VERSION ""

NS_ :

BS_:

BU_: CHUD_LS VKM_LS RCRM_LS MSM_RR_LS MSM_LR_LS CGM_LS BSM_LS VPM_LS ISRVM_LS DCAC_LS TouchPad_LS RSC_LS LVMPC_LS EOCM2B_K1_LS EOCM2A_K1_LS LCM_LS TIM_B_LS V2V_LS TCP_LS CSM_LS EOCM2B_K2_LS EOCM2A_K2_LS TIM_A_LS LVMNav_LS HFP_LS EDI_LS ARB_LS RSE_LS Dummy_LS VIS2_LS ICS_LS FCM_LS EOCM_F_LS VICM_LS AGC_LS MSM_P_LS OTIM_LS HVSM_R_LS HVSM_F_LS DVB_T_LS SBZA_R_LS PSD_R_LS PSD_L_LS UHP_Low UPA_LS STC_LS SBZA_L_LS PTM_LS ONSTAR_LS APA_LS TestTool_LS PHS_LS PDIM_LS CHM_LS RSA_LS AMP_LS HUD_LS MSM_LS HBSM_LS SCL_LS ECC_LS RadioHead_LS PEPS_LS IPC_LS AOS_LS SDM_LS TIM_LS BCM_LS

BO_ 2156298240 High_Volt_Batt_Time_Pwr_Chrg_LS: 8 VICM_LS
 SG_ HTRActvIndOn : 59|1@0+ (1,0) [0|1] ""  CGM_LS,IPC_LS
 SG_ HVBSTLPC_MntOfHr : 53|6@0+ (1,0) [0|63] "Minute"  BCM_LS,CGM_LS,CSM_LS,RadioHead_LS,IPC_LS
 SG_ HVBSTLPC_HrOfDy : 42|5@0+ (1,0) [0|31] "Hour"  BCM_LS,CGM_LS,CSM_LS,RadioHead_LS,IPC_LS
 SG_ HVBSTLPC_DyOfWk : 45|3@0+ (1,0) [0|7] ""  BCM_LS,CGM_LS,CSM_LS,RadioHead_LS,IPC_LS
 SG_ HVBSTHPC_MntOfHr : 35|6@0+ (1,0) [0|63] "Minute"  BCM_LS,CGM_LS,CSM_LS,RadioHead_LS,IPC_LS
 SG_ HVBSTHPC_HrOfDy : 24|5@0+ (1,0) [0|31] "Hour"  BCM_LS,CGM_LS,CSM_LS,RadioHead_LS,IPC_LS
 SG_ HVBSTHPC_DyOfWk : 27|3@0+ (1,0) [0|7] ""  BCM_LS,CGM_LS,CSM_LS,RadioHead_LS,IPC_LS
 SG_ HVBCTLPC_MntOfHr : 17|6@0+ (1,0) [0|63] "Minute"  BCM_LS,CGM_LS,CSM_LS,RadioHead_LS,IPC_LS
 SG_ HVBCTLPC_HrOfDy : 22|5@0+ (1,0) [0|31] "Hour"  BCM_LS,CGM_LS,CSM_LS,RadioHead_LS,IPC_LS
 SG_ HVBCTLPC_DyOfWk : 9|3@0+ (1,0) [0|7] ""  BCM_LS,CGM_LS,CSM_LS,RadioHead_LS,IPC_LS
 SG_ HVBCTHPC_MntOfHr : 15|6@0+ (1,0) [0|63] "Minute"  BCM_LS,CGM_LS,CSM_LS,RadioHead_LS,IPC_LS
 SG_ HVBCTHPC_HrOfDy : 4|5@0+ (1,0) [0|31] "Hour"  BCM_LS,CGM_LS,CSM_LS,RadioHead_LS,IPC_LS
 SG_ HVBCTHPC_DyOfWk : 7|3@0+ (1,0) [0|7] ""  BCM_LS,CGM_LS,CSM_LS,RadioHead_LS,IPC_LS
 SG_ InvldHMIEtrIO : 61|1@0+ (1,0) [0|1] ""  CGM_LS,CSM_LS,RadioHead_LS
 SG_ InsfcntTmTFlChrgIO : 60|1@0+ (1,0) [0|1] ""  CGM_LS,CSM_LS,RadioHead_LS
 SG_ HVBatChrgCrdAlrtReq : 63|2@0+ (1,0) [0|3] ""  CSM_LS,CGM_LS,RadioHead_LS,BCM_LS
 SG_ HVCSDTES_NPDTIO : 56|1@0+ (1,0) [0|1] ""  BCM_LS,CGM_LS,CSM_LS,RadioHead_LS
 SG_ HVCSDTES_LoPwrCIO : 58|1@0+ (1,0) [0|1] ""  BCM_LS,CGM_LS,CSM_LS,RadioHead_LS
 SG_ HVCSDTES_HiPwrCIO : 57|1@0+ (1,0) [0|1] ""  BCM_LS,CGM_LS,CSM_LS,RadioHead_LS

BO_ 2149924864 Drv_Pref_Mode_Switch_Status_LS: 8 BCM_LS
 SG_ PTOMobModTrnsInGrIO : 15|1@0+ (1,0) [0|1] ""  CGM_LS,IPC_LS
 SG_ a_12VBatSysUnstab : 55|1@0+ (1,0) [0|1] ""  IPC_LS,CGM_LS
 SG_ FwdClnMtgnBrkReqAct : 7|1@0+ (1,0) [0|1] ""  CGM_LS,FCM_LS
 SG_ TireRRLowTracIO : 54|1@0+ (1,0) [0|1] ""  CSM_LS,CGM_LS,IPC_LS
 SG_ TireRFLowTracIO : 53|1@0+ (1,0) [0|1] ""  CSM_LS,CGM_LS,IPC_LS
 SG_ TireLRLowTracIO : 52|1@0+ (1,0) [0|1] ""  CSM_LS,CGM_LS,IPC_LS
 SG_ TireLFLowTracIO : 51|1@0+ (1,0) [0|1] ""  CSM_LS,CGM_LS,IPC_LS
 SG_ HilRlbkCtrlActIO : 6|1@0+ (1,0) [0|1] ""  CGM_LS,IPC_LS
 SG_ FstIdlMdAct : 39|1@0+ (1,0) [0|1] ""  CGM_LS,IPC_LS
 SG_ DsplyPerfMdRq : 50|3@0+ (1,0) [0|7] ""  CGM_LS,IPC_LS
 SG_ DrvSelMd8Stat : 37|1@0+ (1,0) [0|1] ""  CSM_LS,RadioHead_LS,FCM_LS,CGM_LS,IPC_LS,ECC_LS
 SG_ DrvSelMd8ReqDnd : 38|1@0+ (1,0) [0|1] ""  CSM_LS,RadioHead_LS,CGM_LS,IPC_LS
 SG_ DrvSelMd7Stat : 35|1@0+ (1,0) [0|1] ""  CSM_LS,RadioHead_LS,FCM_LS,CGM_LS,IPC_LS,ECC_LS
 SG_ DrvSelMd7ReqDnd : 36|1@0+ (1,0) [0|1] ""  CSM_LS,RadioHead_LS,CGM_LS,IPC_LS
 SG_ DrvSelMd6Stat : 13|1@0+ (1,0) [0|1] ""  CSM_LS,RadioHead_LS,FCM_LS,CGM_LS,IPC_LS,ECC_LS
 SG_ DrvSelMd6ReqDnd : 14|1@0+ (1,0) [0|1] ""  CSM_LS,RadioHead_LS,CGM_LS,IPC_LS
 SG_ DrvSelMd5Stat : 11|1@0+ (1,0) [0|1] ""  CSM_LS,RadioHead_LS,FCM_LS,CGM_LS,IPC_LS,ECC_LS
 SG_ DrvSelMd5ReqDnd : 12|1@0+ (1,0) [0|1] ""  CGM_LS,IPC_LS,CSM_LS,RadioHead_LS
 SG_ DrvSelMd4Stat : 9|1@0+ (1,0) [0|1] ""  CSM_LS,RadioHead_LS,FCM_LS,CGM_LS,IPC_LS,ECC_LS
 SG_ DrvSelMd4ReqDnd : 10|1@0+ (1,0) [0|1] ""  CSM_LS,RadioHead_LS,CGM_LS,IPC_LS
 SG_ EDADS_RcmndtFwdGr : 43|4@0+ (1,0) [0|15] ""  CSM_LS,CGM_LS,IPC_LS
 SG_ EDADS_CrntFwdMsdG : 47|4@0+ (1,0) [0|15] ""  CSM_LS,CGM_LS,IPC_LS
 SG_ EDADS_ShftIndStat : 33|2@0+ (1,0) [0|3] ""  CSM_LS,CGM_LS,IPC_LS
 SG_ EDADS_EcoDrvShftIO : 34|1@0+ (1,0) [0|1] ""  CSM_LS,CGM_LS,IPC_LS
 SG_ DSMSS_DrvSelMd0Pn : 24|1@0+ (1,0) [0|1] ""  CGM_LS,CSM_LS,RadioHead_LS,IPC_LS
 SG_ DSMSS_DrvSelMd8Pn : 25|1@0+ (1,0) [0|1] ""  CGM_LS,CSM_LS,RadioHead_LS,IPC_LS
 SG_ DSMSS_DrvSelMd7Pn : 26|1@0+ (1,0) [0|1] ""  CGM_LS,CSM_LS,RadioHead_LS,IPC_LS
 SG_ DSMSS_DrvSelMd6Pn : 27|1@0+ (1,0) [0|1] ""  CGM_LS,CSM_LS,RadioHead_LS,IPC_LS
 SG_ DSMSS_DrvSelMd5Pn : 28|1@0+ (1,0) [0|1] ""  CGM_LS,CSM_LS,RadioHead_LS,IPC_LS
 SG_ DSMSS_DrvSelMd4Pn : 29|1@0+ (1,0) [0|1] ""  CGM_LS,CSM_LS,RadioHead_LS,IPC_LS
 SG_ DSMSS_DrvSelMd3Pn : 30|1@0+ (1,0) [0|1] ""  CGM_LS,CSM_LS,RadioHead_LS,IPC_LS
 SG_ DSMSS_DrvSelMd2Pn : 31|1@0+ (1,0) [0|1] ""  CGM_LS,CSM_LS,RadioHead_LS,IPC_LS
 SG_ DSMSS_DrvSelMd1Pn : 16|1@0+ (1,0) [0|1] ""  CGM_LS,CSM_LS,RadioHead_LS,IPC_LS
 SG_ DSMSS_DrvSelMd8Un : 17|1@0+ (1,0) [0|1] ""  CGM_LS,CSM_LS,RadioHead_LS,IPC_LS
 SG_ DSMSS_DrvSelMd7Un : 18|1@0+ (1,0) [0|1] ""  CGM_LS,CSM_LS,RadioHead_LS,IPC_LS
 SG_ DSMSS_DrvSelMd6Un : 19|1@0+ (1,0) [0|1] ""  CGM_LS,CSM_LS,RadioHead_LS,IPC_LS
 SG_ DSMSS_DrvSelMd5Un : 20|1@0+ (1,0) [0|1] ""  CGM_LS,CSM_LS,RadioHead_LS,IPC_LS
 SG_ DSMSS_DrvSelMd4Un : 21|1@0+ (1,0) [0|1] ""  CGM_LS,CSM_LS,RadioHead_LS,IPC_LS
 SG_ DSMSS_DrvSelMd3Un : 22|1@0+ (1,0) [0|1] ""  CGM_LS,CSM_LS,RadioHead_LS,IPC_LS
 SG_ DSMSS_DrvSelMd2Un : 23|1@0+ (1,0) [0|1] ""  CGM_LS,CSM_LS,RadioHead_LS,IPC_LS
 SG_ DSMSS_DrvSelMd1Un : 8|1@0+ (1,0) [0|1] ""  CGM_LS,CSM_LS,RadioHead_LS,IPC_LS
 SG_ DrvSelMd3Stat : 4|1@0+ (1,0) [0|1] ""  FCM_LS,CGM_LS,CSM_LS,RadioHead_LS,BSM_LS,VICM_LS,IPC_LS,ECC_LS
 SG_ DrvSelMd3ReqDnd : 5|1@0+ (1,0) [0|1] ""  CSM_LS,RadioHead_LS,CGM_LS,IPC_LS
 SG_ DrvSelMd2Stat : 2|1@0+ (1,0) [0|1] ""  FCM_LS,CGM_LS,CSM_LS,RadioHead_LS,BSM_LS,VICM_LS,IPC_LS,ECC_LS
 SG_ DrvSelMd2ReqDnd : 3|1@0+ (1,0) [0|1] ""  CGM_LS,IPC_LS,CSM_LS,RadioHead_LS
 SG_ DrvSelMd1Stat : 0|1@0+ (1,0) [0|1] ""  FCM_LS,CGM_LS,CSM_LS,RadioHead_LS,BSM_LS,VICM_LS,IPC_LS,ECC_LS
 SG_ DrvSelMd1ReqDnd : 1|1@0+ (1,0) [0|1] ""  CGM_LS,CSM_LS,RadioHead_LS,IPC_LS
 SG_ CPSCA_Resrv3Avail : 56|1@0+ (1,0) [0|1] ""  CGM_LS,CSM_LS,RadioHead_LS
 SG_ CPSCA_Resrv2Avail : 57|1@0+ (1,0) [0|1] ""  CGM_LS,CSM_LS,RadioHead_LS
 SG_ CPSCA_Resrv1Avail : 58|1@0+ (1,0) [0|1] ""  CGM_LS,CSM_LS,RadioHead_LS
 SG_ CPSCA_AlrtBrkStrAvail : 59|1@0+ (1,0) [0|1] ""  CGM_LS,CSM_LS,RadioHead_LS
 SG_ CPSCA_AlrtBrkAvail : 60|1@0+ (1,0) [0|1] ""  CGM_LS,CSM_LS,RadioHead_LS
 SG_ CPSCA_AlrtAvail : 61|1@0+ (1,0) [0|1] ""  CGM_LS,CSM_LS,RadioHead_LS
 SG_ CPSCA_OffAvail : 62|1@0+ (1,0) [0|1] ""  CGM_LS,CSM_LS,RadioHead_LS

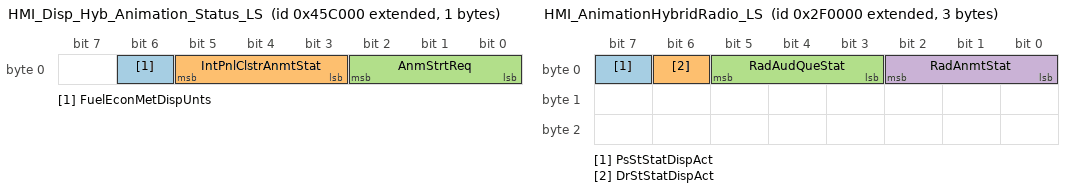
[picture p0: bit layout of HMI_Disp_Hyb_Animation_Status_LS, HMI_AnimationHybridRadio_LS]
BO_ 2152054784 HMI_Disp_Hyb_Animation_Status_LS: 1 IPC_LS
 SG_ FuelEconMetDispUnts : 6|1@0+ (1,0) [0|1] ""  RadioHead_LS,BSM_LS,VICM_LS
 SG_ IntPnlClstrAnmtStat : 5|3@0+ (1,0) [0|7] ""  RadioHead_LS,CHUD_LS,HUD_LS
 SG_ AnmStrtReq : 2|3@0+ (1,0) [0|7] ""  RadioHead_LS,CHUD_LS,HUD_LS

BO_ 2150301696 HMI_Animation_Initiator_LS: 1 BCM_LS
 SG_ WlcAnmReq : 0|1@0+ (1,0) [0|1] ""  CGM_LS,RadioHead_LS,IPC_LS

BO_ 2150563840 HMI_AnimationHybridRadio_LS: 3 RadioHead_LS
 SG_ PsStStatDispAct : 7|1@0+ (1,0) [0|1] ""  MSM_P_LS
 SG_ DrStStatDispAct : 6|1@0+ (1,0) [0|1] ""  MSM_LS
 SG_ RadAudQueStat : 5|3@0+ (1,0) [0|7] "" Vector__XXX
 SG_ RadAnmtStat : 2|3@0+ (1,0) [0|7] "" Vector__XXX

BO_ 2154758144 Auxiliary_Heater_Active_LS: 1 BCM_LS
 SG_ ChldLckOtSwAct : 1|1@0+ (1,0) [0|1] ""  CGM_LS,MSM_LR_LS,MSM_RR_LS

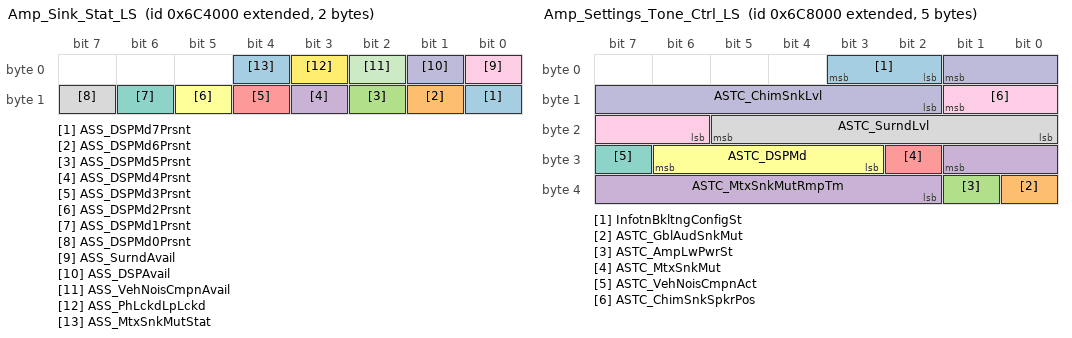
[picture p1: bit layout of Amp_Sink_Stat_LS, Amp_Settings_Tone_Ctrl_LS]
BO_ 2154577920 Amp_Sink_Stat_LS: 2 AMP_LS
 SG_ ASS_DSPMd7Prsnt : 8|1@0+ (1,0) [0|1] ""  CGM_LS,CSM_LS
 SG_ ASS_DSPMd6Prsnt : 9|1@0+ (1,0) [0|1] ""  CGM_LS,CSM_LS
 SG_ ASS_DSPMd5Prsnt : 10|1@0+ (1,0) [0|1] ""  CGM_LS,CSM_LS
 SG_ ASS_DSPMd4Prsnt : 11|1@0+ (1,0) [0|1] ""  CGM_LS,CSM_LS
 SG_ ASS_DSPMd3Prsnt : 12|1@0+ (1,0) [0|1] ""  CGM_LS,CSM_LS
 SG_ ASS_DSPMd2Prsnt : 13|1@0+ (1,0) [0|1] ""  CGM_LS,CSM_LS
 SG_ ASS_DSPMd1Prsnt : 14|1@0+ (1,0) [0|1] ""  CGM_LS,CSM_LS
 SG_ ASS_DSPMd0Prsnt : 15|1@0+ (1,0) [0|1] ""  CGM_LS,CSM_LS
 SG_ ASS_SurndAvail : 0|1@0+ (1,0) [0|1] ""  CGM_LS,CSM_LS
 SG_ ASS_DSPAvail : 1|1@0+ (1,0) [0|1] ""  CGM_LS,CSM_LS
 SG_ ASS_VehNoisCmpnAvail : 2|1@0+ (1,0) [0|1] ""  CGM_LS,CSM_LS
 SG_ ASS_PhLckdLpLckd : 3|1@0+ (1,0) [0|1] ""  CGM_LS,CSM_LS
 SG_ ASS_MtxSnkMutStat : 4|1@0+ (1,0) [0|1] ""  CGM_LS,CSM_LS

BO_ 2154594304 Amp_Settings_Tone_Ctrl_LS: 5 CSM_LS
 SG_ InfotnBkltngConfigSt : 3|2@0+ (1,0) [0|3] ""  CGM_LS,RSE_LS,TouchPad_LS
 SG_ ASTC_GblAudSnkMut : 32|1@0+ (1,0) [0|1] ""  CGM_LS,AMP_LS
 SG_ ASTC_AmpLwPwrSt : 33|1@0+ (1,0) [0|1] ""  CGM_LS,AMP_LS
 SG_ ASTC_MtxSnkMutRmpTm : 25|8@0+ (5,0) [0|1275] "ms"  CGM_LS,AMP_LS
 SG_ ASTC_MtxSnkMut : 26|1@0+ (1,0) [0|1] ""  CGM_LS,AMP_LS
 SG_ ASTC_DSPMd : 30|4@0+ (1,0) [0|15] ""  CGM_LS,AMP_LS
 SG_ ASTC_VehNoisCmpnAct : 31|1@0+ (1,0) [0|1] ""  CGM_LS,AMP_LS
 SG_ ASTC_SurndLvl : 21|6@0- (1,0) [-32|31] ""  CGM_LS,AMP_LS
 SG_ ASTC_ChimSnkSpkrPos : 9|4@0+ (1,0) [0|15] ""  CGM_LS,AMP_LS
 SG_ ASTC_ChimSnkLvl : 1|8@0+ (0.5,-127.5) [-127.5|0] "dB"  CGM_LS,AMP_LS

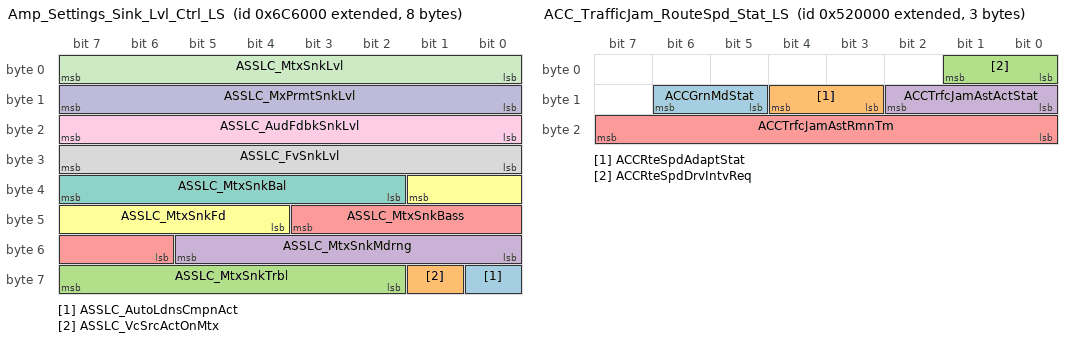
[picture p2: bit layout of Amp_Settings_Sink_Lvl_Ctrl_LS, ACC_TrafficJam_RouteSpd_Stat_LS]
BO_ 2154586112 Amp_Settings_Sink_Lvl_Ctrl_LS: 8 CSM_LS
 SG_ ASSLC_AutoLdnsCmpnAct : 56|1@0+ (1,0) [0|1] ""  CGM_LS,AMP_LS
 SG_ ASSLC_VcSrcActOnMtx : 57|1@0+ (1,0) [0|1] ""  CGM_LS,AMP_LS
 SG_ ASSLC_MtxSnkTrbl : 63|6@0- (1,0) [-32|31] ""  CGM_LS,AMP_LS
 SG_ ASSLC_MtxSnkMdrng : 53|6@0- (1,0) [-32|31] ""  CGM_LS,AMP_LS
 SG_ ASSLC_MtxSnkBass : 43|6@0- (1,0) [-32|31] ""  CGM_LS,AMP_LS
 SG_ ASSLC_MtxSnkFd : 33|6@0- (1,0) [-32|31] ""  CGM_LS,AMP_LS
 SG_ ASSLC_MtxSnkBal : 39|6@0- (1,0) [-32|31] ""  CGM_LS,AMP_LS
 SG_ ASSLC_FvSnkLvl : 31|8@0+ (0.5,-127.5) [-127.5|0] "dB"  CGM_LS,AMP_LS
 SG_ ASSLC_AudFdbkSnkLvl : 23|8@0+ (0.5,-127.5) [-127.5|0] "dB"  CGM_LS,AMP_LS
 SG_ ASSLC_MxPrmtSnkLvl : 15|8@0+ (0.5,-127.5) [-127.5|0] "dB"  CGM_LS,AMP_LS
 SG_ ASSLC_MtxSnkLvl : 7|8@0+ (0.5,-127.5) [-127.5|0] "dB"  CGM_LS,AMP_LS

BO_ 2152857600 ACC_TrafficJam_RouteSpd_Stat_LS: 3 FCM_LS
 SG_ ACCGrnMdStat : 14|2@0+ (1,0) [0|3] ""  CSM_LS,ONSTAR_LS,CGM_LS,IPC_LS
 SG_ ACCRteSpdAdaptStat : 12|2@0+ (1,0) [0|3] ""  CSM_LS,CGM_LS,IPC_LS
 SG_ ACCRteSpdDrvIntvReq : 1|2@0+ (1,0) [0|3] ""  CGM_LS,IPC_LS
 SG_ ACCTrfcJamAstActStat : 10|3@0+ (1,0) [0|7] ""  CGM_LS,IPC_LS
 SG_ ACCTrfcJamAstRmnTm : 23|8@0+ (1,0) [0|255] "sec"  CGM_LS,IPC_LS

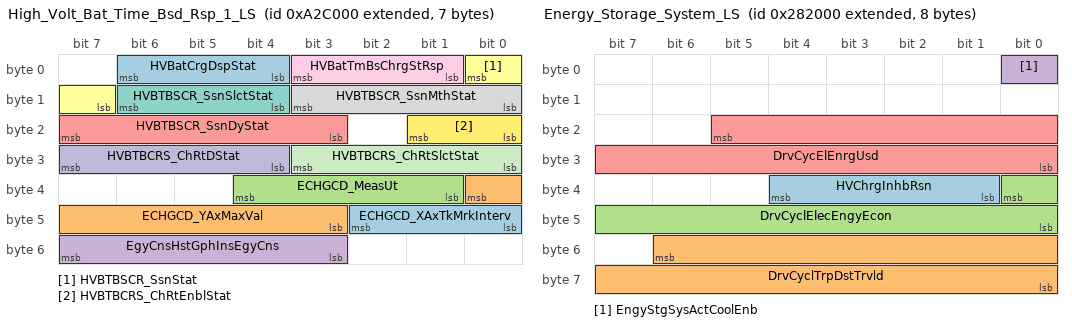
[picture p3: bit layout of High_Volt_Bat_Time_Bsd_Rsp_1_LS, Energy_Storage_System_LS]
BO_ 2158149632 High_Volt_Bat_Time_Bsd_Rsp_1_LS: 7 VICM_LS
 SG_ ECHGCD_XAxTkMrkInterv : 42|3@0+ (1,0) [0|7] ""  CSM_LS,RadioHead_LS,CGM_LS
 SG_ ECHGCD_YAxMaxVal : 32|6@0+ (4,0) [0|252] ""  CSM_LS,RadioHead_LS,CGM_LS
 SG_ ECHGCD_MeasUt : 36|4@0+ (1,0) [0|15] ""  CSM_LS,RadioHead_LS,CGM_LS
 SG_ EgyCnsHstGphInsEgyCns : 55|5@0+ (1,0) [0|31] ""  CGM_LS,CSM_LS,RadioHead_LS
 SG_ HVBTBSCR_SsnDyStat : 23|5@0+ (1,0) [0|31] "day"  CGM_LS,CSM_LS,RadioHead_LS
 SG_ HVBTBSCR_SsnStat : 0|2@0+ (1,0) [0|3] ""  CGM_LS,CSM_LS,RadioHead_LS
 SG_ HVBTBSCR_SsnSlctStat : 14|3@0+ (1,0) [0|7] ""  CGM_LS,CSM_LS,RadioHead_LS
 SG_ HVBTBSCR_SsnMthStat : 11|4@0+ (1,0) [0|15] ""  CGM_LS,CSM_LS,RadioHead_LS
 SG_ HVBatTmBsChrgStRsp : 3|3@0+ (1,0) [0|7] ""  BCM_LS,CGM_LS,CSM_LS,RadioHead_LS
 SG_ HVBTBCRS_ChRtDStat : 31|4@0+ (1,0) [0|15] ""  CGM_LS,CSM_LS,RadioHead_LS
 SG_ HVBTBCRS_ChRtSlctStat : 27|4@0+ (1,0) [0|15] ""  CGM_LS,CSM_LS,RadioHead_LS
 SG_ HVBTBCRS_ChRtEnblStat : 17|2@0+ (1,0) [0|3] ""  CGM_LS,CSM_LS,RadioHead_LS
 SG_ HVBatCrgDspStat : 6|3@0+ (1,0) [0|7] ""  CSM_LS,CGM_LS,RadioHead_LS,BCM_LS

BO_ 2158116864 High_Volt_Bat_Time_Bsd_Rsp_LS: 8 VICM_LS
 SG_ SrvcHghVltBatIndReq : 37|2@0+ (1,0) [0|3] ""  CGM_LS,IPC_LS
 SG_ ChrgStPkInScnActIO : 35|1@0+ (1,0) [0|1] ""  IPC_LS,CGM_LS
 SG_ HVBatStrtTmDspFrmt : 15|3@0+ (1,0) [0|7] ""  CSM_LS,RadioHead_LS,CGM_LS
 SG_ OBHVBCMinsRmng : 5|6@0+ (1,0) [0|63] ""  CSM_LS,RadioHead_LS,IPC_LS,CGM_LS
 SG_ OBHVBCCompTmDispFrmt : 7|2@0+ (1,0) [0|3] ""  CSM_LS,RadioHead_LS,IPC_LS,CGM_LS
 SG_ HVBTBRCR_RtCHSlctTblRwStat : 58|3@0+ (1,0) [0|7] "rows"  CGM_LS,CSM_LS,RadioHead_LS
 SG_ HVBTBRCR_RtChSlctStat : 42|3@0+ (1,0) [0|7] ""  CGM_LS,CSM_LS,RadioHead_LS
 SG_ HVBTBRCR_RtChSlRtStat : 62|4@0+ (1,0) [0|15] ""  CGM_LS,CSM_LS,RadioHead_LS
 SG_ HVBTBRCR_RtChSsnStat : 34|2@0+ (1,0) [0|3] ""  CGM_LS,CSM_LS,RadioHead_LS
 SG_ HVBTBRCR_RtChMHRsp : 32|6@0+ (1,0) [0|63] "min"  CGM_LS,CSM_LS,RadioHead_LS
 SG_ HVBTBRCR_RtChHRsp : 55|5@0+ (1,0) [0|31] "hr"  CGM_LS,CSM_LS,RadioHead_LS
 SG_ HVBTBRCR_RtChDStat : 50|4@0+ (1,0) [0|15] ""  CGM_LS,CSM_LS,RadioHead_LS
 SG_ HVBTBDCRS_DlChSlctStat : 19|4@0+ (1,0) [0|15] ""  BCM_LS,CGM_LS,CSM_LS,RadioHead_LS
 SG_ HVBTBDCRS_DlChSsnStat : 31|2@0+ (1,0) [0|3] ""  BCM_LS,CGM_LS,CSM_LS,RadioHead_LS
 SG_ HVBTBDCRS_DlChMHRsp : 29|6@0+ (1,0) [0|63] "min"  BCM_LS,CGM_LS,CSM_LS,RadioHead_LS
 SG_ HVBTBDCRS_DlChHRsp : 12|5@0+ (1,0) [0|31] "hr"  BCM_LS,CGM_LS,CSM_LS,RadioHead_LS
 SG_ HVBTBDCRS_DlChDStat : 23|4@0+ (1,0) [0|15] ""  BCM_LS,CGM_LS,CSM_LS,RadioHead_LS

BO_ 2156281856 High_Volt_Bat_Time_Bsd_Req_1_LS: 7 RadioHead_LS
 SG_ LftmEffDtRstRqd : 18|1@0+ (1,0) [0|1] ""  VICM_LS
 SG_ HTRCsStReq : 37|3@0+ (1,0) [0|7] ""  VICM_LS
 SG_ TODCTmpImdtOvrdReq : 39|2@0+ (1,0) [0|3] ""  BSM_LS,VICM_LS
 SG_ RtBsChrgCmplnTmPrfReq : 34|2@0+ (1,0) [0|3] ""  BSM_LS,VICM_LS
 SG_ TONPDTR_StTmpOvrAtv : 32|2@0+ (1,0) [0|3] ""  BSM_LS,VICM_LS
 SG_ TONPDTR_MntOfHr : 53|6@0+ (1,0) [0|63] "Minute"  BSM_LS,VICM_LS
 SG_ TONPDTR_HrOfDy : 42|5@0+ (1,0) [0|31] "Hour"  BSM_LS,VICM_LS
 SG_ TONPDTR_DyOfWk : 46|4@0+ (1,0) [0|15] ""  BSM_LS,VICM_LS
 SG_ StTODChrgTmpOvrd : 7|1@0+ (1,0) [0|1] ""  BSM_LS,VICM_LS
 SG_ HVBTBSCSR_SsnStReq : 0|2@0+ (1,0) [0|3] ""  BSM_LS,VICM_LS
 SG_ HVBTBSCSR_SsnSlStReq : 14|3@0+ (1,0) [0|7] ""  BSM_LS,VICM_LS
 SG_ HVBTBSCSR_SsnMthStReq : 11|4@0+ (1,0) [0|15] ""  BSM_LS,VICM_LS
 SG_ HVBTBSCSR_SsnDayStReq : 23|5@0+ (1,0) [0|31] "day"  BSM_LS,VICM_LS
 SG_ HVBTBCRSR_ChRtSlStReq : 27|4@0+ (1,0) [0|15] ""  BSM_LS,VICM_LS
 SG_ HVBTBCRSR_ChRtEnblStReq : 17|2@0+ (1,0) [0|3] ""  BSM_LS,VICM_LS
 SG_ HVBTBCRSR_ChRtDStReq : 31|4@0+ (1,0) [0|15] ""  BSM_LS,VICM_LS
 SG_ HVBatTmBsChrgMdReq : 3|3@0+ (1,0) [0|7] ""  BSM_LS,VICM_LS
 SG_ HVChgSyChgLvlPrfSt : 6|3@0+ (1,0) [0|7] ""  BSM_LS,VICM_LS

BO_ 2156265472 High_Volt_Bat_Time_Bsd_Req_LS: 8 RadioHead_LS
 SG_ EngyUsgScrnMeasUtStat : 39|4@0+ (1,0) [0|15] ""  BSM_LS,VICM_LS
 SG_ OffBrdHVCVehCsChRq : 35|1@0+ (1,0) [0|1] ""  BSM_LS,VICM_LS
 SG_ PrtyChrgRq : 7|2@0+ (1,0) [0|3] ""  BSM_LS,VICM_LS
 SG_ HVBTBRCSR_RtChSlStReq : 42|3@0+ (1,0) [0|7] ""  BSM_LS,VICM_LS
 SG_ HVBTBRCSR_RtChSlRtStReq : 46|4@0+ (1,0) [0|15] ""  BSM_LS,VICM_LS
 SG_ HVBTBRCSR_RtChSsnStReq : 50|2@0+ (1,0) [0|3] ""  BSM_LS,VICM_LS
 SG_ HVBTBRCSR_RtChMHStReq : 48|6@0+ (1,0) [0|63] "min"  BSM_LS,VICM_LS
 SG_ HVBTBRCSR_RtChHStReq : 55|5@0+ (1,0) [0|31] "hr"  BSM_LS,VICM_LS
 SG_ HVBTBRCSR_RtChDStReq : 34|4@0+ (1,0) [0|15] ""  BSM_LS,VICM_LS
 SG_ HVBTBRCSR_RtChSlTbRwReq : 58|3@0+ (1,0) [0|7] "rows"  BSM_LS,VICM_LS
 SG_ HVBTBDCSRQ_DlChSlStReq : 19|4@0+ (1,0) [0|15] ""  BSM_LS,VICM_LS
 SG_ HVBTBDCSRQ_DlChSsnStReq : 31|2@0+ (1,0) [0|3] ""  BSM_LS,VICM_LS
 SG_ HVBTBDCSRQ_DlChMHStReq : 29|6@0+ (1,0) [0|63] "min"  BSM_LS,VICM_LS
 SG_ HVBTBDCSRQ_DlChHStReq : 12|5@0+ (1,0) [0|31] "hr"  BSM_LS,VICM_LS
 SG_ HVBTBDCSRQ_DlChDStReq : 23|4@0+ (1,0) [0|15] ""  BSM_LS,VICM_LS
 SG_ ChgPwLsAlCzStRq : 5|3@0+ (1,0) [0|7] ""  BSM_LS,VICM_LS
 SG_ ChgCdTfAlCzStRq : 2|3@0+ (1,0) [0|7] ""  BSM_LS,VICM_LS
 SG_ ChgSysAudInCsStReq : 15|3@0+ (1,0) [0|7] ""  BSM_LS,VICM_LS

BO_ 2150113280 Energy_Storage_System_LS: 8 VICM_LS
 SG_ HVChrgInhbRsn : 36|4@0+ (1,0) [0|15] ""  IPC_LS,CGM_LS
 SG_ DrvCyclTrpDstTrvld : 54|15@0+ (0.1,0) [0|3276.7] "km"  CSM_LS,ONSTAR_LS,CGM_LS,IPC_LS
 SG_ DrvCyclElecEngyEcon : 32|9@0+ (0.1,0) [0|51.1] ""  CSM_LS,ONSTAR_LS,CGM_LS,IPC_LS
 SG_ EngyStgSysActCoolEnb : 0|1@0+ (1,0) [0|1] ""  CGM_LS,IPC_LS,CSM_LS,RadioHead_LS,ECC_LS,BCM_LS
 SG_ DrvCycElEnrgUsd : 21|14@0+ (0.36,0) [0|5897.88] "MJ"  CGM_LS,CSM_LS,RadioHead_LS

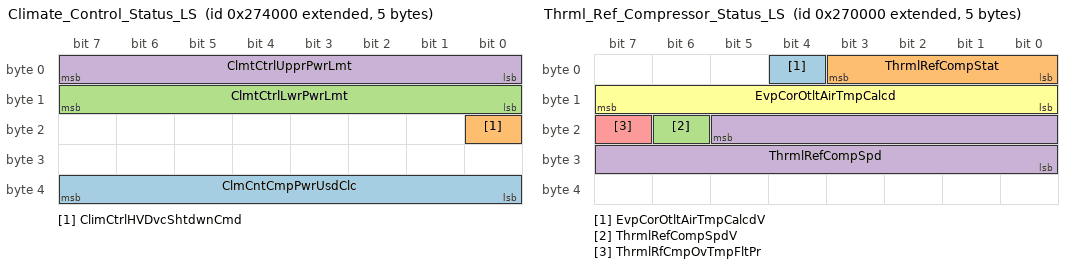
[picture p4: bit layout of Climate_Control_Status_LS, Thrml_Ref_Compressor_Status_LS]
BO_ 2150055936 Climate_Control_Status_LS: 5 VICM_LS
 SG_ ClmCntCmpPwrUsdClc : 39|8@0+ (0.04,0) [0|10.2] "kW"  CGM_LS,ECC_LS
 SG_ ClimCtrlHVDvcShtdwnCmd : 16|1@0+ (1,0) [0|1] ""  CGM_LS,ECC_LS
 SG_ ClmtCtrlLwrPwrLmt : 15|8@0+ (0.1,0) [0|25.5] "kW"  CGM_LS,ECC_LS
 SG_ ClmtCtrlUpprPwrLmt : 7|8@0+ (0.1,0) [0|25.5] "kW"  CGM_LS,ECC_LS

BO_ 2150039552 Thrml_Ref_Compressor_Status_LS: 5 VICM_LS
 SG_ EvpCorOtltAirTmpCalcdV : 4|1@0+ (1,0) [0|1] ""  CGM_LS,ECC_LS
 SG_ ThrmlRefCompStat : 3|4@0+ (1,0) [0|15] ""  CGM_LS,ECC_LS
 SG_ ThrmlRefCompSpdV : 22|1@0+ (1,0) [0|1] ""  CGM_LS,ECC_LS
 SG_ ThrmlRefCompSpd : 21|14@0+ (1,0) [0|16383] "rpm"  CGM_LS,ECC_LS
 SG_ ThrmlRfCmpOvTmpFltPr : 23|1@0+ (1,0) [0|1] ""  CGM_LS,ECC_LS
 SG_ EvpCorOtltAirTmpCalcd : 15|8@0+ (0.5,-40) [-40|87.5] "deg C"  CGM_LS,ECC_LS

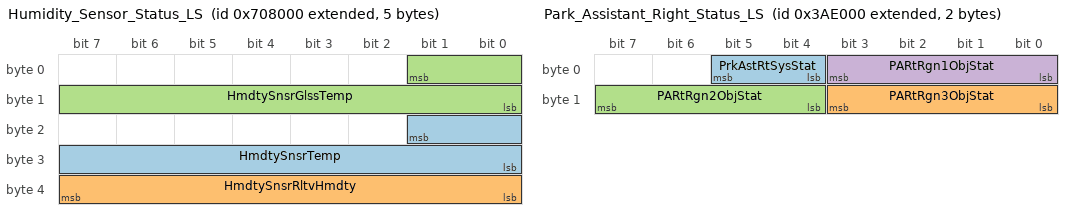
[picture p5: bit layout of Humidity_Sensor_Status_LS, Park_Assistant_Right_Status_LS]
BO_ 2154856448 Humidity_Sensor_Status_LS: 5 BCM_LS
 SG_ HmdtySnsrTemp : 17|10@0+ (0.146628,-50) [-50|100.000444] "deg C"  CSM_LS,CGM_LS,RadioHead_LS,BSM_LS,VICM_LS,ECC_LS
 SG_ HmdtySnsrRltvHmdty : 39|8@0+ (0.392157,0) [0|100.000035] "%"  CSM_LS,CGM_LS,RadioHead_LS,BSM_LS,VICM_LS,ECC_LS
 SG_ HmdtySnsrGlssTemp : 1|10@0+ (0.146628,-50) [-50|100.000444] "deg C"  CSM_LS,CGM_LS,RadioHead_LS,ECC_LS

BO_ 2151342080 Park_Assistant_Right_Status_LS: 2 APA_LS
 SG_ PrkAstRtSysStat : 5|2@0+ (1,0) [0|3] ""  CGM_LS,IPC_LS
 SG_ PARtRgn3ObjStat : 11|4@0+ (1,0) [0|15] ""  CGM_LS,IPC_LS
 SG_ PARtRgn2ObjStat : 15|4@0+ (1,0) [0|15] ""  CGM_LS,IPC_LS
 SG_ PARtRgn1ObjStat : 3|4@0+ (1,0) [0|15] ""  CGM_LS,IPC_LS

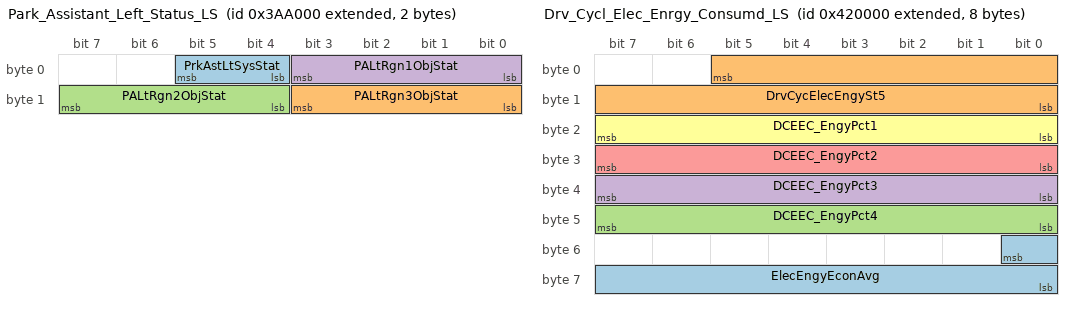
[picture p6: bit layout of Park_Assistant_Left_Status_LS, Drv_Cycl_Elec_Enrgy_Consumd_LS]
BO_ 2151325696 Park_Assistant_Left_Status_LS: 2 APA_LS
 SG_ PrkAstLtSysStat : 5|2@0+ (1,0) [0|3] ""  CGM_LS,IPC_LS
 SG_ PALtRgn3ObjStat : 11|4@0+ (1,0) [0|15] ""  CGM_LS,IPC_LS
 SG_ PALtRgn2ObjStat : 15|4@0+ (1,0) [0|15] ""  CGM_LS,IPC_LS
 SG_ PALtRgn1ObjStat : 3|4@0+ (1,0) [0|15] ""  CGM_LS,IPC_LS

BO_ 2151809024 Drv_Cycl_Elec_Enrgy_Consumd_LS: 8 VICM_LS
 SG_ ElecEngyEconAvg : 48|9@0+ (0.1,0) [0|51.1] ""  CSM_LS,ONSTAR_LS,CGM_LS,IPC_LS
 SG_ DrvCycElecEngySt5 : 5|14@0+ (0.36,0) [0|5897.88] "MJ"  CGM_LS,CSM_LS,RadioHead_LS
 SG_ DCEEC_EngyPct4 : 47|8@0+ (0.392157,0) [0|100.000035] "%"  CGM_LS,CSM_LS,RadioHead_LS
 SG_ DCEEC_EngyPct3 : 39|8@0+ (0.392157,0) [0|100.000035] "%"  CGM_LS,CSM_LS,RadioHead_LS
 SG_ DCEEC_EngyPct2 : 31|8@0+ (0.392157,0) [0|100.000035] "%"  CGM_LS,CSM_LS,RadioHead_LS
 SG_ DCEEC_EngyPct1 : 23|8@0+ (0.392157,0) [0|100.000035] "%"  CGM_LS,CSM_LS,RadioHead_LS

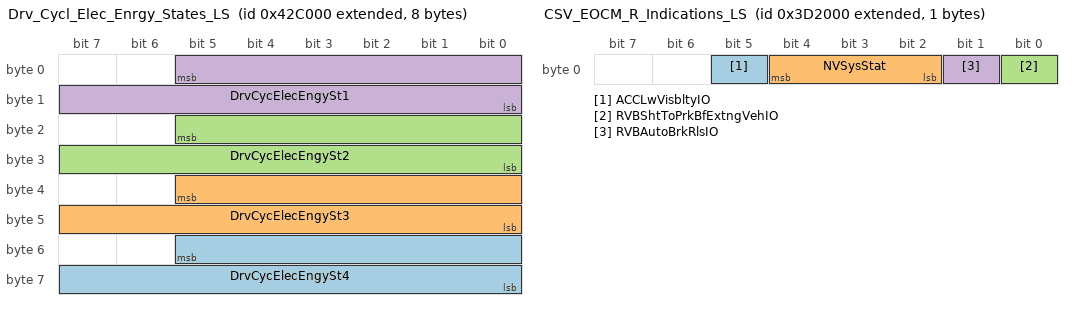
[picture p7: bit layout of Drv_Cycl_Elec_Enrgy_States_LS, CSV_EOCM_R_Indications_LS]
BO_ 2151858176 Drv_Cycl_Elec_Enrgy_States_LS: 8 VICM_LS
 SG_ DrvCycElecEngySt4 : 53|14@0+ (0.36,0) [0|5897.88] "MJ"  CGM_LS,CSM_LS,RadioHead_LS
 SG_ DrvCycElecEngySt3 : 37|14@0+ (0.36,0) [0|5897.88] "MJ"  CGM_LS,CSM_LS,RadioHead_LS
 SG_ DrvCycElecEngySt2 : 21|14@0+ (0.36,0) [0|5897.88] "MJ"  CGM_LS,CSM_LS,RadioHead_LS
 SG_ DrvCycElecEngySt1 : 5|14@0+ (0.36,0) [0|5897.88] "MJ"  CGM_LS,CSM_LS,RadioHead_LS

BO_ 2150547456 HMI_Hybrid_Vehicle_Status_LS: 8 VICM_LS
 SG_ HVDpltnMdCnfdcTrndg : 47|8@0- (0.787402,0) [-100.787456|100.000054] "%"  CSM_LS,ONSTAR_LS,CGM_LS,IPC_LS
 SG_ OffBrdHVCVehPwrLvl : 55|2@0+ (1,0) [0|3] ""  CGM_LS,CSM_LS,RadioHead_LS
 SG_ OffBrdHVCVehPwrDrtd : 26|1@0+ (1,0) [0|1] ""  CGM_LS,CSM_LS,RadioHead_LS
 SG_ OffBrdHVCVehCplrLkd : 16|1@0+ (1,0) [0|1] ""  CGM_LS,CSM_LS,RadioHead_LS
 SG_ OffBrdHVBlkChrgCmp : 37|1@0+ (1,0) [0|1] ""  CSM_LS,ONSTAR_LS,CGM_LS,IPC_LS
 SG_ OBHVBCCT_MinofHr : 61|6@0+ (1,0) [0|63] ""  CGM_LS,IPC_LS,CSM_LS,RadioHead_LS
 SG_ OBHVBCCT_HrofDay : 50|5@0+ (1,0) [0|31] ""  CGM_LS,IPC_LS,CSM_LS,RadioHead_LS
 SG_ OBHVBCCT_DayofWk : 53|3@0+ (1,0) [0|7] ""  CGM_LS,IPC_LS,CSM_LS,RadioHead_LS
 SG_ ElecPrplsnMtrOvrSpdIO : 38|1@0+ (1,0) [0|1] ""  CGM_LS,IPC_LS
 SG_ HVBatOutOfEnrgyInd : 36|3@0+ (1,0) [0|7] ""  CSM_LS,CGM_LS,RadioHead_LS,IPC_LS
 SG_ CntrsOpnUndrTmpIO : 7|1@0+ (1,0) [0|1] ""  CSM_LS,CGM_LS,RadioHead_LS,IPC_LS
 SG_ HVBatCntctrsOpnIO : 39|1@0+ (1,0) [0|1] ""  CSM_LS,ONSTAR_LS,CGM_LS,IPC_LS
 SG_ GrnAudQueReq : 4|1@0+ (1,0) [0|1] ""  CSM_LS,CGM_LS,RadioHead_LS
 SG_ SvcHybChrgSysIO : 5|1@0+ (1,0) [0|1] ""  CSM_LS,CGM_LS,RadioHead_LS,IPC_LS
 SG_ HVChrgrSysStat : 29|3@0+ (1,0) [0|7] ""  TCP_LS,CGM_LS,CSM_LS,RadioHead_LS,IPC_LS,ONSTAR_LS
 SG_ HVChrgrCplrStat : 31|2@0+ (1,0) [0|3] ""  ECC_LS,CSM_LS,TCP_LS,CGM_LS,RadioHead_LS,ONSTAR_LS
 SG_ HVBatLimDTmpInd : 25|2@0+ (1,0) [0|3] ""  CSM_LS,CGM_LS,RadioHead_LS,IPC_LS
 SG_ HVBatChrgCrdConnIO : 6|1@0+ (1,0) [0|1] ""  BCM_LS,CSM_LS,TCP_LS,CGM_LS,RadioHead_LS,ONSTAR_LS,IPC_LS
 SG_ VehChrgMdSt : 3|3@0+ (1,0) [0|7] ""  CSM_LS,TCP_LS,CGM_LS,RadioHead_LS,ONSTAR_LS,IPC_LS
 SG_ HVDpltnMdRng : 0|16@0+ (0.015625,0) [0|1023.984375] "km"  BCM_LS,TCP_LS,CGM_LS,ONSTAR_LS,CSM_LS,RadioHead_LS,IPC_LS
 SG_ ChgrSysAdblIndReq : 33|2@0+ (1,0) [0|3] ""  CSM_LS,CGM_LS,RadioHead_LS,BCM_LS

BO_ 2151489536 CSV_EOCM_R_Indications_LS: 1 EOCM_F_LS
 SG_ ACCLwVisbltyIO : 5|1@0+ (1,0) [0|1] ""  CGM_LS,IPC_LS
 SG_ NVSysStat : 4|3@0+ (1,0) [0|7] ""  CGM_LS,IPC_LS
 SG_ RVBShtToPrkBfExtngVehIO : 0|1@0+ (1,0) [0|1] ""  CGM_LS,IPC_LS
 SG_ RVBAutoBrkRlsIO : 1|1@0+ (1,0) [0|1] ""  CGM_LS,IPC_LS

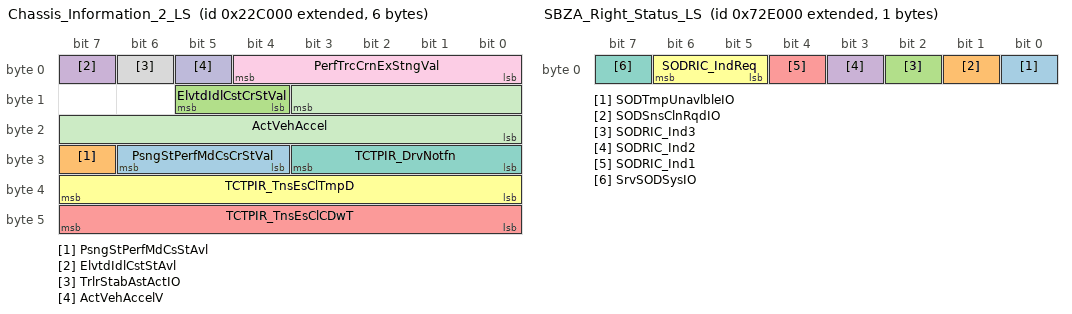
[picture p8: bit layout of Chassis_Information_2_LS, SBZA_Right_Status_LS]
BO_ 2149761024 Chassis_Information_2_LS: 6 BCM_LS
 SG_ PsngStPerfMdCsCrStVal : 30|3@0+ (1,0) [0|7] ""  CGM_LS,CSM_LS,RadioHead_LS
 SG_ PsngStPerfMdCsStAvl : 31|1@0+ (1,0) [0|1] ""  CGM_LS,CSM_LS,RadioHead_LS
 SG_ ElvtdIdlCstCrStVal : 13|2@0+ (1,0) [0|3] ""  CGM_LS,IPC_LS,CSM_LS,RadioHead_LS
 SG_ ElvtdIdlCstStAvl : 7|1@0+ (1,0) [0|1] ""  CGM_LS,CSM_LS,RadioHead_LS
 SG_ TCTPIR_TnsEsClCDwT : 47|8@0+ (0.392157,0) [0|100.000035] "%"  CGM_LS,IPC_LS
 SG_ TCTPIR_TnsEsClTmpD : 39|8@0+ (0.392157,0) [0|100.000035] "%"  CGM_LS,IPC_LS
 SG_ TCTPIR_DrvNotfn : 27|4@0+ (1,0) [0|15] ""  CGM_LS,IPC_LS
 SG_ TrlrStabAstActIO : 6|1@0+ (1,0) [0|1] ""  CGM_LS,IPC_LS
 SG_ PerfTrcCrnExStngVal : 4|5@0+ (1,0) [0|31] ""  CGM_LS,IPC_LS
 SG_ ActVehAccelV : 5|1@0+ (1,0) [0|1] ""  STC_LS,CGM_LS,FCM_LS,IPC_LS
 SG_ ActVehAccel : 11|12@0- (0.01,0) [-20.48|20.47] "m/s^2"  STC_LS,CGM_LS,FCM_LS,IPC_LS

BO_ 2155012096 SBZA_Right_Status_LS: 1 SBZA_R_LS
 SG_ SODTmpUnavlbleIO : 0|1@0+ (1,0) [0|1] ""  SBZA_L_LS
 SG_ SODSnsClnRqdIO : 1|1@0+ (1,0) [0|1] ""  SBZA_L_LS
 SG_ SODRIC_Ind3 : 2|1@0+ (1,0) [0|1] ""  SBZA_L_LS
 SG_ SODRIC_Ind2 : 3|1@0+ (1,0) [0|1] ""  SBZA_L_LS
 SG_ SODRIC_Ind1 : 4|1@0+ (1,0) [0|1] ""  SBZA_L_LS
 SG_ SODRIC_IndReq : 6|2@0+ (1,0) [0|3] ""  SBZA_L_LS
 SG_ SrvSODSysIO : 7|1@0+ (1,0) [0|1] ""  SBZA_L_LS

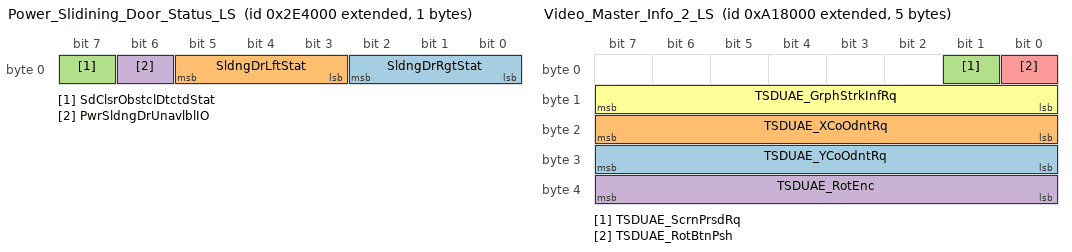
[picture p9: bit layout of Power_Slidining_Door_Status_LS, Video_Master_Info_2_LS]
BO_ 2150514688 Power_Slidining_Door_Status_LS: 1 PSD_L_LS
 SG_ SldngDrRgtStat : 2|3@0+ (1,0) [0|7] ""  CSM_LS,CGM_LS,RadioHead_LS,BCM_LS
 SG_ SldngDrLftStat : 5|3@0+ (1,0) [0|7] ""  CSM_LS,CGM_LS,RadioHead_LS,BCM_LS
 SG_ SdClsrObstclDtctdStat : 7|1@0+ (1,0) [0|1] ""  CSM_LS,CGM_LS,RadioHead_LS,BCM_LS
 SG_ PwrSldngDrUnavlblIO : 6|1@0+ (1,0) [0|1] ""  CSM_LS,CGM_LS,RadioHead_LS,IPC_LS

BO_ 2158067712 Video_Master_Info_2_LS: 5 RadioHead_LS
 SG_ TSDUAE_YCoOdntRq : 31|8@0+ (1,0) [0|255] ""  EDI_LS,DVB_T_LS
 SG_ TSDUAE_XCoOdntRq : 23|8@0+ (1,0) [0|255] ""  EDI_LS,DVB_T_LS
 SG_ TSDUAE_ScrnPrsdRq : 1|1@0+ (1,0) [0|1] ""  EDI_LS,DVB_T_LS
 SG_ TSDUAE_RotEnc : 39|8@0- (1,0) [-128|127] "Detentions"  EDI_LS,DVB_T_LS
 SG_ TSDUAE_RotBtnPsh : 0|1@0+ (1,0) [0|1] ""  EDI_LS,DVB_T_LS
 SG_ TSDUAE_GrphStrkInfRq : 15|8@0+ (1,0) [0|255] ""  EDI_LS,DVB_T_LS

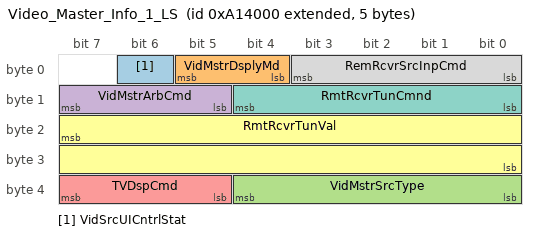
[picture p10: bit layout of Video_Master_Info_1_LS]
BO_ 2158051328 Video_Master_Info_1_LS: 5 RadioHead_LS
 SG_ VidSrcUICntrlStat : 6|1@0+ (1,0) [0|1] ""  EDI_LS
 SG_ VidMstrDsplyMd : 5|2@0+ (1,0) [0|3] ""  EDI_LS
 SG_ VidMstrSrcType : 36|5@0+ (1,0) [0|31] ""  EDI_LS,DVB_T_LS
 SG_ VidMstrArbCmd : 15|3@0+ (1,0) [0|7] ""  DVB_T_LS
 SG_ TVDspCmd : 39|3@0+ (1,0) [0|7] ""  DVB_T_LS
 SG_ RmtRcvrTunVal : 23|16@0- (1,0) [-32768|32767] ""  DVB_T_LS
 SG_ RmtRcvrTunCmnd : 12|5@0+ (1,0) [0|31] ""  DVB_T_LS
 SG_ RemRcvrSrcInpCmd : 3|4@0+ (1,0) [0|15] ""  DVB_T_LS

BO_TX_BU_ 2152054784 : CGM_LS,IPC_LS;
BO_TX_BU_ 2150563840 : CSM_LS,CGM_LS,RadioHead_LS;
BO_TX_BU_ 2152857600 : EOCM2A_K2_LS,EOCM_F_LS,FCM_LS;
BO_TX_BU_ 2158149632 : BSM_LS,VICM_LS;
BO_TX_BU_ 2156281856 : CGM_LS,CSM_LS,RadioHead_LS;
BO_TX_BU_ 2156265472 : CGM_LS,CSM_LS,RadioHead_LS;
BO_TX_BU_ 2150113280 : BSM_LS,VICM_LS;
BO_TX_BU_ 2150055936 : BSM_LS,VICM_LS;
BO_TX_BU_ 2150039552 : BSM_LS,VICM_LS;
BO_TX_BU_ 2151342080 : UPA_LS,APA_LS;
BO_TX_BU_ 2151325696 : UPA_LS,APA_LS;
BO_TX_BU_ 2151809024 : BSM_LS,VICM_LS;
BO_TX_BU_ 2151858176 : BSM_LS,VICM_LS;
BO_TX_BU_ 2150547456 : BSM_LS,VICM_LS;
BO_TX_BU_ 2151489536 : EOCM2A_K2_LS,FCM_LS,EOCM_F_LS;
BO_TX_BU_ 2150514688 : PSD_R_LS,PSD_L_LS;
BO_TX_BU_ 2158067712 : CGM_LS,RadioHead_LS;
BO_TX_BU_ 2158051328 : CGM_LS,RadioHead_LS;
CM_ SG_ 2158051328 RmtRcvrTunVal "To be used with the Remote Receiver Tune Command signal";
BA_DEF_ SG_  "VNSigPrimaryTriggering" ENUM  "No","Yes","DLCLS","DLCHS","DLCCE","DLCFO";
BA_DEF_ SG_  "VNSigRemoteDiagnostics" ENUM  "No","Yes","DLCLS","DLCHS","DLCCE","DLCFO";
BA_DEF_ SG_  "VNSigInfotainment" ENUM  "No","Yes","DLCLS","DLCHS","DLCCE","DLCFO";
BA_DEF_ SG_  "VNSigParkedVehicle" ENUM  "No","Yes","DLCLS","DLCHS","DLCCE","DLCFO";
BA_DEF_ SG_  "VNSigIntermediate" ENUM  "No","Yes","DLCLS","DLCHS","DLCCE","DLCFO";
BA_DEF_ SG_  "VNSigUnused_4" ENUM  "No","Yes","DLCLS","DLCHS","DLCCE","DLCFO";
BA_DEF_ SG_  "SignalType" STRING ;
BA_DEF_ SG_  "PacketOrder" INT 0 65535;
BA_DEF_ SG_  "SignalLongName" STRING ;
BA_DEF_ SG_  "GenSigStartValue" INT 0 65535;
BA_DEF_ SG_  "VNSigDiagnostic" ENUM  "No","Yes","DLCLS","DLCHS","DLCCE","DLCFO";
BA_DEF_ SG_  "VNSigAllNodes" ENUM  "No","Yes","DLCLS","DLCHS","DLCCE","DLCFO";
BA_DEF_ SG_  "GenSigDeltaValue" INT 0 0;
BA_DEF_ SG_  "GenSigInactiveValue" INT 0 0;
BA_DEF_ SG_  "GenSigSendType" ENUM  "not used","not used","not used","not used","not used","not used","not used","NoSigSendType","not used","not used","OnAnyChange","OnChangeIfActive","OnDelta","DLCLS","DLCHS","DLCCE","DLCFO";
BA_DEF_ SG_  "GenSigSendOnInit" ENUM  "Not Initialized","Application","Handler","DLCLS","DLCHS","DLCCE","DLCFO";
BA_DEF_ BO_  "AppGenMsgCycleTime" INT 0 0;
BA_DEF_ BO_  "TpTxIndex" INT 0 99;
BA_DEF_ BO_  "GenMsgILSupport" ENUM  "No","Yes","DLCLS","DLCHS","DLCCE","DLCFO";
BA_DEF_ BO_  "TpApplType" STRING ;
BA_DEF_ BO_  "Prio" INT 0 7;
BA_DEF_ BO_  "MessageSubnet" ENUM  "LS","MS","HS","CE","PE","HV","FO","S1","HE","LE","HE2","DLCLS","DLCHS","DLCCE","DLCFO";
BA_DEF_ BO_  "GenMsgMandatoryToSupervision" ENUM  "No","Yes","DLCLS","DLCHS","DLCCE","DLCFO";
BA_DEF_ BO_  "DiagState" ENUM  "No","Yes","DLCLS","DLCHS","DLCCE","DLCFO";
BA_DEF_ BO_  "GenMsgStartDelayTime" INT 0 100000;
BA_DEF_ BO_  "GenMsgDelayTime" INT 0 100000;
BA_DEF_ BO_  "GenMsgCycleTime" INT 0 100000;
BA_DEF_ BO_  "GenMsgSendType" ENUM  "cyclicX","spontanX","cyclicIfActiveX","spontanWithDelay","cyclicAndSpontanX","cyclicAndSpontanWithDelay","spontanWithRepitition","cyclicIfActiveAndSpontanWD","DLCLS","DLCHS","DLCCE","DLCFO";
BA_DEF_ BO_  "DiagResponse" ENUM  "No","Yes","DLCLS","DLCHS","DLCCE","DLCFO";
BA_DEF_ BO_  "DiagRequest" ENUM  "No","Yes","DLCLS","DLCHS","DLCCE","DLCFO";
BA_DEF_ BO_  "NmMessage" ENUM  "No","Yes","DLCLS","DLCHS","DLCCE","DLCFO";
BA_DEF_REL_ BU_SG_REL_  "GenSigSuprvRespComment" STRING ;
BA_DEF_REL_ BU_SG_REL_  "GenSigVBitResp" ENUM  "No","Yes","DLCLS","DLCHS","DLCCE","DLCFO";
BA_DEF_REL_ BU_SG_REL_  "GenSigVBitRespComment" STRING ;
BA_DEF_REL_ BU_SG_REL_  "GenSigVDAFailComment" STRING ;
BA_DEF_REL_ BU_SG_REL_  "GenSigVDAFailResp" ENUM  "No","Yes","DLCLS","DLCHS","DLCCE","DLCFO";
BA_DEF_REL_ BU_SG_REL_  "GenSigRxStartValue" STRING ;
BA_DEF_REL_ BU_SG_REL_  "GenSigSuprvRespSubValue" INT 0 65535;
BA_DEF_REL_ BU_SG_REL_  "GenSigSuprvResp" ENUM  "None","Notify App","Substitute Default","DLCLS","DLCHS","DLCCE","DLCFO";
BA_DEF_REL_ BU_SG_REL_  "GenSigTimeoutMsg" HEX -2147483648 268435455;
BA_DEF_REL_ BU_SG_REL_  "GenSigTimeoutTime" INT 0 15000;
BA_DEF_DEF_  "VNSigPrimaryTriggering" "No";
BA_DEF_DEF_  "VNSigRemoteDiagnostics" "No";
BA_DEF_DEF_  "VNSigInfotainment" "No";
BA_DEF_DEF_  "VNSigParkedVehicle" "No";
BA_DEF_DEF_  "VNSigIntermediate" "No";
BA_DEF_DEF_  "VNSigUnused_4" "No";
BA_DEF_DEF_  "SignalType" "";
BA_DEF_DEF_  "PacketOrder" 0;
BA_DEF_DEF_  "SignalLongName" "";
BA_DEF_DEF_  "GenSigStartValue" 0;
BA_DEF_DEF_  "VNSigDiagnostic" "No";
BA_DEF_DEF_  "VNSigAllNodes" "No";
BA_DEF_DEF_  "GenSigDeltaValue" 0;
BA_DEF_DEF_  "GenSigInactiveValue" 0;
BA_DEF_DEF_  "GenSigSendType" "NoSigSendType";
BA_DEF_DEF_  "GenSigSendOnInit" "Not Initialized";
BA_DEF_DEF_  "AppGenMsgCycleTime" 0;
BA_DEF_DEF_  "TpTxIndex" 0;
BA_DEF_DEF_  "GenMsgILSupport" "Yes";
BA_DEF_DEF_  "TpApplType" "";
BA_DEF_DEF_  "Prio" 4;
BA_DEF_DEF_  "MessageSubnet" "FO";
BA_DEF_DEF_  "GenMsgMandatoryToSupervision" "No";
BA_DEF_DEF_  "DiagState" "No";
BA_DEF_DEF_  "GenMsgStartDelayTime" 0;
BA_DEF_DEF_  "GenMsgDelayTime" 0;
BA_DEF_DEF_  "GenMsgCycleTime" 0;
BA_DEF_DEF_  "GenMsgSendType" "spontanX";
BA_DEF_DEF_  "DiagResponse" "No";
BA_DEF_DEF_  "DiagRequest" "No";
BA_DEF_DEF_  "NmMessage" "No";
BA_DEF_DEF_REL_ "GenSigSuprvRespComment" "";
BA_DEF_DEF_REL_ "GenSigVBitResp" "No";
BA_DEF_DEF_REL_ "GenSigVBitRespComment" "";
BA_DEF_DEF_REL_ "GenSigVDAFailComment" "";
BA_DEF_DEF_REL_ "GenSigVDAFailResp" "No";
BA_DEF_DEF_REL_ "GenSigRxStartValue" "";
BA_DEF_DEF_REL_ "GenSigSuprvRespSubValue" 0;
BA_DEF_DEF_REL_ "GenSigSuprvResp" "None";
BA_DEF_DEF_REL_ "GenSigTimeoutMsg" 0;
BA_DEF_DEF_REL_ "GenSigTimeoutTime" 0;
BA_ "MessageSubnet" BO_ 2156298240 0;
BA_ "GenMsgDelayTime" BO_ 2156298240 100;
BA_ "MessageSubnet" BO_ 2149924864 0;
BA_ "GenMsgDelayTime" BO_ 2149924864 100;
BA_ "MessageSubnet" BO_ 2152054784 0;
BA_ "GenMsgDelayTime" BO_ 2152054784 100;
BA_ "MessageSubnet" BO_ 2150301696 0;
BA_ "GenMsgDelayTime" BO_ 2150301696 100;
BA_ "MessageSubnet" BO_ 2150563840 0;
BA_ "GenMsgDelayTime" BO_ 2150563840 100;
BA_ "MessageSubnet" BO_ 2154758144 0;
BA_ "GenMsgDelayTime" BO_ 2154758144 100;
BA_ "MessageSubnet" BO_ 2154577920 0;
BA_ "GenMsgDelayTime" BO_ 2154577920 10;
BA_ "MessageSubnet" BO_ 2154594304 0;
BA_ "GenMsgDelayTime" BO_ 2154594304 10;
BA_ "MessageSubnet" BO_ 2154586112 0;
BA_ "GenMsgDelayTime" BO_ 2154586112 10;
BA_ "MessageSubnet" BO_ 2152857600 0;
BA_ "GenMsgDelayTime" BO_ 2152857600 100;
BA_ "MessageSubnet" BO_ 2158149632 0;
BA_ "GenMsgDelayTime" BO_ 2158149632 100;
BA_ "MessageSubnet" BO_ 2158116864 0;
BA_ "GenMsgDelayTime" BO_ 2158116864 100;
BA_ "MessageSubnet" BO_ 2156281856 0;
BA_ "GenMsgDelayTime" BO_ 2156281856 100;
BA_ "MessageSubnet" BO_ 2156265472 0;
BA_ "GenMsgDelayTime" BO_ 2156265472 100;
BA_ "MessageSubnet" BO_ 2150113280 0;
BA_ "GenMsgDelayTime" BO_ 2150113280 100;
BA_ "MessageSubnet" BO_ 2150055936 0;
BA_ "GenMsgDelayTime" BO_ 2150055936 100;
BA_ "MessageSubnet" BO_ 2150039552 0;
BA_ "GenMsgDelayTime" BO_ 2150039552 100;
BA_ "MessageSubnet" BO_ 2154856448 0;
BA_ "GenMsgDelayTime" BO_ 2154856448 100;
BA_ "MessageSubnet" BO_ 2151342080 0;
BA_ "GenMsgDelayTime" BO_ 2151342080 100;
BA_ "MessageSubnet" BO_ 2151325696 0;
BA_ "GenMsgDelayTime" BO_ 2151325696 100;
BA_ "MessageSubnet" BO_ 2151809024 0;
BA_ "GenMsgDelayTime" BO_ 2151809024 100;
BA_ "MessageSubnet" BO_ 2151858176 0;
BA_ "GenMsgDelayTime" BO_ 2151858176 100;
BA_ "MessageSubnet" BO_ 2150547456 0;
BA_ "GenMsgDelayTime" BO_ 2150547456 100;
BA_ "MessageSubnet" BO_ 2151489536 0;
BA_ "GenMsgDelayTime" BO_ 2151489536 100;
BA_ "MessageSubnet" BO_ 2149761024 0;
BA_ "GenMsgStartDelayTime" BO_ 2149761024 110;
BA_ "GenMsgCycleTime" BO_ 2149761024 250;
BA_ "GenMsgSendType" BO_ 2149761024 0;
BA_ "MessageSubnet" BO_ 2155012096 0;
BA_ "GenMsgDelayTime" BO_ 2155012096 100;
BA_ "MessageSubnet" BO_ 2150514688 0;
BA_ "GenMsgDelayTime" BO_ 2150514688 100;
BA_ "MessageSubnet" BO_ 2158067712 0;
BA_ "GenMsgDelayTime" BO_ 2158067712 100;
BA_ "MessageSubnet" BO_ 2158051328 0;
BA_ "GenMsgDelayTime" BO_ 2158051328 100;
BA_ "GenSigSendType" SG_ 2156298240 HTRActvIndOn 10;
BA_ "GenSigSendOnInit" SG_ 2156298240 HTRActvIndOn 1;
BA_ "VNSigInfotainment" SG_ 2156298240 HTRActvIndOn 1;
BA_ "SignalType" SG_ 2156298240 HTRActvIndOn "BLN";
BA_ "SignalLongName" SG_ 2156298240 HTRActvIndOn "Hill Top Reserve Active Indication On";
BA_ "VNSigAllNodes" SG_ 2156298240 HTRActvIndOn 1;
BA_ "GenSigDeltaValue" SG_ 2156298240 HVBSTLPC_MntOfHr 1;
BA_ "GenSigSendType" SG_ 2156298240 HVBSTLPC_MntOfHr 12;
BA_ "GenSigSendOnInit" SG_ 2156298240 HVBSTLPC_MntOfHr 1;
BA_ "VNSigInfotainment" SG_ 2156298240 HVBSTLPC_MntOfHr 1;
BA_ "SignalType" SG_ 2156298240 HVBSTLPC_MntOfHr "UNM";
BA_ "PacketOrder" SG_ 2156298240 HVBSTLPC_MntOfHr 3;
BA_ "SignalLongName" SG_ 2156298240 HVBSTLPC_MntOfHr "High Voltage Battery Start Time Low Power Charge : Minute of Hour";
BA_ "VNSigAllNodes" SG_ 2156298240 HVBSTLPC_MntOfHr 1;
BA_ "GenSigDeltaValue" SG_ 2156298240 HVBSTLPC_HrOfDy 1;
BA_ "GenSigSendType" SG_ 2156298240 HVBSTLPC_HrOfDy 12;
BA_ "GenSigSendOnInit" SG_ 2156298240 HVBSTLPC_HrOfDy 1;
BA_ "VNSigInfotainment" SG_ 2156298240 HVBSTLPC_HrOfDy 1;
BA_ "SignalType" SG_ 2156298240 HVBSTLPC_HrOfDy "UNM";
BA_ "PacketOrder" SG_ 2156298240 HVBSTLPC_HrOfDy 2;
BA_ "SignalLongName" SG_ 2156298240 HVBSTLPC_HrOfDy "High Voltage Battery Start Time Low Power Charge : Hour of Day";
BA_ "VNSigAllNodes" SG_ 2156298240 HVBSTLPC_HrOfDy 1;
BA_ "GenSigSendType" SG_ 2156298240 HVBSTLPC_DyOfWk 10;
BA_ "GenSigSendOnInit" SG_ 2156298240 HVBSTLPC_DyOfWk 1;
BA_ "VNSigInfotainment" SG_ 2156298240 HVBSTLPC_DyOfWk 1;
BA_ "SignalType" SG_ 2156298240 HVBSTLPC_DyOfWk "ENM";
BA_ "PacketOrder" SG_ 2156298240 HVBSTLPC_DyOfWk 1;
BA_ "SignalLongName" SG_ 2156298240 HVBSTLPC_DyOfWk "High Voltage Battery Start Time Low Power Charge : Day of Week";
BA_ "VNSigAllNodes" SG_ 2156298240 HVBSTLPC_DyOfWk 1;
BA_ "GenSigDeltaValue" SG_ 2156298240 HVBSTHPC_MntOfHr 1;
BA_ "GenSigSendType" SG_ 2156298240 HVBSTHPC_MntOfHr 12;
BA_ "GenSigSendOnInit" SG_ 2156298240 HVBSTHPC_MntOfHr 1;
BA_ "VNSigInfotainment" SG_ 2156298240 HVBSTHPC_MntOfHr 1;
BA_ "SignalType" SG_ 2156298240 HVBSTHPC_MntOfHr "UNM";
BA_ "PacketOrder" SG_ 2156298240 HVBSTHPC_MntOfHr 3;
BA_ "SignalLongName" SG_ 2156298240 HVBSTHPC_MntOfHr "High Voltage Battery Start Time High Power Charge : Minute of Hour";
BA_ "VNSigAllNodes" SG_ 2156298240 HVBSTHPC_MntOfHr 1;
BA_ "GenSigDeltaValue" SG_ 2156298240 HVBSTHPC_HrOfDy 1;
BA_ "GenSigSendType" SG_ 2156298240 HVBSTHPC_HrOfDy 12;
BA_ "GenSigSendOnInit" SG_ 2156298240 HVBSTHPC_HrOfDy 1;
BA_ "VNSigInfotainment" SG_ 2156298240 HVBSTHPC_HrOfDy 1;
BA_ "SignalType" SG_ 2156298240 HVBSTHPC_HrOfDy "UNM";
BA_ "PacketOrder" SG_ 2156298240 HVBSTHPC_HrOfDy 2;
BA_ "SignalLongName" SG_ 2156298240 HVBSTHPC_HrOfDy "High Voltage Battery Start Time High Power Charge : Hour of Day";
BA_ "VNSigAllNodes" SG_ 2156298240 HVBSTHPC_HrOfDy 1;
BA_ "GenSigSendType" SG_ 2156298240 HVBSTHPC_DyOfWk 10;
BA_ "GenSigSendOnInit" SG_ 2156298240 HVBSTHPC_DyOfWk 1;
BA_ "VNSigInfotainment" SG_ 2156298240 HVBSTHPC_DyOfWk 1;
BA_ "SignalType" SG_ 2156298240 HVBSTHPC_DyOfWk "ENM";
BA_ "PacketOrder" SG_ 2156298240 HVBSTHPC_DyOfWk 1;
BA_ "SignalLongName" SG_ 2156298240 HVBSTHPC_DyOfWk "High Voltage Battery Start Time High Power Charge : Day of Week";
BA_ "VNSigAllNodes" SG_ 2156298240 HVBSTHPC_DyOfWk 1;
BA_ "GenSigDeltaValue" SG_ 2156298240 HVBCTLPC_MntOfHr 1;
BA_ "GenSigSendType" SG_ 2156298240 HVBCTLPC_MntOfHr 12;
BA_ "GenSigSendOnInit" SG_ 2156298240 HVBCTLPC_MntOfHr 1;
BA_ "VNSigInfotainment" SG_ 2156298240 HVBCTLPC_MntOfHr 1;
BA_ "SignalType" SG_ 2156298240 HVBCTLPC_MntOfHr "UNM";
BA_ "PacketOrder" SG_ 2156298240 HVBCTLPC_MntOfHr 3;
BA_ "SignalLongName" SG_ 2156298240 HVBCTLPC_MntOfHr "High Voltage Battery Complete Time Low Power Charge : Minute of Hour";
BA_ "VNSigAllNodes" SG_ 2156298240 HVBCTLPC_MntOfHr 1;
BA_ "GenSigDeltaValue" SG_ 2156298240 HVBCTLPC_HrOfDy 1;
BA_ "GenSigSendType" SG_ 2156298240 HVBCTLPC_HrOfDy 12;
BA_ "GenSigSendOnInit" SG_ 2156298240 HVBCTLPC_HrOfDy 1;
BA_ "VNSigInfotainment" SG_ 2156298240 HVBCTLPC_HrOfDy 1;
BA_ "SignalType" SG_ 2156298240 HVBCTLPC_HrOfDy "UNM";
BA_ "PacketOrder" SG_ 2156298240 HVBCTLPC_HrOfDy 2;
BA_ "SignalLongName" SG_ 2156298240 HVBCTLPC_HrOfDy "High Voltage Battery Complete Time Low Power Charge : Hour of Day";
BA_ "VNSigAllNodes" SG_ 2156298240 HVBCTLPC_HrOfDy 1;
BA_ "GenSigSendType" SG_ 2156298240 HVBCTLPC_DyOfWk 10;
BA_ "GenSigSendOnInit" SG_ 2156298240 HVBCTLPC_DyOfWk 1;
BA_ "VNSigInfotainment" SG_ 2156298240 HVBCTLPC_DyOfWk 1;
BA_ "SignalType" SG_ 2156298240 HVBCTLPC_DyOfWk "ENM";
BA_ "PacketOrder" SG_ 2156298240 HVBCTLPC_DyOfWk 1;
BA_ "SignalLongName" SG_ 2156298240 HVBCTLPC_DyOfWk "High Voltage Battery Complete Time Low Power Charge : Day of Week";
BA_ "VNSigAllNodes" SG_ 2156298240 HVBCTLPC_DyOfWk 1;
BA_ "GenSigDeltaValue" SG_ 2156298240 HVBCTHPC_MntOfHr 1;
BA_ "GenSigSendType" SG_ 2156298240 HVBCTHPC_MntOfHr 12;
BA_ "GenSigSendOnInit" SG_ 2156298240 HVBCTHPC_MntOfHr 1;
BA_ "VNSigInfotainment" SG_ 2156298240 HVBCTHPC_MntOfHr 1;
BA_ "SignalType" SG_ 2156298240 HVBCTHPC_MntOfHr "UNM";
BA_ "PacketOrder" SG_ 2156298240 HVBCTHPC_MntOfHr 3;
BA_ "SignalLongName" SG_ 2156298240 HVBCTHPC_MntOfHr "High Voltage Battery Complete Time High Power Charge : Minute of Hour";
BA_ "VNSigAllNodes" SG_ 2156298240 HVBCTHPC_MntOfHr 1;
BA_ "GenSigDeltaValue" SG_ 2156298240 HVBCTHPC_HrOfDy 1;
BA_ "GenSigSendType" SG_ 2156298240 HVBCTHPC_HrOfDy 12;
BA_ "GenSigSendOnInit" SG_ 2156298240 HVBCTHPC_HrOfDy 1;
BA_ "VNSigInfotainment" SG_ 2156298240 HVBCTHPC_HrOfDy 1;
BA_ "SignalType" SG_ 2156298240 HVBCTHPC_HrOfDy "UNM";
BA_ "PacketOrder" SG_ 2156298240 HVBCTHPC_HrOfDy 2;
BA_ "SignalLongName" SG_ 2156298240 HVBCTHPC_HrOfDy "High Voltage Battery Complete Time High Power Charge : Hour of Day";
BA_ "VNSigAllNodes" SG_ 2156298240 HVBCTHPC_HrOfDy 1;
BA_ "GenSigSendType" SG_ 2156298240 HVBCTHPC_DyOfWk 10;
BA_ "GenSigSendOnInit" SG_ 2156298240 HVBCTHPC_DyOfWk 1;
BA_ "VNSigInfotainment" SG_ 2156298240 HVBCTHPC_DyOfWk 1;
BA_ "SignalType" SG_ 2156298240 HVBCTHPC_DyOfWk "ENM";
BA_ "PacketOrder" SG_ 2156298240 HVBCTHPC_DyOfWk 1;
BA_ "SignalLongName" SG_ 2156298240 HVBCTHPC_DyOfWk "High Voltage Battery Complete Time High Power Charge : Day of Week";
BA_ "VNSigAllNodes" SG_ 2156298240 HVBCTHPC_DyOfWk 1;
BA_ "GenSigSendType" SG_ 2156298240 InvldHMIEtrIO 10;
BA_ "VNSigInfotainment" SG_ 2156298240 InvldHMIEtrIO 1;
BA_ "SignalType" SG_ 2156298240 InvldHMIEtrIO "BLN";
BA_ "SignalLongName" SG_ 2156298240 InvldHMIEtrIO "Invalid HMI Entry Indication On";
BA_ "VNSigAllNodes" SG_ 2156298240 InvldHMIEtrIO 1;
BA_ "GenSigSendType" SG_ 2156298240 InsfcntTmTFlChrgIO 10;
BA_ "VNSigInfotainment" SG_ 2156298240 InsfcntTmTFlChrgIO 1;
BA_ "SignalType" SG_ 2156298240 InsfcntTmTFlChrgIO "BLN";
BA_ "SignalLongName" SG_ 2156298240 InsfcntTmTFlChrgIO "Insufficient Time to Fully Charge Indication On";
BA_ "VNSigAllNodes" SG_ 2156298240 InsfcntTmTFlChrgIO 1;
BA_ "GenSigSendType" SG_ 2156298240 HVBatChrgCrdAlrtReq 10;
BA_ "VNSigInfotainment" SG_ 2156298240 HVBatChrgCrdAlrtReq 1;
BA_ "SignalType" SG_ 2156298240 HVBatChrgCrdAlrtReq "ENM";
BA_ "SignalLongName" SG_ 2156298240 HVBatChrgCrdAlrtReq "High Voltage Battery Charge Cord Alert Request";
BA_ "VNSigAllNodes" SG_ 2156298240 HVBatChrgCrdAlrtReq 1;
BA_ "GenSigSendType" SG_ 2156298240 HVCSDTES_NPDTIO 10;
BA_ "GenSigSendOnInit" SG_ 2156298240 HVCSDTES_NPDTIO 1;
BA_ "VNSigInfotainment" SG_ 2156298240 HVCSDTES_NPDTIO 1;
BA_ "SignalType" SG_ 2156298240 HVCSDTES_NPDTIO "BLN";
BA_ "PacketOrder" SG_ 2156298240 HVCSDTES_NPDTIO 3;
BA_ "SignalLongName" SG_ 2156298240 HVCSDTES_NPDTIO "High Voltage Charging System Departure Time Exceeded Status : Next Planned Departure Time Indication On";
BA_ "VNSigAllNodes" SG_ 2156298240 HVCSDTES_NPDTIO 1;
BA_ "GenSigSendType" SG_ 2156298240 HVCSDTES_LoPwrCIO 10;
BA_ "GenSigSendOnInit" SG_ 2156298240 HVCSDTES_LoPwrCIO 1;
BA_ "VNSigInfotainment" SG_ 2156298240 HVCSDTES_LoPwrCIO 1;
BA_ "SignalType" SG_ 2156298240 HVCSDTES_LoPwrCIO "BLN";
BA_ "PacketOrder" SG_ 2156298240 HVCSDTES_LoPwrCIO 1;
BA_ "SignalLongName" SG_ 2156298240 HVCSDTES_LoPwrCIO "High Voltage Charging System Departure Time Exceeded Status : Low Power Charge Complete Time Indication On";
BA_ "VNSigAllNodes" SG_ 2156298240 HVCSDTES_LoPwrCIO 1;
BA_ "GenSigSendType" SG_ 2156298240 HVCSDTES_HiPwrCIO 10;
BA_ "GenSigSendOnInit" SG_ 2156298240 HVCSDTES_HiPwrCIO 1;
BA_ "VNSigInfotainment" SG_ 2156298240 HVCSDTES_HiPwrCIO 1;
BA_ "SignalType" SG_ 2156298240 HVCSDTES_HiPwrCIO "BLN";
BA_ "PacketOrder" SG_ 2156298240 HVCSDTES_HiPwrCIO 2;
BA_ "SignalLongName" SG_ 2156298240 HVCSDTES_HiPwrCIO "High Voltage Charging System Departure Time Exceeded Status : High Power Charge Complete Time Indication On";
BA_ "VNSigAllNodes" SG_ 2156298240 HVCSDTES_HiPwrCIO 1;
BA_ "GenSigSendType" SG_ 2149924864 PTOMobModTrnsInGrIO 10;
BA_ "SignalType" SG_ 2149924864 PTOMobModTrnsInGrIO "BLN";
BA_ "SignalLongName" SG_ 2149924864 PTOMobModTrnsInGrIO "Power Take Off Mobile Mode Transmission In Gear Indication On";
BA_ "VNSigAllNodes" SG_ 2149924864 PTOMobModTrnsInGrIO 1;
BA_ "GenSigSendType" SG_ 2149924864 a_12VBatSysUnstab 10;
BA_ "SignalType" SG_ 2149924864 a_12VBatSysUnstab "BLN";
BA_ "SignalLongName" SG_ 2149924864 a_12VBatSysUnstab "12 Volt Battery System Unstable";
BA_ "VNSigAllNodes" SG_ 2149924864 a_12VBatSysUnstab 1;
BA_ "GenSigSendType" SG_ 2149924864 FwdClnMtgnBrkReqAct 10;
BA_ "SignalType" SG_ 2149924864 FwdClnMtgnBrkReqAct "BLN";
BA_ "SignalLongName" SG_ 2149924864 FwdClnMtgnBrkReqAct "Forward Collision Mitigation Braking Request Active";
BA_ "VNSigAllNodes" SG_ 2149924864 FwdClnMtgnBrkReqAct 1;
BA_ "GenSigSendType" SG_ 2149924864 TireRRLowTracIO 10;
BA_ "SignalType" SG_ 2149924864 TireRRLowTracIO "BLN";
BA_ "SignalLongName" SG_ 2149924864 TireRRLowTracIO "Tire Right Rear Low Traction Indication On";
BA_ "VNSigAllNodes" SG_ 2149924864 TireRRLowTracIO 1;
BA_ "GenSigSendType" SG_ 2149924864 TireRFLowTracIO 10;
BA_ "SignalType" SG_ 2149924864 TireRFLowTracIO "BLN";
BA_ "SignalLongName" SG_ 2149924864 TireRFLowTracIO "Tire Right Front Low Traction Indication On";
BA_ "VNSigAllNodes" SG_ 2149924864 TireRFLowTracIO 1;
BA_ "GenSigSendType" SG_ 2149924864 TireLRLowTracIO 10;
BA_ "SignalType" SG_ 2149924864 TireLRLowTracIO "BLN";
BA_ "SignalLongName" SG_ 2149924864 TireLRLowTracIO "Tire Left Rear Low Traction Indication On";
BA_ "VNSigAllNodes" SG_ 2149924864 TireLRLowTracIO 1;
BA_ "GenSigSendType" SG_ 2149924864 TireLFLowTracIO 10;
BA_ "SignalType" SG_ 2149924864 TireLFLowTracIO "BLN";
BA_ "SignalLongName" SG_ 2149924864 TireLFLowTracIO "Tire Left Front Low Traction Indication On";
BA_ "VNSigAllNodes" SG_ 2149924864 TireLFLowTracIO 1;
BA_ "GenSigSendType" SG_ 2149924864 HilRlbkCtrlActIO 10;
BA_ "SignalType" SG_ 2149924864 HilRlbkCtrlActIO "BLN";
BA_ "SignalLongName" SG_ 2149924864 HilRlbkCtrlActIO "Hill Rollback Control Active Indiction On";
BA_ "VNSigAllNodes" SG_ 2149924864 HilRlbkCtrlActIO 1;
BA_ "GenSigSendType" SG_ 2149924864 FstIdlMdAct 10;
BA_ "SignalType" SG_ 2149924864 FstIdlMdAct "BLN";
BA_ "SignalLongName" SG_ 2149924864 FstIdlMdAct "Fast Idle Mode Active";
BA_ "VNSigAllNodes" SG_ 2149924864 FstIdlMdAct 1;
BA_ "GenSigSendType" SG_ 2149924864 DsplyPerfMdRq 10;
BA_ "SignalType" SG_ 2149924864 DsplyPerfMdRq "ENM";
BA_ "SignalLongName" SG_ 2149924864 DsplyPerfMdRq "Display Performance Mode Request";
BA_ "VNSigAllNodes" SG_ 2149924864 DsplyPerfMdRq 1;
BA_ "GenSigSendType" SG_ 2149924864 DrvSelMd8Stat 10;
BA_ "SignalType" SG_ 2149924864 DrvSelMd8Stat "ENM";
BA_ "SignalLongName" SG_ 2149924864 DrvSelMd8Stat "Driver Selected Mode 8 Status";
BA_ "VNSigAllNodes" SG_ 2149924864 DrvSelMd8Stat 1;
BA_ "GenSigSendType" SG_ 2149924864 DrvSelMd8ReqDnd 10;
BA_ "SignalType" SG_ 2149924864 DrvSelMd8ReqDnd "BLN";
BA_ "SignalLongName" SG_ 2149924864 DrvSelMd8ReqDnd "Driver Selected Mode 8 Request Denied";
BA_ "VNSigAllNodes" SG_ 2149924864 DrvSelMd8ReqDnd 1;
BA_ "GenSigSendType" SG_ 2149924864 DrvSelMd7Stat 10;
BA_ "SignalType" SG_ 2149924864 DrvSelMd7Stat "ENM";
BA_ "SignalLongName" SG_ 2149924864 DrvSelMd7Stat "Driver Selected Mode 7 Status";
BA_ "VNSigAllNodes" SG_ 2149924864 DrvSelMd7Stat 1;
BA_ "GenSigSendType" SG_ 2149924864 DrvSelMd7ReqDnd 10;
BA_ "SignalType" SG_ 2149924864 DrvSelMd7ReqDnd "BLN";
BA_ "SignalLongName" SG_ 2149924864 DrvSelMd7ReqDnd "Driver Selected Mode 7 Request Denied";
BA_ "VNSigAllNodes" SG_ 2149924864 DrvSelMd7ReqDnd 1;
BA_ "GenSigSendType" SG_ 2149924864 DrvSelMd6Stat 10;
BA_ "SignalType" SG_ 2149924864 DrvSelMd6Stat "ENM";
BA_ "SignalLongName" SG_ 2149924864 DrvSelMd6Stat "Driver Selected Mode 6 Status";
BA_ "VNSigAllNodes" SG_ 2149924864 DrvSelMd6Stat 1;
BA_ "GenSigSendType" SG_ 2149924864 DrvSelMd6ReqDnd 10;
BA_ "SignalType" SG_ 2149924864 DrvSelMd6ReqDnd "BLN";
BA_ "SignalLongName" SG_ 2149924864 DrvSelMd6ReqDnd "Driver Selected Mode 6 Request Denied";
BA_ "VNSigAllNodes" SG_ 2149924864 DrvSelMd6ReqDnd 1;
BA_ "GenSigSendType" SG_ 2149924864 DrvSelMd5Stat 10;
BA_ "SignalType" SG_ 2149924864 DrvSelMd5Stat "ENM";
BA_ "SignalLongName" SG_ 2149924864 DrvSelMd5Stat "Driver Selected Mode 5 Status";
BA_ "VNSigAllNodes" SG_ 2149924864 DrvSelMd5Stat 1;
BA_ "GenSigSendType" SG_ 2149924864 DrvSelMd5ReqDnd 10;
BA_ "SignalType" SG_ 2149924864 DrvSelMd5ReqDnd "BLN";
BA_ "SignalLongName" SG_ 2149924864 DrvSelMd5ReqDnd "Driver Selected Mode 5 Request Denied";
BA_ "VNSigAllNodes" SG_ 2149924864 DrvSelMd5ReqDnd 1;
BA_ "GenSigSendType" SG_ 2149924864 DrvSelMd4Stat 10;
BA_ "SignalType" SG_ 2149924864 DrvSelMd4Stat "ENM";
BA_ "SignalLongName" SG_ 2149924864 DrvSelMd4Stat "Driver Selected Mode 4 Status";
BA_ "VNSigAllNodes" SG_ 2149924864 DrvSelMd4Stat 1;
BA_ "GenSigSendType" SG_ 2149924864 DrvSelMd4ReqDnd 10;
BA_ "SignalType" SG_ 2149924864 DrvSelMd4ReqDnd "BLN";
BA_ "SignalLongName" SG_ 2149924864 DrvSelMd4ReqDnd "Driver Selected Mode 4 Request Denied";
BA_ "VNSigAllNodes" SG_ 2149924864 DrvSelMd4ReqDnd 1;
BA_ "GenSigSendType" SG_ 2149924864 EDADS_RcmndtFwdGr 10;
BA_ "SignalType" SG_ 2149924864 EDADS_RcmndtFwdGr "ENM";
BA_ "PacketOrder" SG_ 2149924864 EDADS_RcmndtFwdGr 4;
BA_ "SignalLongName" SG_ 2149924864 EDADS_RcmndtFwdGr "ECO Drive Assist Display Status : Recommended Forward Gear";
BA_ "VNSigAllNodes" SG_ 2149924864 EDADS_RcmndtFwdGr 1;
BA_ "GenSigSendType" SG_ 2149924864 EDADS_CrntFwdMsdG 10;
BA_ "SignalType" SG_ 2149924864 EDADS_CrntFwdMsdG "ENM";
BA_ "PacketOrder" SG_ 2149924864 EDADS_CrntFwdMsdG 3;
BA_ "SignalLongName" SG_ 2149924864 EDADS_CrntFwdMsdG "ECO Drive Assist Display Status : Current Forward Measured Gear";
BA_ "VNSigAllNodes" SG_ 2149924864 EDADS_CrntFwdMsdG 1;
BA_ "GenSigSendType" SG_ 2149924864 EDADS_ShftIndStat 10;
BA_ "SignalType" SG_ 2149924864 EDADS_ShftIndStat "ENM";
BA_ "PacketOrder" SG_ 2149924864 EDADS_ShftIndStat 2;
BA_ "SignalLongName" SG_ 2149924864 EDADS_ShftIndStat "ECO Drive Assist Display Status : Shift Indication Status";
BA_ "VNSigAllNodes" SG_ 2149924864 EDADS_ShftIndStat 1;
BA_ "GenSigSendType" SG_ 2149924864 EDADS_EcoDrvShftIO 10;
BA_ "SignalType" SG_ 2149924864 EDADS_EcoDrvShftIO "BLN";
BA_ "PacketOrder" SG_ 2149924864 EDADS_EcoDrvShftIO 1;
BA_ "SignalLongName" SG_ 2149924864 EDADS_EcoDrvShftIO "ECO Drive Assist Display Status : ECO Drive Assist Shift Indication On";
BA_ "VNSigAllNodes" SG_ 2149924864 EDADS_EcoDrvShftIO 1;
BA_ "GenSigSendType" SG_ 2149924864 DSMSS_DrvSelMd0Pn 10;
BA_ "GenSigSendOnInit" SG_ 2149924864 DSMSS_DrvSelMd0Pn 1;
BA_ "SignalType" SG_ 2149924864 DSMSS_DrvSelMd0Pn "BLN";
BA_ "PacketOrder" SG_ 2149924864 DSMSS_DrvSelMd0Pn 17;
BA_ "SignalLongName" SG_ 2149924864 DSMSS_DrvSelMd0Pn "Driver Selected Mode Selection Status : Driver Selected Mode 0 Pending";
BA_ "VNSigAllNodes" SG_ 2149924864 DSMSS_DrvSelMd0Pn 1;
BA_ "GenSigSendType" SG_ 2149924864 DSMSS_DrvSelMd8Pn 10;
BA_ "GenSigSendOnInit" SG_ 2149924864 DSMSS_DrvSelMd8Pn 1;
BA_ "SignalType" SG_ 2149924864 DSMSS_DrvSelMd8Pn "BLN";
BA_ "PacketOrder" SG_ 2149924864 DSMSS_DrvSelMd8Pn 16;
BA_ "SignalLongName" SG_ 2149924864 DSMSS_DrvSelMd8Pn "Driver Selected Mode Selection Status : Driver Selected Mode 8 Pending";
BA_ "VNSigAllNodes" SG_ 2149924864 DSMSS_DrvSelMd8Pn 1;
BA_ "GenSigSendType" SG_ 2149924864 DSMSS_DrvSelMd7Pn 10;
BA_ "GenSigSendOnInit" SG_ 2149924864 DSMSS_DrvSelMd7Pn 1;
BA_ "SignalType" SG_ 2149924864 DSMSS_DrvSelMd7Pn "BLN";
BA_ "PacketOrder" SG_ 2149924864 DSMSS_DrvSelMd7Pn 15;
BA_ "SignalLongName" SG_ 2149924864 DSMSS_DrvSelMd7Pn "Driver Selected Mode Selection Status : Driver Selected Mode 7 Pending";
BA_ "VNSigAllNodes" SG_ 2149924864 DSMSS_DrvSelMd7Pn 1;
BA_ "GenSigSendType" SG_ 2149924864 DSMSS_DrvSelMd6Pn 10;
BA_ "GenSigSendOnInit" SG_ 2149924864 DSMSS_DrvSelMd6Pn 1;
BA_ "SignalType" SG_ 2149924864 DSMSS_DrvSelMd6Pn "BLN";
BA_ "PacketOrder" SG_ 2149924864 DSMSS_DrvSelMd6Pn 14;
BA_ "SignalLongName" SG_ 2149924864 DSMSS_DrvSelMd6Pn "Driver Selected Mode Selection Status : Driver Selected Mode 6 Pending";
BA_ "VNSigAllNodes" SG_ 2149924864 DSMSS_DrvSelMd6Pn 1;
BA_ "GenSigSendType" SG_ 2149924864 DSMSS_DrvSelMd5Pn 10;
BA_ "GenSigSendOnInit" SG_ 2149924864 DSMSS_DrvSelMd5Pn 1;
BA_ "SignalType" SG_ 2149924864 DSMSS_DrvSelMd5Pn "BLN";
BA_ "PacketOrder" SG_ 2149924864 DSMSS_DrvSelMd5Pn 13;
BA_ "SignalLongName" SG_ 2149924864 DSMSS_DrvSelMd5Pn "Driver Selected Mode Selection Status : Driver Selected Mode 5 Pending";
BA_ "VNSigAllNodes" SG_ 2149924864 DSMSS_DrvSelMd5Pn 1;
BA_ "GenSigSendType" SG_ 2149924864 DSMSS_DrvSelMd4Pn 10;
BA_ "GenSigSendOnInit" SG_ 2149924864 DSMSS_DrvSelMd4Pn 1;
BA_ "SignalType" SG_ 2149924864 DSMSS_DrvSelMd4Pn "BLN";
BA_ "PacketOrder" SG_ 2149924864 DSMSS_DrvSelMd4Pn 12;
BA_ "SignalLongName" SG_ 2149924864 DSMSS_DrvSelMd4Pn "Driver Selected Mode Selection Status : Driver Selected Mode 4 Pending";
BA_ "VNSigAllNodes" SG_ 2149924864 DSMSS_DrvSelMd4Pn 1;
BA_ "GenSigSendType" SG_ 2149924864 DSMSS_DrvSelMd3Pn 10;
BA_ "GenSigSendOnInit" SG_ 2149924864 DSMSS_DrvSelMd3Pn 1;
BA_ "SignalType" SG_ 2149924864 DSMSS_DrvSelMd3Pn "BLN";
BA_ "PacketOrder" SG_ 2149924864 DSMSS_DrvSelMd3Pn 11;
BA_ "SignalLongName" SG_ 2149924864 DSMSS_DrvSelMd3Pn "Driver Selected Mode Selection Status : Driver Selected Mode 3 Pending";
BA_ "VNSigAllNodes" SG_ 2149924864 DSMSS_DrvSelMd3Pn 1;
BA_ "GenSigSendType" SG_ 2149924864 DSMSS_DrvSelMd2Pn 10;
BA_ "GenSigSendOnInit" SG_ 2149924864 DSMSS_DrvSelMd2Pn 1;
BA_ "SignalType" SG_ 2149924864 DSMSS_DrvSelMd2Pn "BLN";
BA_ "PacketOrder" SG_ 2149924864 DSMSS_DrvSelMd2Pn 10;
BA_ "SignalLongName" SG_ 2149924864 DSMSS_DrvSelMd2Pn "Driver Selected Mode Selection Status : Driver Selected Mode 2 Pending";
BA_ "VNSigAllNodes" SG_ 2149924864 DSMSS_DrvSelMd2Pn 1;
BA_ "GenSigSendType" SG_ 2149924864 DSMSS_DrvSelMd1Pn 10;
BA_ "GenSigSendOnInit" SG_ 2149924864 DSMSS_DrvSelMd1Pn 1;
BA_ "SignalType" SG_ 2149924864 DSMSS_DrvSelMd1Pn "BLN";
BA_ "PacketOrder" SG_ 2149924864 DSMSS_DrvSelMd1Pn 9;
BA_ "SignalLongName" SG_ 2149924864 DSMSS_DrvSelMd1Pn "Driver Selected Mode Selection Status : Driver Selected Mode 1 Pending";
BA_ "VNSigAllNodes" SG_ 2149924864 DSMSS_DrvSelMd1Pn 1;
BA_ "GenSigSendType" SG_ 2149924864 DSMSS_DrvSelMd8Un 10;
BA_ "GenSigSendOnInit" SG_ 2149924864 DSMSS_DrvSelMd8Un 1;
BA_ "SignalType" SG_ 2149924864 DSMSS_DrvSelMd8Un "BLN";
BA_ "PacketOrder" SG_ 2149924864 DSMSS_DrvSelMd8Un 8;
BA_ "SignalLongName" SG_ 2149924864 DSMSS_DrvSelMd8Un "Driver Selected Mode Selection Status : Driver Selected Mode 8 Unavailable";
BA_ "VNSigAllNodes" SG_ 2149924864 DSMSS_DrvSelMd8Un 1;
BA_ "GenSigSendType" SG_ 2149924864 DSMSS_DrvSelMd7Un 10;
BA_ "GenSigSendOnInit" SG_ 2149924864 DSMSS_DrvSelMd7Un 1;
BA_ "SignalType" SG_ 2149924864 DSMSS_DrvSelMd7Un "BLN";
BA_ "PacketOrder" SG_ 2149924864 DSMSS_DrvSelMd7Un 7;
BA_ "SignalLongName" SG_ 2149924864 DSMSS_DrvSelMd7Un "Driver Selected Mode Selection Status : Driver Selected Mode 7 Unavailable";
BA_ "VNSigAllNodes" SG_ 2149924864 DSMSS_DrvSelMd7Un 1;
BA_ "GenSigSendType" SG_ 2149924864 DSMSS_DrvSelMd6Un 10;
BA_ "GenSigSendOnInit" SG_ 2149924864 DSMSS_DrvSelMd6Un 1;
BA_ "SignalType" SG_ 2149924864 DSMSS_DrvSelMd6Un "BLN";
BA_ "PacketOrder" SG_ 2149924864 DSMSS_DrvSelMd6Un 6;
BA_ "SignalLongName" SG_ 2149924864 DSMSS_DrvSelMd6Un "Driver Selected Mode Selection Status : Driver Selected Mode 6 Unavailable";
BA_ "VNSigAllNodes" SG_ 2149924864 DSMSS_DrvSelMd6Un 1;
BA_ "GenSigSendType" SG_ 2149924864 DSMSS_DrvSelMd5Un 10;
BA_ "GenSigSendOnInit" SG_ 2149924864 DSMSS_DrvSelMd5Un 1;
BA_ "SignalType" SG_ 2149924864 DSMSS_DrvSelMd5Un "BLN";
BA_ "PacketOrder" SG_ 2149924864 DSMSS_DrvSelMd5Un 5;
BA_ "SignalLongName" SG_ 2149924864 DSMSS_DrvSelMd5Un "Driver Selected Mode Selection Status : Driver Selected Mode 5 Unavailable";
BA_ "VNSigAllNodes" SG_ 2149924864 DSMSS_DrvSelMd5Un 1;
BA_ "GenSigSendType" SG_ 2149924864 DSMSS_DrvSelMd4Un 10;
BA_ "GenSigSendOnInit" SG_ 2149924864 DSMSS_DrvSelMd4Un 1;
BA_ "SignalType" SG_ 2149924864 DSMSS_DrvSelMd4Un "BLN";
BA_ "PacketOrder" SG_ 2149924864 DSMSS_DrvSelMd4Un 4;
BA_ "SignalLongName" SG_ 2149924864 DSMSS_DrvSelMd4Un "Driver Selected Mode Selection Status : Driver Selected Mode 4 Unavailable";
BA_ "VNSigAllNodes" SG_ 2149924864 DSMSS_DrvSelMd4Un 1;
BA_ "GenSigSendType" SG_ 2149924864 DSMSS_DrvSelMd3Un 10;
BA_ "GenSigSendOnInit" SG_ 2149924864 DSMSS_DrvSelMd3Un 1;
BA_ "SignalType" SG_ 2149924864 DSMSS_DrvSelMd3Un "BLN";
BA_ "PacketOrder" SG_ 2149924864 DSMSS_DrvSelMd3Un 3;
BA_ "SignalLongName" SG_ 2149924864 DSMSS_DrvSelMd3Un "Driver Selected Mode Selection Status : Driver Selected Mode 3 Unavailable";
BA_ "VNSigAllNodes" SG_ 2149924864 DSMSS_DrvSelMd3Un 1;
BA_ "GenSigSendType" SG_ 2149924864 DSMSS_DrvSelMd2Un 10;
BA_ "GenSigSendOnInit" SG_ 2149924864 DSMSS_DrvSelMd2Un 1;
BA_ "SignalType" SG_ 2149924864 DSMSS_DrvSelMd2Un "BLN";
BA_ "PacketOrder" SG_ 2149924864 DSMSS_DrvSelMd2Un 2;
BA_ "SignalLongName" SG_ 2149924864 DSMSS_DrvSelMd2Un "Driver Selected Mode Selection Status : Driver Selected Mode 2 Unavailable";
BA_ "VNSigAllNodes" SG_ 2149924864 DSMSS_DrvSelMd2Un 1;
BA_ "GenSigSendType" SG_ 2149924864 DSMSS_DrvSelMd1Un 10;
BA_ "GenSigSendOnInit" SG_ 2149924864 DSMSS_DrvSelMd1Un 1;
BA_ "SignalType" SG_ 2149924864 DSMSS_DrvSelMd1Un "BLN";
BA_ "PacketOrder" SG_ 2149924864 DSMSS_DrvSelMd1Un 1;
BA_ "SignalLongName" SG_ 2149924864 DSMSS_DrvSelMd1Un "Driver Selected Mode Selection Status : Driver Selected Mode 1 Unavailable";
BA_ "VNSigAllNodes" SG_ 2149924864 DSMSS_DrvSelMd1Un 1;
BA_ "GenSigSendType" SG_ 2149924864 DrvSelMd3Stat 10;
BA_ "GenSigSendOnInit" SG_ 2149924864 DrvSelMd3Stat 1;
BA_ "SignalType" SG_ 2149924864 DrvSelMd3Stat "ENM";
BA_ "SignalLongName" SG_ 2149924864 DrvSelMd3Stat "Driver Selected Mode 3 Status";
BA_ "VNSigAllNodes" SG_ 2149924864 DrvSelMd3Stat 1;
BA_ "GenSigSendType" SG_ 2149924864 DrvSelMd3ReqDnd 10;
BA_ "SignalType" SG_ 2149924864 DrvSelMd3ReqDnd "BLN";
BA_ "SignalLongName" SG_ 2149924864 DrvSelMd3ReqDnd "Driver Selected Mode 3 Request Denied";
BA_ "VNSigAllNodes" SG_ 2149924864 DrvSelMd3ReqDnd 1;
BA_ "GenSigSendType" SG_ 2149924864 DrvSelMd2Stat 10;
BA_ "GenSigSendOnInit" SG_ 2149924864 DrvSelMd2Stat 1;
BA_ "SignalType" SG_ 2149924864 DrvSelMd2Stat "ENM";
BA_ "SignalLongName" SG_ 2149924864 DrvSelMd2Stat "Driver Selected Mode 2 Status";
BA_ "VNSigAllNodes" SG_ 2149924864 DrvSelMd2Stat 1;
BA_ "GenSigSendType" SG_ 2149924864 DrvSelMd2ReqDnd 10;
BA_ "SignalType" SG_ 2149924864 DrvSelMd2ReqDnd "BLN";
BA_ "SignalLongName" SG_ 2149924864 DrvSelMd2ReqDnd "Driver Selected Mode 2 Request Denied";
BA_ "VNSigAllNodes" SG_ 2149924864 DrvSelMd2ReqDnd 1;
BA_ "GenSigSendType" SG_ 2149924864 DrvSelMd1Stat 10;
BA_ "GenSigSendOnInit" SG_ 2149924864 DrvSelMd1Stat 1;
BA_ "SignalType" SG_ 2149924864 DrvSelMd1Stat "ENM";
BA_ "SignalLongName" SG_ 2149924864 DrvSelMd1Stat "Driver Selected Mode 1 Status";
BA_ "VNSigAllNodes" SG_ 2149924864 DrvSelMd1Stat 1;
BA_ "GenSigSendType" SG_ 2149924864 DrvSelMd1ReqDnd 10;
BA_ "SignalType" SG_ 2149924864 DrvSelMd1ReqDnd "BLN";
BA_ "SignalLongName" SG_ 2149924864 DrvSelMd1ReqDnd "Driver Selected Mode 1 Request Denied";
BA_ "VNSigAllNodes" SG_ 2149924864 DrvSelMd1ReqDnd 1;
BA_ "GenSigSendType" SG_ 2149924864 CPSCA_Resrv3Avail 10;
BA_ "GenSigSendOnInit" SG_ 2149924864 CPSCA_Resrv3Avail 1;
BA_ "PacketOrder" SG_ 2149924864 CPSCA_Resrv3Avail 7;
BA_ "SignalType" SG_ 2149924864 CPSCA_Resrv3Avail "BLN";
BA_ "SignalLongName" SG_ 2149924864 CPSCA_Resrv3Avail "Collision Preparation System Customization Available : Reserved3 Available";
BA_ "VNSigAllNodes" SG_ 2149924864 CPSCA_Resrv3Avail 1;
BA_ "GenSigSendType" SG_ 2149924864 CPSCA_Resrv2Avail 10;
BA_ "GenSigSendOnInit" SG_ 2149924864 CPSCA_Resrv2Avail 1;
BA_ "PacketOrder" SG_ 2149924864 CPSCA_Resrv2Avail 6;
BA_ "SignalType" SG_ 2149924864 CPSCA_Resrv2Avail "BLN";
BA_ "SignalLongName" SG_ 2149924864 CPSCA_Resrv2Avail "Collision Preparation System Customization Available : Reserved2 Available";
BA_ "VNSigAllNodes" SG_ 2149924864 CPSCA_Resrv2Avail 1;
BA_ "GenSigSendType" SG_ 2149924864 CPSCA_Resrv1Avail 10;
BA_ "GenSigSendOnInit" SG_ 2149924864 CPSCA_Resrv1Avail 1;
BA_ "PacketOrder" SG_ 2149924864 CPSCA_Resrv1Avail 5;
BA_ "SignalType" SG_ 2149924864 CPSCA_Resrv1Avail "BLN";
BA_ "SignalLongName" SG_ 2149924864 CPSCA_Resrv1Avail "Collision Preparation System Customization Available : Reserved1 Available";
BA_ "VNSigAllNodes" SG_ 2149924864 CPSCA_Resrv1Avail 1;
BA_ "GenSigSendType" SG_ 2149924864 CPSCA_AlrtBrkStrAvail 10;
BA_ "GenSigSendOnInit" SG_ 2149924864 CPSCA_AlrtBrkStrAvail 1;
BA_ "PacketOrder" SG_ 2149924864 CPSCA_AlrtBrkStrAvail 4;
BA_ "SignalType" SG_ 2149924864 CPSCA_AlrtBrkStrAvail "BLN";
BA_ "SignalLongName" SG_ 2149924864 CPSCA_AlrtBrkStrAvail "Collision Preparation System Customization Available : Alert and Brake and Steer Available";
BA_ "VNSigAllNodes" SG_ 2149924864 CPSCA_AlrtBrkStrAvail 1;
BA_ "GenSigSendType" SG_ 2149924864 CPSCA_AlrtBrkAvail 10;
BA_ "GenSigSendOnInit" SG_ 2149924864 CPSCA_AlrtBrkAvail 1;
BA_ "PacketOrder" SG_ 2149924864 CPSCA_AlrtBrkAvail 3;
BA_ "GenSigStartValue" SG_ 2149924864 CPSCA_AlrtBrkAvail 1;
BA_ "SignalType" SG_ 2149924864 CPSCA_AlrtBrkAvail "BLN";
BA_ "SignalLongName" SG_ 2149924864 CPSCA_AlrtBrkAvail "Collision Preparation System Customization Available : Alert and Brake Available";
BA_ "VNSigAllNodes" SG_ 2149924864 CPSCA_AlrtBrkAvail 1;
BA_ "GenSigSendType" SG_ 2149924864 CPSCA_AlrtAvail 10;
BA_ "GenSigSendOnInit" SG_ 2149924864 CPSCA_AlrtAvail 1;
BA_ "PacketOrder" SG_ 2149924864 CPSCA_AlrtAvail 2;
BA_ "GenSigStartValue" SG_ 2149924864 CPSCA_AlrtAvail 1;
BA_ "SignalType" SG_ 2149924864 CPSCA_AlrtAvail "BLN";
BA_ "SignalLongName" SG_ 2149924864 CPSCA_AlrtAvail "Collision Preparation System Customization Available : Alert Available";
BA_ "VNSigAllNodes" SG_ 2149924864 CPSCA_AlrtAvail 1;
BA_ "GenSigSendType" SG_ 2149924864 CPSCA_OffAvail 10;
BA_ "GenSigSendOnInit" SG_ 2149924864 CPSCA_OffAvail 1;
BA_ "PacketOrder" SG_ 2149924864 CPSCA_OffAvail 1;
BA_ "GenSigStartValue" SG_ 2149924864 CPSCA_OffAvail 1;
BA_ "SignalType" SG_ 2149924864 CPSCA_OffAvail "BLN";
BA_ "SignalLongName" SG_ 2149924864 CPSCA_OffAvail "Collision Preparation System Customization Available : Off Available";
BA_ "VNSigAllNodes" SG_ 2149924864 CPSCA_OffAvail 1;
BA_ "GenSigSendType" SG_ 2152054784 FuelEconMetDispUnts 10;
BA_ "GenSigSendOnInit" SG_ 2152054784 FuelEconMetDispUnts 1;
BA_ "VNSigInfotainment" SG_ 2152054784 FuelEconMetDispUnts 1;
BA_ "SignalType" SG_ 2152054784 FuelEconMetDispUnts "ENM";
BA_ "SignalLongName" SG_ 2152054784 FuelEconMetDispUnts "Fuel Economy Metric Display Units";
BA_ "VNSigAllNodes" SG_ 2152054784 FuelEconMetDispUnts 1;
BA_ "GenSigSendType" SG_ 2152054784 IntPnlClstrAnmtStat 10;
BA_ "SignalType" SG_ 2152054784 IntPnlClstrAnmtStat "ENM";
BA_ "SignalLongName" SG_ 2152054784 IntPnlClstrAnmtStat "Instrument Panel Cluster Animation Status";
BA_ "VNSigAllNodes" SG_ 2152054784 IntPnlClstrAnmtStat 1;
BA_ "GenSigSendType" SG_ 2152054784 AnmStrtReq 10;
BA_ "SignalType" SG_ 2152054784 AnmStrtReq "ENM";
BA_ "SignalLongName" SG_ 2152054784 AnmStrtReq "Animation Start Request";
BA_ "VNSigAllNodes" SG_ 2152054784 AnmStrtReq 1;
BA_ "GenSigSendType" SG_ 2150301696 WlcAnmReq 10;
BA_ "SignalType" SG_ 2150301696 WlcAnmReq "BLN";
BA_ "SignalLongName" SG_ 2150301696 WlcAnmReq "Welcome Animation Request";
BA_ "VNSigAllNodes" SG_ 2150301696 WlcAnmReq 1;
BA_ "GenSigSendType" SG_ 2150563840 PsStStatDispAct 10;
BA_ "GenSigSendOnInit" SG_ 2150563840 PsStStatDispAct 2;
BA_ "SignalType" SG_ 2150563840 PsStStatDispAct "BLN";
BA_ "SignalLongName" SG_ 2150563840 PsStStatDispAct "Passenger Seat Status Display Active";
BA_ "VNSigAllNodes" SG_ 2150563840 PsStStatDispAct 1;
BA_ "GenSigSendType" SG_ 2150563840 DrStStatDispAct 10;
BA_ "GenSigSendOnInit" SG_ 2150563840 DrStStatDispAct 2;
BA_ "SignalType" SG_ 2150563840 DrStStatDispAct "BLN";
BA_ "SignalLongName" SG_ 2150563840 DrStStatDispAct "Driver Seat Status Display Active";
BA_ "VNSigAllNodes" SG_ 2150563840 DrStStatDispAct 1;
BA_ "GenSigSendType" SG_ 2150563840 RadAudQueStat 10;
BA_ "GenSigSendOnInit" SG_ 2150563840 RadAudQueStat 2;
BA_ "SignalType" SG_ 2150563840 RadAudQueStat "ENM";
BA_ "SignalLongName" SG_ 2150563840 RadAudQueStat "Radio Audio Queue Status";
BA_ "VNSigAllNodes" SG_ 2150563840 RadAudQueStat 1;
BA_ "GenSigSendType" SG_ 2150563840 RadAnmtStat 10;
BA_ "GenSigSendOnInit" SG_ 2150563840 RadAnmtStat 2;
BA_ "SignalType" SG_ 2150563840 RadAnmtStat "ENM";
BA_ "SignalLongName" SG_ 2150563840 RadAnmtStat "Radio Animation Status";
BA_ "VNSigAllNodes" SG_ 2150563840 RadAnmtStat 1;
BA_ "GenSigSendType" SG_ 2154758144 ChldLckOtSwAct 10;
BA_ "GenSigSendOnInit" SG_ 2154758144 ChldLckOtSwAct 2;
BA_ "SignalType" SG_ 2154758144 ChldLckOtSwAct "BLN";
BA_ "SignalLongName" SG_ 2154758144 ChldLckOtSwAct "Child Lock Out Switch Active";
BA_ "VNSigAllNodes" SG_ 2154758144 ChldLckOtSwAct 1;
BA_ "GenSigSendType" SG_ 2154577920 ASS_DSPMd7Prsnt 10;
BA_ "GenSigSendOnInit" SG_ 2154577920 ASS_DSPMd7Prsnt 1;
BA_ "VNSigInfotainment" SG_ 2154577920 ASS_DSPMd7Prsnt 1;
BA_ "SignalType" SG_ 2154577920 ASS_DSPMd7Prsnt "BLN";
BA_ "PacketOrder" SG_ 2154577920 ASS_DSPMd7Prsnt 13;
BA_ "SignalLongName" SG_ 2154577920 ASS_DSPMd7Prsnt "Amplifier Sink Status : DSP Mode 7 Present";
BA_ "VNSigAllNodes" SG_ 2154577920 ASS_DSPMd7Prsnt 1;
BA_ "GenSigSendType" SG_ 2154577920 ASS_DSPMd6Prsnt 10;
BA_ "GenSigSendOnInit" SG_ 2154577920 ASS_DSPMd6Prsnt 1;
BA_ "VNSigInfotainment" SG_ 2154577920 ASS_DSPMd6Prsnt 1;
BA_ "SignalType" SG_ 2154577920 ASS_DSPMd6Prsnt "BLN";
BA_ "PacketOrder" SG_ 2154577920 ASS_DSPMd6Prsnt 12;
BA_ "SignalLongName" SG_ 2154577920 ASS_DSPMd6Prsnt "Amplifier Sink Status : DSP Mode 6 Present";
BA_ "VNSigAllNodes" SG_ 2154577920 ASS_DSPMd6Prsnt 1;
BA_ "GenSigSendType" SG_ 2154577920 ASS_DSPMd5Prsnt 10;
BA_ "GenSigSendOnInit" SG_ 2154577920 ASS_DSPMd5Prsnt 1;
BA_ "VNSigInfotainment" SG_ 2154577920 ASS_DSPMd5Prsnt 1;
BA_ "SignalType" SG_ 2154577920 ASS_DSPMd5Prsnt "BLN";
BA_ "PacketOrder" SG_ 2154577920 ASS_DSPMd5Prsnt 11;
BA_ "SignalLongName" SG_ 2154577920 ASS_DSPMd5Prsnt "Amplifier Sink Status : DSP Mode 5 Present";
BA_ "VNSigAllNodes" SG_ 2154577920 ASS_DSPMd5Prsnt 1;
BA_ "GenSigSendType" SG_ 2154577920 ASS_DSPMd4Prsnt 10;
BA_ "GenSigSendOnInit" SG_ 2154577920 ASS_DSPMd4Prsnt 1;
BA_ "VNSigInfotainment" SG_ 2154577920 ASS_DSPMd4Prsnt 1;
BA_ "SignalType" SG_ 2154577920 ASS_DSPMd4Prsnt "BLN";
BA_ "PacketOrder" SG_ 2154577920 ASS_DSPMd4Prsnt 10;
BA_ "SignalLongName" SG_ 2154577920 ASS_DSPMd4Prsnt "Amplifier Sink Status : DSP Mode 4 Present";
BA_ "VNSigAllNodes" SG_ 2154577920 ASS_DSPMd4Prsnt 1;
BA_ "GenSigSendType" SG_ 2154577920 ASS_DSPMd3Prsnt 10;
BA_ "GenSigSendOnInit" SG_ 2154577920 ASS_DSPMd3Prsnt 1;
BA_ "VNSigInfotainment" SG_ 2154577920 ASS_DSPMd3Prsnt 1;
BA_ "SignalType" SG_ 2154577920 ASS_DSPMd3Prsnt "BLN";
BA_ "PacketOrder" SG_ 2154577920 ASS_DSPMd3Prsnt 9;
BA_ "SignalLongName" SG_ 2154577920 ASS_DSPMd3Prsnt "Amplifier Sink Status : DSP Mode 3 Present";
BA_ "VNSigAllNodes" SG_ 2154577920 ASS_DSPMd3Prsnt 1;
BA_ "GenSigSendType" SG_ 2154577920 ASS_DSPMd2Prsnt 10;
BA_ "GenSigSendOnInit" SG_ 2154577920 ASS_DSPMd2Prsnt 1;
BA_ "VNSigInfotainment" SG_ 2154577920 ASS_DSPMd2Prsnt 1;
BA_ "SignalType" SG_ 2154577920 ASS_DSPMd2Prsnt "BLN";
BA_ "PacketOrder" SG_ 2154577920 ASS_DSPMd2Prsnt 8;
BA_ "SignalLongName" SG_ 2154577920 ASS_DSPMd2Prsnt "Amplifier Sink Status : DSP Mode 2 Present";
BA_ "VNSigAllNodes" SG_ 2154577920 ASS_DSPMd2Prsnt 1;
BA_ "GenSigSendType" SG_ 2154577920 ASS_DSPMd1Prsnt 10;
BA_ "GenSigSendOnInit" SG_ 2154577920 ASS_DSPMd1Prsnt 1;
BA_ "VNSigInfotainment" SG_ 2154577920 ASS_DSPMd1Prsnt 1;
BA_ "SignalType" SG_ 2154577920 ASS_DSPMd1Prsnt "BLN";
BA_ "PacketOrder" SG_ 2154577920 ASS_DSPMd1Prsnt 7;
BA_ "SignalLongName" SG_ 2154577920 ASS_DSPMd1Prsnt "Amplifier Sink Status : DSP Mode 1 Present";
BA_ "VNSigAllNodes" SG_ 2154577920 ASS_DSPMd1Prsnt 1;
BA_ "GenSigSendType" SG_ 2154577920 ASS_DSPMd0Prsnt 10;
BA_ "GenSigSendOnInit" SG_ 2154577920 ASS_DSPMd0Prsnt 1;
BA_ "VNSigInfotainment" SG_ 2154577920 ASS_DSPMd0Prsnt 1;
BA_ "SignalType" SG_ 2154577920 ASS_DSPMd0Prsnt "BLN";
BA_ "PacketOrder" SG_ 2154577920 ASS_DSPMd0Prsnt 6;
BA_ "SignalLongName" SG_ 2154577920 ASS_DSPMd0Prsnt "Amplifier Sink Status : DSP Mode 0 Present";
BA_ "VNSigAllNodes" SG_ 2154577920 ASS_DSPMd0Prsnt 1;
BA_ "GenSigSendType" SG_ 2154577920 ASS_SurndAvail 10;
BA_ "GenSigSendOnInit" SG_ 2154577920 ASS_SurndAvail 1;
BA_ "PacketOrder" SG_ 2154577920 ASS_SurndAvail 5;
BA_ "VNSigInfotainment" SG_ 2154577920 ASS_SurndAvail 1;
BA_ "SignalType" SG_ 2154577920 ASS_SurndAvail "BLN";
BA_ "SignalLongName" SG_ 2154577920 ASS_SurndAvail "Amplifier Sink Status : Suround Available";
BA_ "VNSigAllNodes" SG_ 2154577920 ASS_SurndAvail 1;
BA_ "GenSigSendType" SG_ 2154577920 ASS_DSPAvail 10;
BA_ "GenSigSendOnInit" SG_ 2154577920 ASS_DSPAvail 1;
BA_ "PacketOrder" SG_ 2154577920 ASS_DSPAvail 4;
BA_ "VNSigInfotainment" SG_ 2154577920 ASS_DSPAvail 1;
BA_ "SignalType" SG_ 2154577920 ASS_DSPAvail "BLN";
BA_ "SignalLongName" SG_ 2154577920 ASS_DSPAvail "Amplifier Sink Status : DSP Available";
BA_ "VNSigAllNodes" SG_ 2154577920 ASS_DSPAvail 1;
BA_ "GenSigSendType" SG_ 2154577920 ASS_VehNoisCmpnAvail 10;
BA_ "GenSigSendOnInit" SG_ 2154577920 ASS_VehNoisCmpnAvail 1;
BA_ "PacketOrder" SG_ 2154577920 ASS_VehNoisCmpnAvail 3;
BA_ "VNSigInfotainment" SG_ 2154577920 ASS_VehNoisCmpnAvail 1;
BA_ "SignalType" SG_ 2154577920 ASS_VehNoisCmpnAvail "BLN";
BA_ "SignalLongName" SG_ 2154577920 ASS_VehNoisCmpnAvail "Amplifier Sink Status : Vehicle Noise Compensation Available";
BA_ "VNSigAllNodes" SG_ 2154577920 ASS_VehNoisCmpnAvail 1;
BA_ "GenSigSendType" SG_ 2154577920 ASS_PhLckdLpLckd 10;
BA_ "GenSigSendOnInit" SG_ 2154577920 ASS_PhLckdLpLckd 1;
BA_ "PacketOrder" SG_ 2154577920 ASS_PhLckdLpLckd 2;
BA_ "VNSigInfotainment" SG_ 2154577920 ASS_PhLckdLpLckd 1;
BA_ "SignalType" SG_ 2154577920 ASS_PhLckdLpLckd "BLN";
BA_ "SignalLongName" SG_ 2154577920 ASS_PhLckdLpLckd "Amplifier Sink Status : Phase Locked Loop Locked";
BA_ "VNSigAllNodes" SG_ 2154577920 ASS_PhLckdLpLckd 1;
BA_ "GenSigSendType" SG_ 2154577920 ASS_MtxSnkMutStat 10;
BA_ "GenSigSendOnInit" SG_ 2154577920 ASS_MtxSnkMutStat 1;
BA_ "PacketOrder" SG_ 2154577920 ASS_MtxSnkMutStat 1;
BA_ "VNSigInfotainment" SG_ 2154577920 ASS_MtxSnkMutStat 1;
BA_ "SignalType" SG_ 2154577920 ASS_MtxSnkMutStat "BLN";
BA_ "SignalLongName" SG_ 2154577920 ASS_MtxSnkMutStat "Amplifier Sink Status : Mutex Sink Mute Status";
BA_ "VNSigAllNodes" SG_ 2154577920 ASS_MtxSnkMutStat 1;
BA_ "GenSigSendType" SG_ 2154594304 InfotnBkltngConfigSt 10;
BA_ "GenSigSendOnInit" SG_ 2154594304 InfotnBkltngConfigSt 1;
BA_ "VNSigInfotainment" SG_ 2154594304 InfotnBkltngConfigSt 1;
BA_ "SignalType" SG_ 2154594304 InfotnBkltngConfigSt "ENM";
BA_ "SignalLongName" SG_ 2154594304 InfotnBkltngConfigSt "Infotainment Backlighting Configuration State";
BA_ "VNSigAllNodes" SG_ 2154594304 InfotnBkltngConfigSt 1;
BA_ "GenSigSendType" SG_ 2154594304 ASTC_GblAudSnkMut 10;
BA_ "GenSigSendOnInit" SG_ 2154594304 ASTC_GblAudSnkMut 1;
BA_ "PacketOrder" SG_ 2154594304 ASTC_GblAudSnkMut 9;
BA_ "VNSigInfotainment" SG_ 2154594304 ASTC_GblAudSnkMut 1;
BA_ "SignalType" SG_ 2154594304 ASTC_GblAudSnkMut "BLN";
BA_ "SignalLongName" SG_ 2154594304 ASTC_GblAudSnkMut "Amplifier Settings Tone Control : Global Audio Sink Mute";
BA_ "VNSigAllNodes" SG_ 2154594304 ASTC_GblAudSnkMut 1;
BA_ "GenSigSendType" SG_ 2154594304 ASTC_AmpLwPwrSt 10;
BA_ "GenSigSendOnInit" SG_ 2154594304 ASTC_AmpLwPwrSt 1;
BA_ "PacketOrder" SG_ 2154594304 ASTC_AmpLwPwrSt 8;
BA_ "VNSigInfotainment" SG_ 2154594304 ASTC_AmpLwPwrSt 1;
BA_ "SignalType" SG_ 2154594304 ASTC_AmpLwPwrSt "BLN";
BA_ "SignalLongName" SG_ 2154594304 ASTC_AmpLwPwrSt "Amplifier Settings Tone Control : Amplfier Low Power State";
BA_ "VNSigAllNodes" SG_ 2154594304 ASTC_AmpLwPwrSt 1;
BA_ "GenSigDeltaValue" SG_ 2154594304 ASTC_MtxSnkMutRmpTm 1;
BA_ "GenSigSendType" SG_ 2154594304 ASTC_MtxSnkMutRmpTm 12;
BA_ "GenSigSendOnInit" SG_ 2154594304 ASTC_MtxSnkMutRmpTm 1;
BA_ "PacketOrder" SG_ 2154594304 ASTC_MtxSnkMutRmpTm 7;
BA_ "VNSigInfotainment" SG_ 2154594304 ASTC_MtxSnkMutRmpTm 1;
BA_ "SignalType" SG_ 2154594304 ASTC_MtxSnkMutRmpTm "UNM";
BA_ "SignalLongName" SG_ 2154594304 ASTC_MtxSnkMutRmpTm "Amplifier Settings Tone Control : Mutex Sink Mute Ramp Time";
BA_ "VNSigAllNodes" SG_ 2154594304 ASTC_MtxSnkMutRmpTm 1;
BA_ "GenSigSendType" SG_ 2154594304 ASTC_MtxSnkMut 10;
BA_ "GenSigSendOnInit" SG_ 2154594304 ASTC_MtxSnkMut 1;
BA_ "PacketOrder" SG_ 2154594304 ASTC_MtxSnkMut 6;
BA_ "VNSigInfotainment" SG_ 2154594304 ASTC_MtxSnkMut 1;
BA_ "SignalType" SG_ 2154594304 ASTC_MtxSnkMut "BLN";
BA_ "SignalLongName" SG_ 2154594304 ASTC_MtxSnkMut "Amplifier Settings Tone Control : Mutex Sink Mute";
BA_ "VNSigAllNodes" SG_ 2154594304 ASTC_MtxSnkMut 1;
BA_ "GenSigSendType" SG_ 2154594304 ASTC_DSPMd 10;
BA_ "GenSigSendOnInit" SG_ 2154594304 ASTC_DSPMd 1;
BA_ "PacketOrder" SG_ 2154594304 ASTC_DSPMd 5;
BA_ "VNSigInfotainment" SG_ 2154594304 ASTC_DSPMd 1;
BA_ "SignalType" SG_ 2154594304 ASTC_DSPMd "ENM";
BA_ "SignalLongName" SG_ 2154594304 ASTC_DSPMd "Amplifier Settings Tone Control : DSP Mode";
BA_ "VNSigAllNodes" SG_ 2154594304 ASTC_DSPMd 1;
BA_ "GenSigSendType" SG_ 2154594304 ASTC_VehNoisCmpnAct 10;
BA_ "GenSigSendOnInit" SG_ 2154594304 ASTC_VehNoisCmpnAct 1;
BA_ "PacketOrder" SG_ 2154594304 ASTC_VehNoisCmpnAct 4;
BA_ "VNSigInfotainment" SG_ 2154594304 ASTC_VehNoisCmpnAct 1;
BA_ "SignalType" SG_ 2154594304 ASTC_VehNoisCmpnAct "BLN";
BA_ "SignalLongName" SG_ 2154594304 ASTC_VehNoisCmpnAct "Amplifier Settings Tone Control : Vehicle Noise Compensation Active";
BA_ "VNSigAllNodes" SG_ 2154594304 ASTC_VehNoisCmpnAct 1;
BA_ "GenSigDeltaValue" SG_ 2154594304 ASTC_SurndLvl 1;
BA_ "GenSigSendType" SG_ 2154594304 ASTC_SurndLvl 12;
BA_ "GenSigSendOnInit" SG_ 2154594304 ASTC_SurndLvl 1;
BA_ "PacketOrder" SG_ 2154594304 ASTC_SurndLvl 3;
BA_ "VNSigInfotainment" SG_ 2154594304 ASTC_SurndLvl 1;
BA_ "SignalType" SG_ 2154594304 ASTC_SurndLvl "SNM";
BA_ "SignalLongName" SG_ 2154594304 ASTC_SurndLvl "Amplifier Settings Tone Control : Surround Level";
BA_ "VNSigAllNodes" SG_ 2154594304 ASTC_SurndLvl 1;
BA_ "GenSigSendType" SG_ 2154594304 ASTC_ChimSnkSpkrPos 10;
BA_ "GenSigSendOnInit" SG_ 2154594304 ASTC_ChimSnkSpkrPos 1;
BA_ "PacketOrder" SG_ 2154594304 ASTC_ChimSnkSpkrPos 2;
BA_ "VNSigInfotainment" SG_ 2154594304 ASTC_ChimSnkSpkrPos 1;
BA_ "SignalType" SG_ 2154594304 ASTC_ChimSnkSpkrPos "ENM";
BA_ "SignalLongName" SG_ 2154594304 ASTC_ChimSnkSpkrPos "Amplifier Settings Tone Control : Chime Sink Speaker Position";
BA_ "VNSigAllNodes" SG_ 2154594304 ASTC_ChimSnkSpkrPos 1;
BA_ "GenSigDeltaValue" SG_ 2154594304 ASTC_ChimSnkLvl 1;
BA_ "GenSigSendType" SG_ 2154594304 ASTC_ChimSnkLvl 12;
BA_ "GenSigSendOnInit" SG_ 2154594304 ASTC_ChimSnkLvl 1;
BA_ "PacketOrder" SG_ 2154594304 ASTC_ChimSnkLvl 1;
BA_ "VNSigInfotainment" SG_ 2154594304 ASTC_ChimSnkLvl 1;
BA_ "SignalType" SG_ 2154594304 ASTC_ChimSnkLvl "UNM";
BA_ "SignalLongName" SG_ 2154594304 ASTC_ChimSnkLvl "Amplifier Settings Tone Control : Chime Sink Level";
BA_ "VNSigAllNodes" SG_ 2154594304 ASTC_ChimSnkLvl 1;
BA_ "GenSigSendType" SG_ 2154586112 ASSLC_AutoLdnsCmpnAct 10;
BA_ "GenSigSendOnInit" SG_ 2154586112 ASSLC_AutoLdnsCmpnAct 1;
BA_ "PacketOrder" SG_ 2154586112 ASSLC_AutoLdnsCmpnAct 11;
BA_ "VNSigInfotainment" SG_ 2154586112 ASSLC_AutoLdnsCmpnAct 1;
BA_ "SignalType" SG_ 2154586112 ASSLC_AutoLdnsCmpnAct "BLN";
BA_ "SignalLongName" SG_ 2154586112 ASSLC_AutoLdnsCmpnAct "Amplifier Settings Sink Level Control : Automatic Loudness Compensation Active";
BA_ "VNSigAllNodes" SG_ 2154586112 ASSLC_AutoLdnsCmpnAct 1;
BA_ "GenSigSendType" SG_ 2154586112 ASSLC_VcSrcActOnMtx 10;
BA_ "GenSigSendOnInit" SG_ 2154586112 ASSLC_VcSrcActOnMtx 1;
BA_ "PacketOrder" SG_ 2154586112 ASSLC_VcSrcActOnMtx 10;
BA_ "VNSigInfotainment" SG_ 2154586112 ASSLC_VcSrcActOnMtx 1;
BA_ "SignalType" SG_ 2154586112 ASSLC_VcSrcActOnMtx "BLN";
BA_ "SignalLongName" SG_ 2154586112 ASSLC_VcSrcActOnMtx "Amplifier Settings Sink Level Control : Voice Source Active On Mutex";
BA_ "VNSigAllNodes" SG_ 2154586112 ASSLC_VcSrcActOnMtx 1;
BA_ "GenSigDeltaValue" SG_ 2154586112 ASSLC_MtxSnkTrbl 1;
BA_ "GenSigSendType" SG_ 2154586112 ASSLC_MtxSnkTrbl 12;
BA_ "GenSigSendOnInit" SG_ 2154586112 ASSLC_MtxSnkTrbl 1;
BA_ "PacketOrder" SG_ 2154586112 ASSLC_MtxSnkTrbl 9;
BA_ "VNSigInfotainment" SG_ 2154586112 ASSLC_MtxSnkTrbl 1;
BA_ "SignalType" SG_ 2154586112 ASSLC_MtxSnkTrbl "SNM";
BA_ "SignalLongName" SG_ 2154586112 ASSLC_MtxSnkTrbl "Amplifier Settings Sink Level Control : Mutex Sink Treble";
BA_ "VNSigAllNodes" SG_ 2154586112 ASSLC_MtxSnkTrbl 1;
BA_ "GenSigDeltaValue" SG_ 2154586112 ASSLC_MtxSnkMdrng 1;
BA_ "GenSigSendType" SG_ 2154586112 ASSLC_MtxSnkMdrng 12;
BA_ "GenSigSendOnInit" SG_ 2154586112 ASSLC_MtxSnkMdrng 1;
BA_ "PacketOrder" SG_ 2154586112 ASSLC_MtxSnkMdrng 8;
BA_ "VNSigInfotainment" SG_ 2154586112 ASSLC_MtxSnkMdrng 1;
BA_ "SignalType" SG_ 2154586112 ASSLC_MtxSnkMdrng "SNM";
BA_ "SignalLongName" SG_ 2154586112 ASSLC_MtxSnkMdrng "Amplifier Settings Sink Level Control : Mutex Sink Midrange";
BA_ "VNSigAllNodes" SG_ 2154586112 ASSLC_MtxSnkMdrng 1;
BA_ "GenSigDeltaValue" SG_ 2154586112 ASSLC_MtxSnkBass 1;
BA_ "GenSigSendType" SG_ 2154586112 ASSLC_MtxSnkBass 12;
BA_ "GenSigSendOnInit" SG_ 2154586112 ASSLC_MtxSnkBass 1;
BA_ "PacketOrder" SG_ 2154586112 ASSLC_MtxSnkBass 7;
BA_ "VNSigInfotainment" SG_ 2154586112 ASSLC_MtxSnkBass 1;
BA_ "SignalType" SG_ 2154586112 ASSLC_MtxSnkBass "SNM";
BA_ "SignalLongName" SG_ 2154586112 ASSLC_MtxSnkBass "Amplifier Settings Sink Level Control : Mutex Sink Bass";
BA_ "VNSigAllNodes" SG_ 2154586112 ASSLC_MtxSnkBass 1;
BA_ "GenSigDeltaValue" SG_ 2154586112 ASSLC_MtxSnkFd 1;
BA_ "GenSigSendType" SG_ 2154586112 ASSLC_MtxSnkFd 12;
BA_ "GenSigSendOnInit" SG_ 2154586112 ASSLC_MtxSnkFd 1;
BA_ "PacketOrder" SG_ 2154586112 ASSLC_MtxSnkFd 6;
BA_ "VNSigInfotainment" SG_ 2154586112 ASSLC_MtxSnkFd 1;
BA_ "SignalType" SG_ 2154586112 ASSLC_MtxSnkFd "SNM";
BA_ "SignalLongName" SG_ 2154586112 ASSLC_MtxSnkFd "Amplifier Settings Sink Level Control : Mutex Sink Fade";
BA_ "VNSigAllNodes" SG_ 2154586112 ASSLC_MtxSnkFd 1;
BA_ "GenSigDeltaValue" SG_ 2154586112 ASSLC_MtxSnkBal 1;
BA_ "GenSigSendType" SG_ 2154586112 ASSLC_MtxSnkBal 12;
BA_ "GenSigSendOnInit" SG_ 2154586112 ASSLC_MtxSnkBal 1;
BA_ "PacketOrder" SG_ 2154586112 ASSLC_MtxSnkBal 5;
BA_ "VNSigInfotainment" SG_ 2154586112 ASSLC_MtxSnkBal 1;
BA_ "SignalType" SG_ 2154586112 ASSLC_MtxSnkBal "SNM";
BA_ "SignalLongName" SG_ 2154586112 ASSLC_MtxSnkBal "Amplifier Settings Sink Level Control : Mutex Sink Balance";
BA_ "VNSigAllNodes" SG_ 2154586112 ASSLC_MtxSnkBal 1;
BA_ "GenSigDeltaValue" SG_ 2154586112 ASSLC_FvSnkLvl 1;
BA_ "GenSigSendType" SG_ 2154586112 ASSLC_FvSnkLvl 12;
BA_ "GenSigSendOnInit" SG_ 2154586112 ASSLC_FvSnkLvl 1;
BA_ "PacketOrder" SG_ 2154586112 ASSLC_FvSnkLvl 4;
BA_ "VNSigInfotainment" SG_ 2154586112 ASSLC_FvSnkLvl 1;
BA_ "SignalType" SG_ 2154586112 ASSLC_FvSnkLvl "UNM";
BA_ "SignalLongName" SG_ 2154586112 ASSLC_FvSnkLvl "Amplifier Settings Sink Level Control : Five Sink Level";
BA_ "VNSigAllNodes" SG_ 2154586112 ASSLC_FvSnkLvl 1;
BA_ "GenSigDeltaValue" SG_ 2154586112 ASSLC_AudFdbkSnkLvl 1;
BA_ "GenSigSendType" SG_ 2154586112 ASSLC_AudFdbkSnkLvl 12;
BA_ "GenSigSendOnInit" SG_ 2154586112 ASSLC_AudFdbkSnkLvl 1;
BA_ "PacketOrder" SG_ 2154586112 ASSLC_AudFdbkSnkLvl 3;
BA_ "VNSigInfotainment" SG_ 2154586112 ASSLC_AudFdbkSnkLvl 1;
BA_ "SignalType" SG_ 2154586112 ASSLC_AudFdbkSnkLvl "UNM";
BA_ "SignalLongName" SG_ 2154586112 ASSLC_AudFdbkSnkLvl "Amplifier Settings Sink Level Control : Audible Feedback Sink Level";
BA_ "VNSigAllNodes" SG_ 2154586112 ASSLC_AudFdbkSnkLvl 1;
BA_ "GenSigDeltaValue" SG_ 2154586112 ASSLC_MxPrmtSnkLvl 1;
BA_ "GenSigSendType" SG_ 2154586112 ASSLC_MxPrmtSnkLvl 12;
BA_ "GenSigSendOnInit" SG_ 2154586112 ASSLC_MxPrmtSnkLvl 1;
BA_ "PacketOrder" SG_ 2154586112 ASSLC_MxPrmtSnkLvl 2;
BA_ "VNSigInfotainment" SG_ 2154586112 ASSLC_MxPrmtSnkLvl 1;
BA_ "SignalType" SG_ 2154586112 ASSLC_MxPrmtSnkLvl "UNM";
BA_ "SignalLongName" SG_ 2154586112 ASSLC_MxPrmtSnkLvl "Amplifier Settings Sink Level Control : Mix Prompt Sink Level";
BA_ "VNSigAllNodes" SG_ 2154586112 ASSLC_MxPrmtSnkLvl 1;
BA_ "GenSigDeltaValue" SG_ 2154586112 ASSLC_MtxSnkLvl 1;
BA_ "GenSigSendType" SG_ 2154586112 ASSLC_MtxSnkLvl 12;
BA_ "GenSigSendOnInit" SG_ 2154586112 ASSLC_MtxSnkLvl 1;
BA_ "PacketOrder" SG_ 2154586112 ASSLC_MtxSnkLvl 1;
BA_ "VNSigInfotainment" SG_ 2154586112 ASSLC_MtxSnkLvl 1;
BA_ "SignalType" SG_ 2154586112 ASSLC_MtxSnkLvl "UNM";
BA_ "SignalLongName" SG_ 2154586112 ASSLC_MtxSnkLvl "Amplifier Settings Sink Level Control : Mutex Sink Level";
BA_ "VNSigAllNodes" SG_ 2154586112 ASSLC_MtxSnkLvl 1;
BA_ "GenSigSendType" SG_ 2152857600 ACCGrnMdStat 10;
BA_ "SignalType" SG_ 2152857600 ACCGrnMdStat "ENM";
BA_ "SignalLongName" SG_ 2152857600 ACCGrnMdStat "Adaptive Cruise Control Green Mode Status";
BA_ "VNSigAllNodes" SG_ 2152857600 ACCGrnMdStat 1;
BA_ "GenSigSendType" SG_ 2152857600 ACCRteSpdAdaptStat 10;
BA_ "SignalType" SG_ 2152857600 ACCRteSpdAdaptStat "ENM";
BA_ "SignalLongName" SG_ 2152857600 ACCRteSpdAdaptStat "Adaptive Cruise Control Route Speed Adaption Status";
BA_ "VNSigAllNodes" SG_ 2152857600 ACCRteSpdAdaptStat 1;
BA_ "GenSigSendType" SG_ 2152857600 ACCRteSpdDrvIntvReq 10;
BA_ "SignalType" SG_ 2152857600 ACCRteSpdDrvIntvReq "ENM";
BA_ "SignalLongName" SG_ 2152857600 ACCRteSpdDrvIntvReq "Adaptive Cruise Control Route Speed Driver Intervention Request";
BA_ "VNSigAllNodes" SG_ 2152857600 ACCRteSpdDrvIntvReq 1;
BA_ "GenSigSendType" SG_ 2152857600 ACCTrfcJamAstActStat 10;
BA_ "SignalType" SG_ 2152857600 ACCTrfcJamAstActStat "ENM";
BA_ "SignalLongName" SG_ 2152857600 ACCTrfcJamAstActStat "Adaptive Cruise Control Traffic Jam Assist Activation Status";
BA_ "VNSigAllNodes" SG_ 2152857600 ACCTrfcJamAstActStat 1;
BA_ "GenSigDeltaValue" SG_ 2152857600 ACCTrfcJamAstRmnTm 1;
BA_ "GenSigSendType" SG_ 2152857600 ACCTrfcJamAstRmnTm 12;
BA_ "SignalType" SG_ 2152857600 ACCTrfcJamAstRmnTm "UNM";
BA_ "SignalLongName" SG_ 2152857600 ACCTrfcJamAstRmnTm "Adaptive Cruise Control Traffic Jam Assist Remaining Time";
BA_ "VNSigAllNodes" SG_ 2152857600 ACCTrfcJamAstRmnTm 1;
BA_ "GenSigSendType" SG_ 2158149632 ECHGCD_XAxTkMrkInterv 10;
BA_ "GenSigSendOnInit" SG_ 2158149632 ECHGCD_XAxTkMrkInterv 1;
BA_ "PacketOrder" SG_ 2158149632 ECHGCD_XAxTkMrkInterv 3;
BA_ "VNSigInfotainment" SG_ 2158149632 ECHGCD_XAxTkMrkInterv 1;
BA_ "SignalType" SG_ 2158149632 ECHGCD_XAxTkMrkInterv "ENM";
BA_ "SignalLongName" SG_ 2158149632 ECHGCD_XAxTkMrkInterv "Energy Consumption History Graph Configuration Data : X Axis Tick Mark Interval";
BA_ "VNSigAllNodes" SG_ 2158149632 ECHGCD_XAxTkMrkInterv 1;
BA_ "GenSigDeltaValue" SG_ 2158149632 ECHGCD_YAxMaxVal 1;
BA_ "GenSigSendType" SG_ 2158149632 ECHGCD_YAxMaxVal 12;
BA_ "GenSigSendOnInit" SG_ 2158149632 ECHGCD_YAxMaxVal 1;
BA_ "PacketOrder" SG_ 2158149632 ECHGCD_YAxMaxVal 2;
BA_ "VNSigInfotainment" SG_ 2158149632 ECHGCD_YAxMaxVal 1;
BA_ "SignalType" SG_ 2158149632 ECHGCD_YAxMaxVal "UNM";
BA_ "SignalLongName" SG_ 2158149632 ECHGCD_YAxMaxVal "Energy Consumption History Graph Configuration Data : Y Axis Maximum Value";
BA_ "VNSigAllNodes" SG_ 2158149632 ECHGCD_YAxMaxVal 1;
BA_ "GenSigSendType" SG_ 2158149632 ECHGCD_MeasUt 10;
BA_ "GenSigSendOnInit" SG_ 2158149632 ECHGCD_MeasUt 1;
BA_ "PacketOrder" SG_ 2158149632 ECHGCD_MeasUt 1;
BA_ "VNSigInfotainment" SG_ 2158149632 ECHGCD_MeasUt 1;
BA_ "SignalType" SG_ 2158149632 ECHGCD_MeasUt "ENM";
BA_ "SignalLongName" SG_ 2158149632 ECHGCD_MeasUt "Energy Consumption History Graph Configuration Data : Measurement Unit";
BA_ "VNSigAllNodes" SG_ 2158149632 ECHGCD_MeasUt 1;
BA_ "GenSigDeltaValue" SG_ 2158149632 EgyCnsHstGphInsEgyCns 1;
BA_ "GenSigSendType" SG_ 2158149632 EgyCnsHstGphInsEgyCns 12;
BA_ "GenSigSendOnInit" SG_ 2158149632 EgyCnsHstGphInsEgyCns 1;
BA_ "VNSigInfotainment" SG_ 2158149632 EgyCnsHstGphInsEgyCns 1;
BA_ "SignalType" SG_ 2158149632 EgyCnsHstGphInsEgyCns "UNM";
BA_ "SignalLongName" SG_ 2158149632 EgyCnsHstGphInsEgyCns "Energy Consumption History Graph Instantaneous Energy Consumption";
BA_ "VNSigAllNodes" SG_ 2158149632 EgyCnsHstGphInsEgyCns 1;
BA_ "GenSigDeltaValue" SG_ 2158149632 HVBTBSCR_SsnDyStat 1;
BA_ "GenSigSendType" SG_ 2158149632 HVBTBSCR_SsnDyStat 12;
BA_ "GenSigSendOnInit" SG_ 2158149632 HVBTBSCR_SsnDyStat 1;
BA_ "VNSigInfotainment" SG_ 2158149632 HVBTBSCR_SsnDyStat 1;
BA_ "SignalType" SG_ 2158149632 HVBTBSCR_SsnDyStat "UNM";
BA_ "PacketOrder" SG_ 2158149632 HVBTBSCR_SsnDyStat 4;
BA_ "SignalLongName" SG_ 2158149632 HVBTBSCR_SsnDyStat "High Voltage Battery Time Based Season Charging Response : Season Day Status";
BA_ "VNSigAllNodes" SG_ 2158149632 HVBTBSCR_SsnDyStat 1;
BA_ "GenSigSendType" SG_ 2158149632 HVBTBSCR_SsnStat 10;
BA_ "GenSigSendOnInit" SG_ 2158149632 HVBTBSCR_SsnStat 1;
BA_ "VNSigInfotainment" SG_ 2158149632 HVBTBSCR_SsnStat 1;
BA_ "SignalType" SG_ 2158149632 HVBTBSCR_SsnStat "ENM";
BA_ "PacketOrder" SG_ 2158149632 HVBTBSCR_SsnStat 1;
BA_ "SignalLongName" SG_ 2158149632 HVBTBSCR_SsnStat "High Voltage Battery Time Based Season Charging Response : Season Status";
BA_ "VNSigAllNodes" SG_ 2158149632 HVBTBSCR_SsnStat 1;
BA_ "GenSigSendType" SG_ 2158149632 HVBTBSCR_SsnSlctStat 10;
BA_ "GenSigSendOnInit" SG_ 2158149632 HVBTBSCR_SsnSlctStat 1;
BA_ "VNSigInfotainment" SG_ 2158149632 HVBTBSCR_SsnSlctStat 1;
BA_ "SignalType" SG_ 2158149632 HVBTBSCR_SsnSlctStat "ENM";
BA_ "PacketOrder" SG_ 2158149632 HVBTBSCR_SsnSlctStat 2;
BA_ "SignalLongName" SG_ 2158149632 HVBTBSCR_SsnSlctStat "High Voltage Battery Time Based Season Charging Response : Season Selected Status";
BA_ "VNSigAllNodes" SG_ 2158149632 HVBTBSCR_SsnSlctStat 1;
BA_ "GenSigSendType" SG_ 2158149632 HVBTBSCR_SsnMthStat 10;
BA_ "GenSigSendOnInit" SG_ 2158149632 HVBTBSCR_SsnMthStat 1;
BA_ "VNSigInfotainment" SG_ 2158149632 HVBTBSCR_SsnMthStat 1;
BA_ "SignalType" SG_ 2158149632 HVBTBSCR_SsnMthStat "ENM";
BA_ "PacketOrder" SG_ 2158149632 HVBTBSCR_SsnMthStat 3;
BA_ "SignalLongName" SG_ 2158149632 HVBTBSCR_SsnMthStat "High Voltage Battery Time Based Season Charging Response : Season Month Status";
BA_ "VNSigAllNodes" SG_ 2158149632 HVBTBSCR_SsnMthStat 1;
BA_ "GenSigSendType" SG_ 2158149632 HVBatTmBsChrgStRsp 10;
BA_ "GenSigSendOnInit" SG_ 2158149632 HVBatTmBsChrgStRsp 1;
BA_ "VNSigInfotainment" SG_ 2158149632 HVBatTmBsChrgStRsp 1;
BA_ "SignalType" SG_ 2158149632 HVBatTmBsChrgStRsp "ENM";
BA_ "SignalLongName" SG_ 2158149632 HVBatTmBsChrgStRsp "High Voltage Battery Time Based Charging Status Response";
BA_ "VNSigAllNodes" SG_ 2158149632 HVBatTmBsChrgStRsp 1;
BA_ "GenSigSendType" SG_ 2158149632 HVBTBCRS_ChRtDStat 10;
BA_ "GenSigSendOnInit" SG_ 2158149632 HVBTBCRS_ChRtDStat 1;
BA_ "VNSigInfotainment" SG_ 2158149632 HVBTBCRS_ChRtDStat 1;
BA_ "SignalType" SG_ 2158149632 HVBTBCRS_ChRtDStat "ENM";
BA_ "PacketOrder" SG_ 2158149632 HVBTBCRS_ChRtDStat 2;
BA_ "SignalLongName" SG_ 2158149632 HVBTBCRS_ChRtDStat "High Voltage Battery Time Based Charge Rate Response : Charge Rate Day Status";
BA_ "VNSigAllNodes" SG_ 2158149632 HVBTBCRS_ChRtDStat 1;
BA_ "GenSigSendType" SG_ 2158149632 HVBTBCRS_ChRtSlctStat 10;
BA_ "GenSigSendOnInit" SG_ 2158149632 HVBTBCRS_ChRtSlctStat 1;
BA_ "VNSigInfotainment" SG_ 2158149632 HVBTBCRS_ChRtSlctStat 1;
BA_ "SignalType" SG_ 2158149632 HVBTBCRS_ChRtSlctStat "ENM";
BA_ "PacketOrder" SG_ 2158149632 HVBTBCRS_ChRtSlctStat 3;
BA_ "SignalLongName" SG_ 2158149632 HVBTBCRS_ChRtSlctStat "High Voltage Battery Time Based Charge Rate Response : Charge Rate Selected Status";
BA_ "VNSigAllNodes" SG_ 2158149632 HVBTBCRS_ChRtSlctStat 1;
BA_ "GenSigSendType" SG_ 2158149632 HVBTBCRS_ChRtEnblStat 10;
BA_ "GenSigSendOnInit" SG_ 2158149632 HVBTBCRS_ChRtEnblStat 1;
BA_ "VNSigInfotainment" SG_ 2158149632 HVBTBCRS_ChRtEnblStat 1;
BA_ "SignalType" SG_ 2158149632 HVBTBCRS_ChRtEnblStat "ENM";
BA_ "PacketOrder" SG_ 2158149632 HVBTBCRS_ChRtEnblStat 1;
BA_ "SignalLongName" SG_ 2158149632 HVBTBCRS_ChRtEnblStat "High Voltage Battery Time Based Charge Rate Response : Charge Rate Enable Status";
BA_ "VNSigAllNodes" SG_ 2158149632 HVBTBCRS_ChRtEnblStat 1;
BA_ "GenSigSendType" SG_ 2158149632 HVBatCrgDspStat 10;
BA_ "VNSigInfotainment" SG_ 2158149632 HVBatCrgDspStat 1;
BA_ "SignalType" SG_ 2158149632 HVBatCrgDspStat "ENM";
BA_ "SignalLongName" SG_ 2158149632 HVBatCrgDspStat "High Voltage Battery Charge Display Status";
BA_ "VNSigAllNodes" SG_ 2158149632 HVBatCrgDspStat 1;
BA_ "GenSigSendType" SG_ 2158116864 SrvcHghVltBatIndReq 10;
BA_ "GenSigSendOnInit" SG_ 2158116864 SrvcHghVltBatIndReq 1;
BA_ "SignalType" SG_ 2158116864 SrvcHghVltBatIndReq "ENM";
BA_ "SignalLongName" SG_ 2158116864 SrvcHghVltBatIndReq "Service High Voltage Battery Indication Request";
BA_ "VNSigAllNodes" SG_ 2158116864 SrvcHghVltBatIndReq 1;
BA_ "GenSigSendType" SG_ 2158116864 ChrgStPkInScnActIO 10;
BA_ "GenSigSendOnInit" SG_ 2158116864 ChrgStPkInScnActIO 1;
BA_ "SignalType" SG_ 2158116864 ChrgStPkInScnActIO "BLN";
BA_ "SignalLongName" SG_ 2158116864 ChrgStPkInScnActIO "Charge Status Peek In Screen Active Indication On";
BA_ "VNSigAllNodes" SG_ 2158116864 ChrgStPkInScnActIO 1;
BA_ "GenSigSendType" SG_ 2158116864 HVBatStrtTmDspFrmt 10;
BA_ "GenSigSendOnInit" SG_ 2158116864 HVBatStrtTmDspFrmt 1;
BA_ "VNSigInfotainment" SG_ 2158116864 HVBatStrtTmDspFrmt 1;
BA_ "SignalType" SG_ 2158116864 HVBatStrtTmDspFrmt "ENM";
BA_ "SignalLongName" SG_ 2158116864 HVBatStrtTmDspFrmt "High Voltage Battery Start Time Display Format";
BA_ "VNSigAllNodes" SG_ 2158116864 HVBatStrtTmDspFrmt 1;
BA_ "GenSigDeltaValue" SG_ 2158116864 OBHVBCMinsRmng 1;
BA_ "GenSigSendType" SG_ 2158116864 OBHVBCMinsRmng 12;
BA_ "GenSigSendOnInit" SG_ 2158116864 OBHVBCMinsRmng 1;
BA_ "VNSigInfotainment" SG_ 2158116864 OBHVBCMinsRmng 1;
BA_ "SignalType" SG_ 2158116864 OBHVBCMinsRmng "UNM";
BA_ "SignalLongName" SG_ 2158116864 OBHVBCMinsRmng "Off Board High Voltage Bulk Charging Minutes Remaining";
BA_ "VNSigAllNodes" SG_ 2158116864 OBHVBCMinsRmng 1;
BA_ "GenSigSendType" SG_ 2158116864 OBHVBCCompTmDispFrmt 10;
BA_ "GenSigSendOnInit" SG_ 2158116864 OBHVBCCompTmDispFrmt 1;
BA_ "VNSigInfotainment" SG_ 2158116864 OBHVBCCompTmDispFrmt 1;
BA_ "SignalType" SG_ 2158116864 OBHVBCCompTmDispFrmt "ENM";
BA_ "SignalLongName" SG_ 2158116864 OBHVBCCompTmDispFrmt "Off Board High Voltage Bulk Charging Completion Time Display Format";
BA_ "VNSigAllNodes" SG_ 2158116864 OBHVBCCompTmDispFrmt 1;
BA_ "GenSigDeltaValue" SG_ 2158116864 HVBTBRCR_RtCHSlctTblRwStat 1;
BA_ "GenSigSendType" SG_ 2158116864 HVBTBRCR_RtCHSlctTblRwStat 12;
BA_ "GenSigSendOnInit" SG_ 2158116864 HVBTBRCR_RtCHSlctTblRwStat 1;
BA_ "VNSigInfotainment" SG_ 2158116864 HVBTBRCR_RtCHSlctTblRwStat 1;
BA_ "SignalType" SG_ 2158116864 HVBTBRCR_RtCHSlctTblRwStat "UNM";
BA_ "PacketOrder" SG_ 2158116864 HVBTBRCR_RtCHSlctTblRwStat 7;
BA_ "SignalLongName" SG_ 2158116864 HVBTBRCR_RtCHSlctTblRwStat "High Voltage Battery Time Based Rate Charging Response : Rate Charging Selected Table Row Status";
BA_ "VNSigAllNodes" SG_ 2158116864 HVBTBRCR_RtCHSlctTblRwStat 1;
BA_ "GenSigSendType" SG_ 2158116864 HVBTBRCR_RtChSlctStat 10;
BA_ "GenSigSendOnInit" SG_ 2158116864 HVBTBRCR_RtChSlctStat 1;
BA_ "VNSigInfotainment" SG_ 2158116864 HVBTBRCR_RtChSlctStat 1;
BA_ "SignalType" SG_ 2158116864 HVBTBRCR_RtChSlctStat "ENM";
BA_ "PacketOrder" SG_ 2158116864 HVBTBRCR_RtChSlctStat 3;
BA_ "SignalLongName" SG_ 2158116864 HVBTBRCR_RtChSlctStat "High Voltage Battery Time Based Rate Charging Response : Rate Charging Selected Status";
BA_ "VNSigAllNodes" SG_ 2158116864 HVBTBRCR_RtChSlctStat 1;
BA_ "GenSigSendType" SG_ 2158116864 HVBTBRCR_RtChSlRtStat 10;
BA_ "GenSigSendOnInit" SG_ 2158116864 HVBTBRCR_RtChSlRtStat 1;
BA_ "VNSigInfotainment" SG_ 2158116864 HVBTBRCR_RtChSlRtStat 1;
BA_ "SignalType" SG_ 2158116864 HVBTBRCR_RtChSlRtStat "ENM";
BA_ "PacketOrder" SG_ 2158116864 HVBTBRCR_RtChSlRtStat 6;
BA_ "SignalLongName" SG_ 2158116864 HVBTBRCR_RtChSlRtStat "High Voltage Battery Time Based Rate Charging Response : Rate Charging Selected Rate Status";
BA_ "VNSigAllNodes" SG_ 2158116864 HVBTBRCR_RtChSlRtStat 1;
BA_ "GenSigSendType" SG_ 2158116864 HVBTBRCR_RtChSsnStat 10;
BA_ "GenSigSendOnInit" SG_ 2158116864 HVBTBRCR_RtChSsnStat 1;
BA_ "VNSigInfotainment" SG_ 2158116864 HVBTBRCR_RtChSsnStat 1;
BA_ "SignalType" SG_ 2158116864 HVBTBRCR_RtChSsnStat "ENM";
BA_ "PacketOrder" SG_ 2158116864 HVBTBRCR_RtChSsnStat 1;
BA_ "SignalLongName" SG_ 2158116864 HVBTBRCR_RtChSsnStat "High Voltage Battery Time Based Rate Charging Response : Rate Charging Season Status";
BA_ "VNSigAllNodes" SG_ 2158116864 HVBTBRCR_RtChSsnStat 1;
BA_ "GenSigDeltaValue" SG_ 2158116864 HVBTBRCR_RtChMHRsp 1;
BA_ "GenSigSendType" SG_ 2158116864 HVBTBRCR_RtChMHRsp 12;
BA_ "GenSigSendOnInit" SG_ 2158116864 HVBTBRCR_RtChMHRsp 1;
BA_ "VNSigInfotainment" SG_ 2158116864 HVBTBRCR_RtChMHRsp 1;
BA_ "SignalType" SG_ 2158116864 HVBTBRCR_RtChMHRsp "UNM";
BA_ "PacketOrder" SG_ 2158116864 HVBTBRCR_RtChMHRsp 2;
BA_ "SignalLongName" SG_ 2158116864 HVBTBRCR_RtChMHRsp "High Voltage Battery Time Based Rate Charging Response : Rate Charging Minute of Hour Response";
BA_ "VNSigAllNodes" SG_ 2158116864 HVBTBRCR_RtChMHRsp 1;
BA_ "GenSigDeltaValue" SG_ 2158116864 HVBTBRCR_RtChHRsp 1;
BA_ "GenSigSendType" SG_ 2158116864 HVBTBRCR_RtChHRsp 12;
BA_ "GenSigSendOnInit" SG_ 2158116864 HVBTBRCR_RtChHRsp 1;
BA_ "VNSigInfotainment" SG_ 2158116864 HVBTBRCR_RtChHRsp 1;
BA_ "SignalType" SG_ 2158116864 HVBTBRCR_RtChHRsp "UNM";
BA_ "PacketOrder" SG_ 2158116864 HVBTBRCR_RtChHRsp 4;
BA_ "SignalLongName" SG_ 2158116864 HVBTBRCR_RtChHRsp "High Voltage Battery Time Based Rate Charging Response : Rate Charging Hour Response";
BA_ "VNSigAllNodes" SG_ 2158116864 HVBTBRCR_RtChHRsp 1;
BA_ "GenSigSendType" SG_ 2158116864 HVBTBRCR_RtChDStat 10;
BA_ "GenSigSendOnInit" SG_ 2158116864 HVBTBRCR_RtChDStat 1;
BA_ "VNSigInfotainment" SG_ 2158116864 HVBTBRCR_RtChDStat 1;
BA_ "SignalType" SG_ 2158116864 HVBTBRCR_RtChDStat "ENM";
BA_ "PacketOrder" SG_ 2158116864 HVBTBRCR_RtChDStat 5;
BA_ "SignalLongName" SG_ 2158116864 HVBTBRCR_RtChDStat "High Voltage Battery Time Based Rate Charging Response : Rate Charging Day Status";
BA_ "VNSigAllNodes" SG_ 2158116864 HVBTBRCR_RtChDStat 1;
BA_ "GenSigSendType" SG_ 2158116864 HVBTBDCRS_DlChSlctStat 10;
BA_ "GenSigSendOnInit" SG_ 2158116864 HVBTBDCRS_DlChSlctStat 1;
BA_ "VNSigInfotainment" SG_ 2158116864 HVBTBDCRS_DlChSlctStat 1;
BA_ "SignalType" SG_ 2158116864 HVBTBDCRS_DlChSlctStat "ENM";
BA_ "PacketOrder" SG_ 2158116864 HVBTBDCRS_DlChSlctStat 3;
BA_ "SignalLongName" SG_ 2158116864 HVBTBDCRS_DlChSlctStat "High Voltage Battery Time Based Delayed Charging Response : Delayed Charging Selected Status";
BA_ "VNSigAllNodes" SG_ 2158116864 HVBTBDCRS_DlChSlctStat 1;
BA_ "GenSigSendType" SG_ 2158116864 HVBTBDCRS_DlChSsnStat 10;
BA_ "GenSigSendOnInit" SG_ 2158116864 HVBTBDCRS_DlChSsnStat 1;
BA_ "VNSigInfotainment" SG_ 2158116864 HVBTBDCRS_DlChSsnStat 1;
BA_ "SignalType" SG_ 2158116864 HVBTBDCRS_DlChSsnStat "ENM";
BA_ "PacketOrder" SG_ 2158116864 HVBTBDCRS_DlChSsnStat 4;
BA_ "SignalLongName" SG_ 2158116864 HVBTBDCRS_DlChSsnStat "High Voltage Battery Time Based Delayed Charging Response : Delayed Charging Season Status";
BA_ "VNSigAllNodes" SG_ 2158116864 HVBTBDCRS_DlChSsnStat 1;
BA_ "GenSigDeltaValue" SG_ 2158116864 HVBTBDCRS_DlChMHRsp 1;
BA_ "GenSigSendType" SG_ 2158116864 HVBTBDCRS_DlChMHRsp 12;
BA_ "GenSigSendOnInit" SG_ 2158116864 HVBTBDCRS_DlChMHRsp 1;
BA_ "VNSigInfotainment" SG_ 2158116864 HVBTBDCRS_DlChMHRsp 1;
BA_ "SignalType" SG_ 2158116864 HVBTBDCRS_DlChMHRsp "UNM";
BA_ "PacketOrder" SG_ 2158116864 HVBTBDCRS_DlChMHRsp 5;
BA_ "SignalLongName" SG_ 2158116864 HVBTBDCRS_DlChMHRsp "High Voltage Battery Time Based Delayed Charging Response : Delayed Charging Minute of Hour Response";
BA_ "VNSigAllNodes" SG_ 2158116864 HVBTBDCRS_DlChMHRsp 1;
BA_ "GenSigDeltaValue" SG_ 2158116864 HVBTBDCRS_DlChHRsp 1;
BA_ "GenSigSendType" SG_ 2158116864 HVBTBDCRS_DlChHRsp 12;
BA_ "GenSigSendOnInit" SG_ 2158116864 HVBTBDCRS_DlChHRsp 1;
BA_ "VNSigInfotainment" SG_ 2158116864 HVBTBDCRS_DlChHRsp 1;
BA_ "SignalType" SG_ 2158116864 HVBTBDCRS_DlChHRsp "UNM";
BA_ "PacketOrder" SG_ 2158116864 HVBTBDCRS_DlChHRsp 1;
BA_ "SignalLongName" SG_ 2158116864 HVBTBDCRS_DlChHRsp "High Voltage Battery Time Based Delayed Charging Response : Delayed Charging Hour Response";
BA_ "VNSigAllNodes" SG_ 2158116864 HVBTBDCRS_DlChHRsp 1;
BA_ "GenSigSendType" SG_ 2158116864 HVBTBDCRS_DlChDStat 10;
BA_ "GenSigSendOnInit" SG_ 2158116864 HVBTBDCRS_DlChDStat 1;
BA_ "VNSigInfotainment" SG_ 2158116864 HVBTBDCRS_DlChDStat 1;
BA_ "SignalType" SG_ 2158116864 HVBTBDCRS_DlChDStat "ENM";
BA_ "PacketOrder" SG_ 2158116864 HVBTBDCRS_DlChDStat 2;
BA_ "SignalLongName" SG_ 2158116864 HVBTBDCRS_DlChDStat "High Voltage Battery Time Based Delayed Charging Response : Delayed Charging Day Status";
BA_ "VNSigAllNodes" SG_ 2158116864 HVBTBDCRS_DlChDStat 1;
BA_ "GenSigSendType" SG_ 2156281856 LftmEffDtRstRqd 10;
BA_ "GenSigSendOnInit" SG_ 2156281856 LftmEffDtRstRqd 1;
BA_ "VNSigInfotainment" SG_ 2156281856 LftmEffDtRstRqd 1;
BA_ "SignalType" SG_ 2156281856 LftmEffDtRstRqd "BLN";
BA_ "SignalLongName" SG_ 2156281856 LftmEffDtRstRqd "Lifetime Efficiency Data Reset Requested";
BA_ "VNSigAllNodes" SG_ 2156281856 LftmEffDtRstRqd 1;
BA_ "GenSigSendType" SG_ 2156281856 HTRCsStReq 10;
BA_ "VNSigInfotainment" SG_ 2156281856 HTRCsStReq 1;
BA_ "SignalType" SG_ 2156281856 HTRCsStReq "ENM";
BA_ "SignalLongName" SG_ 2156281856 HTRCsStReq "Hill Top Reserve Customization Setting Request";
BA_ "VNSigAllNodes" SG_ 2156281856 HTRCsStReq 1;
BA_ "GenSigSendType" SG_ 2156281856 TODCTmpImdtOvrdReq 10;
BA_ "VNSigInfotainment" SG_ 2156281856 TODCTmpImdtOvrdReq 1;
BA_ "SignalType" SG_ 2156281856 TODCTmpImdtOvrdReq "ENM";
BA_ "SignalLongName" SG_ 2156281856 TODCTmpImdtOvrdReq "Time Of Day Charge Temporary Immediate Override Request";
BA_ "VNSigAllNodes" SG_ 2156281856 TODCTmpImdtOvrdReq 1;
BA_ "GenSigSendType" SG_ 2156281856 RtBsChrgCmplnTmPrfReq 10;
BA_ "VNSigInfotainment" SG_ 2156281856 RtBsChrgCmplnTmPrfReq 1;
BA_ "SignalType" SG_ 2156281856 RtBsChrgCmplnTmPrfReq "ENM";
BA_ "SignalLongName" SG_ 2156281856 RtBsChrgCmplnTmPrfReq "Rate Based Charge Completion Time Preference Request";
BA_ "VNSigAllNodes" SG_ 2156281856 RtBsChrgCmplnTmPrfReq 1;
BA_ "GenSigSendType" SG_ 2156281856 TONPDTR_StTmpOvrAtv 10;
BA_ "VNSigInfotainment" SG_ 2156281856 TONPDTR_StTmpOvrAtv 1;
BA_ "SignalType" SG_ 2156281856 TONPDTR_StTmpOvrAtv "ENM";
BA_ "PacketOrder" SG_ 2156281856 TONPDTR_StTmpOvrAtv 1;
BA_ "SignalLongName" SG_ 2156281856 TONPDTR_StTmpOvrAtv "Temporary Override Next Planned Departure Time Requested : Set Temporary Override Next Planned Departure Time Active";
BA_ "VNSigAllNodes" SG_ 2156281856 TONPDTR_StTmpOvrAtv 1;
BA_ "GenSigDeltaValue" SG_ 2156281856 TONPDTR_MntOfHr 1;
BA_ "GenSigSendType" SG_ 2156281856 TONPDTR_MntOfHr 12;
BA_ "VNSigInfotainment" SG_ 2156281856 TONPDTR_MntOfHr 1;
BA_ "SignalType" SG_ 2156281856 TONPDTR_MntOfHr "UNM";
BA_ "PacketOrder" SG_ 2156281856 TONPDTR_MntOfHr 4;
BA_ "SignalLongName" SG_ 2156281856 TONPDTR_MntOfHr "Temporary Override Next Planned Departure Time Requested : Minute of Hour";
BA_ "VNSigAllNodes" SG_ 2156281856 TONPDTR_MntOfHr 1;
BA_ "GenSigDeltaValue" SG_ 2156281856 TONPDTR_HrOfDy 1;
BA_ "GenSigSendType" SG_ 2156281856 TONPDTR_HrOfDy 12;
BA_ "VNSigInfotainment" SG_ 2156281856 TONPDTR_HrOfDy 1;
BA_ "SignalType" SG_ 2156281856 TONPDTR_HrOfDy "UNM";
BA_ "PacketOrder" SG_ 2156281856 TONPDTR_HrOfDy 3;
BA_ "SignalLongName" SG_ 2156281856 TONPDTR_HrOfDy "Temporary Override Next Planned Departure Time Requested : Hour of Day";
BA_ "VNSigAllNodes" SG_ 2156281856 TONPDTR_HrOfDy 1;
BA_ "GenSigSendType" SG_ 2156281856 TONPDTR_DyOfWk 10;
BA_ "VNSigInfotainment" SG_ 2156281856 TONPDTR_DyOfWk 1;
BA_ "SignalType" SG_ 2156281856 TONPDTR_DyOfWk "ENM";
BA_ "PacketOrder" SG_ 2156281856 TONPDTR_DyOfWk 2;
BA_ "SignalLongName" SG_ 2156281856 TONPDTR_DyOfWk "Temporary Override Next Planned Departure Time Requested : Day of Week";
BA_ "VNSigAllNodes" SG_ 2156281856 TONPDTR_DyOfWk 1;
BA_ "GenSigSendType" SG_ 2156281856 StTODChrgTmpOvrd 10;
BA_ "VNSigInfotainment" SG_ 2156281856 StTODChrgTmpOvrd 1;
BA_ "SignalType" SG_ 2156281856 StTODChrgTmpOvrd "BLN";
BA_ "SignalLongName" SG_ 2156281856 StTODChrgTmpOvrd "Set Time of Day Charge Temporary Override";
BA_ "VNSigAllNodes" SG_ 2156281856 StTODChrgTmpOvrd 1;
BA_ "GenSigSendType" SG_ 2156281856 HVBTBSCSR_SsnStReq 10;
BA_ "VNSigInfotainment" SG_ 2156281856 HVBTBSCSR_SsnStReq 1;
BA_ "SignalType" SG_ 2156281856 HVBTBSCSR_SsnStReq "ENM";
BA_ "PacketOrder" SG_ 2156281856 HVBTBSCSR_SsnStReq 1;
BA_ "SignalLongName" SG_ 2156281856 HVBTBSCSR_SsnStReq "High Voltage Battery Time Based Season Charging Set Request : Season Set Request";
BA_ "VNSigAllNodes" SG_ 2156281856 HVBTBSCSR_SsnStReq 1;
BA_ "GenSigSendType" SG_ 2156281856 HVBTBSCSR_SsnSlStReq 10;
BA_ "VNSigInfotainment" SG_ 2156281856 HVBTBSCSR_SsnSlStReq 1;
BA_ "SignalType" SG_ 2156281856 HVBTBSCSR_SsnSlStReq "ENM";
BA_ "PacketOrder" SG_ 2156281856 HVBTBSCSR_SsnSlStReq 2;
BA_ "SignalLongName" SG_ 2156281856 HVBTBSCSR_SsnSlStReq "High Voltage Battery Time Based Season Charging Set Request : Season Selected Set Requset";
BA_ "VNSigAllNodes" SG_ 2156281856 HVBTBSCSR_SsnSlStReq 1;
BA_ "GenSigSendType" SG_ 2156281856 HVBTBSCSR_SsnMthStReq 10;
BA_ "VNSigInfotainment" SG_ 2156281856 HVBTBSCSR_SsnMthStReq 1;
BA_ "SignalType" SG_ 2156281856 HVBTBSCSR_SsnMthStReq "ENM";
BA_ "PacketOrder" SG_ 2156281856 HVBTBSCSR_SsnMthStReq 3;
BA_ "SignalLongName" SG_ 2156281856 HVBTBSCSR_SsnMthStReq "High Voltage Battery Time Based Season Charging Set Request : Season Month Set Request";
BA_ "VNSigAllNodes" SG_ 2156281856 HVBTBSCSR_SsnMthStReq 1;
BA_ "GenSigDeltaValue" SG_ 2156281856 HVBTBSCSR_SsnDayStReq 1;
BA_ "GenSigSendType" SG_ 2156281856 HVBTBSCSR_SsnDayStReq 12;
BA_ "VNSigInfotainment" SG_ 2156281856 HVBTBSCSR_SsnDayStReq 1;
BA_ "SignalType" SG_ 2156281856 HVBTBSCSR_SsnDayStReq "UNM";
BA_ "PacketOrder" SG_ 2156281856 HVBTBSCSR_SsnDayStReq 4;
BA_ "SignalLongName" SG_ 2156281856 HVBTBSCSR_SsnDayStReq "High Voltage Battery Time Based Season Charging Set Request : Season Day Set Request";
BA_ "VNSigAllNodes" SG_ 2156281856 HVBTBSCSR_SsnDayStReq 1;
BA_ "GenSigSendType" SG_ 2156281856 HVBTBCRSR_ChRtSlStReq 10;
BA_ "VNSigInfotainment" SG_ 2156281856 HVBTBCRSR_ChRtSlStReq 1;
BA_ "SignalType" SG_ 2156281856 HVBTBCRSR_ChRtSlStReq "ENM";
BA_ "PacketOrder" SG_ 2156281856 HVBTBCRSR_ChRtSlStReq 3;
BA_ "SignalLongName" SG_ 2156281856 HVBTBCRSR_ChRtSlStReq "High Voltage Battery Time Based Charge Rate Set Request : Charge Rate Selected Set Request";
BA_ "VNSigAllNodes" SG_ 2156281856 HVBTBCRSR_ChRtSlStReq 1;
BA_ "GenSigSendType" SG_ 2156281856 HVBTBCRSR_ChRtEnblStReq 10;
BA_ "VNSigInfotainment" SG_ 2156281856 HVBTBCRSR_ChRtEnblStReq 1;
BA_ "SignalType" SG_ 2156281856 HVBTBCRSR_ChRtEnblStReq "ENM";
BA_ "PacketOrder" SG_ 2156281856 HVBTBCRSR_ChRtEnblStReq 1;
BA_ "SignalLongName" SG_ 2156281856 HVBTBCRSR_ChRtEnblStReq "High Voltage Battery Time Based Charge Rate Set Request : Charge Rate Enable Set Request";
BA_ "VNSigAllNodes" SG_ 2156281856 HVBTBCRSR_ChRtEnblStReq 1;
BA_ "GenSigSendType" SG_ 2156281856 HVBTBCRSR_ChRtDStReq 10;
BA_ "VNSigInfotainment" SG_ 2156281856 HVBTBCRSR_ChRtDStReq 1;
BA_ "SignalType" SG_ 2156281856 HVBTBCRSR_ChRtDStReq "ENM";
BA_ "PacketOrder" SG_ 2156281856 HVBTBCRSR_ChRtDStReq 2;
BA_ "SignalLongName" SG_ 2156281856 HVBTBCRSR_ChRtDStReq "High Voltage Battery Time Based Charge Rate Set Request : Charge Rate Day Set Request";
BA_ "VNSigAllNodes" SG_ 2156281856 HVBTBCRSR_ChRtDStReq 1;
BA_ "GenSigSendType" SG_ 2156281856 HVBatTmBsChrgMdReq 10;
BA_ "VNSigInfotainment" SG_ 2156281856 HVBatTmBsChrgMdReq 1;
BA_ "SignalType" SG_ 2156281856 HVBatTmBsChrgMdReq "ENM";
BA_ "SignalLongName" SG_ 2156281856 HVBatTmBsChrgMdReq "High Voltage Battery Time Based Charging Mode Request";
BA_ "VNSigAllNodes" SG_ 2156281856 HVBatTmBsChrgMdReq 1;
BA_ "GenSigSendType" SG_ 2156281856 HVChgSyChgLvlPrfSt 10;
BA_ "VNSigInfotainment" SG_ 2156281856 HVChgSyChgLvlPrfSt 1;
BA_ "SignalType" SG_ 2156281856 HVChgSyChgLvlPrfSt "ENM";
BA_ "SignalLongName" SG_ 2156281856 HVChgSyChgLvlPrfSt "High Voltage Charging System Charge Level Preference Setting";
BA_ "VNSigAllNodes" SG_ 2156281856 HVChgSyChgLvlPrfSt 1;
BA_ "GenSigSendType" SG_ 2156265472 EngyUsgScrnMeasUtStat 10;
BA_ "GenSigSendOnInit" SG_ 2156265472 EngyUsgScrnMeasUtStat 1;
BA_ "VNSigInfotainment" SG_ 2156265472 EngyUsgScrnMeasUtStat 1;
BA_ "SignalType" SG_ 2156265472 EngyUsgScrnMeasUtStat "ENM";
BA_ "SignalLongName" SG_ 2156265472 EngyUsgScrnMeasUtStat "Energy Usage Screen Measurement Unit Status";
BA_ "VNSigAllNodes" SG_ 2156265472 EngyUsgScrnMeasUtStat 1;
BA_ "GenSigSendType" SG_ 2156265472 OffBrdHVCVehCsChRq 10;
BA_ "VNSigInfotainment" SG_ 2156265472 OffBrdHVCVehCsChRq 1;
BA_ "SignalType" SG_ 2156265472 OffBrdHVCVehCsChRq "BLN";
BA_ "SignalLongName" SG_ 2156265472 OffBrdHVCVehCsChRq "Off Board High Voltage Charging Vehicle Cease Charging Requested";
BA_ "VNSigAllNodes" SG_ 2156265472 OffBrdHVCVehCsChRq 1;
BA_ "GenSigSendType" SG_ 2156265472 PrtyChrgRq 10;
BA_ "VNSigInfotainment" SG_ 2156265472 PrtyChrgRq 1;
BA_ "SignalType" SG_ 2156265472 PrtyChrgRq "ENM";
BA_ "SignalLongName" SG_ 2156265472 PrtyChrgRq "Priority Charging Request";
BA_ "VNSigAllNodes" SG_ 2156265472 PrtyChrgRq 1;
BA_ "GenSigSendType" SG_ 2156265472 HVBTBRCSR_RtChSlStReq 10;
BA_ "VNSigInfotainment" SG_ 2156265472 HVBTBRCSR_RtChSlStReq 1;
BA_ "SignalType" SG_ 2156265472 HVBTBRCSR_RtChSlStReq "ENM";
BA_ "PacketOrder" SG_ 2156265472 HVBTBRCSR_RtChSlStReq 3;
BA_ "SignalLongName" SG_ 2156265472 HVBTBRCSR_RtChSlStReq "High Voltage Battery Time Based Rate Charging Set Request : Rate Charging Selected Set Request";
BA_ "VNSigAllNodes" SG_ 2156265472 HVBTBRCSR_RtChSlStReq 1;
BA_ "GenSigSendType" SG_ 2156265472 HVBTBRCSR_RtChSlRtStReq 10;
BA_ "VNSigInfotainment" SG_ 2156265472 HVBTBRCSR_RtChSlRtStReq 1;
BA_ "SignalType" SG_ 2156265472 HVBTBRCSR_RtChSlRtStReq "ENM";
BA_ "PacketOrder" SG_ 2156265472 HVBTBRCSR_RtChSlRtStReq 2;
BA_ "SignalLongName" SG_ 2156265472 HVBTBRCSR_RtChSlRtStReq "High Voltage Battery Time Based Rate Charging Set Request : Rate Charging Selected Rate Set Request";
BA_ "VNSigAllNodes" SG_ 2156265472 HVBTBRCSR_RtChSlRtStReq 1;
BA_ "GenSigSendType" SG_ 2156265472 HVBTBRCSR_RtChSsnStReq 10;
BA_ "VNSigInfotainment" SG_ 2156265472 HVBTBRCSR_RtChSsnStReq 1;
BA_ "SignalType" SG_ 2156265472 HVBTBRCSR_RtChSsnStReq "ENM";
BA_ "PacketOrder" SG_ 2156265472 HVBTBRCSR_RtChSsnStReq 5;
BA_ "SignalLongName" SG_ 2156265472 HVBTBRCSR_RtChSsnStReq "High Voltage Battery Time Based Rate Charging Set Request : Rate Charging Season Set Request";
BA_ "VNSigAllNodes" SG_ 2156265472 HVBTBRCSR_RtChSsnStReq 1;
BA_ "GenSigDeltaValue" SG_ 2156265472 HVBTBRCSR_RtChMHStReq 1;
BA_ "GenSigSendType" SG_ 2156265472 HVBTBRCSR_RtChMHStReq 12;
BA_ "VNSigInfotainment" SG_ 2156265472 HVBTBRCSR_RtChMHStReq 1;
BA_ "SignalType" SG_ 2156265472 HVBTBRCSR_RtChMHStReq "UNM";
BA_ "PacketOrder" SG_ 2156265472 HVBTBRCSR_RtChMHStReq 6;
BA_ "SignalLongName" SG_ 2156265472 HVBTBRCSR_RtChMHStReq "High Voltage Battery Time Based Rate Charging Set Request : Rate Charging Minute of Hour Set Request";
BA_ "VNSigAllNodes" SG_ 2156265472 HVBTBRCSR_RtChMHStReq 1;
BA_ "GenSigDeltaValue" SG_ 2156265472 HVBTBRCSR_RtChHStReq 1;
BA_ "GenSigSendType" SG_ 2156265472 HVBTBRCSR_RtChHStReq 12;
BA_ "VNSigInfotainment" SG_ 2156265472 HVBTBRCSR_RtChHStReq 1;
BA_ "SignalType" SG_ 2156265472 HVBTBRCSR_RtChHStReq "UNM";
BA_ "PacketOrder" SG_ 2156265472 HVBTBRCSR_RtChHStReq 4;
BA_ "SignalLongName" SG_ 2156265472 HVBTBRCSR_RtChHStReq "High Voltage Battery Time Based Rate Charging Set Request : Rate Charging Hour Set Request";
BA_ "VNSigAllNodes" SG_ 2156265472 HVBTBRCSR_RtChHStReq 1;
BA_ "GenSigSendType" SG_ 2156265472 HVBTBRCSR_RtChDStReq 10;
BA_ "VNSigInfotainment" SG_ 2156265472 HVBTBRCSR_RtChDStReq 1;
BA_ "SignalType" SG_ 2156265472 HVBTBRCSR_RtChDStReq "ENM";
BA_ "PacketOrder" SG_ 2156265472 HVBTBRCSR_RtChDStReq 1;
BA_ "SignalLongName" SG_ 2156265472 HVBTBRCSR_RtChDStReq "High Voltage Battery Time Based Rate Charging Set Request : Rate Charging Day Set Request";
BA_ "VNSigAllNodes" SG_ 2156265472 HVBTBRCSR_RtChDStReq 1;
BA_ "GenSigDeltaValue" SG_ 2156265472 HVBTBRCSR_RtChSlTbRwReq 1;
BA_ "GenSigSendType" SG_ 2156265472 HVBTBRCSR_RtChSlTbRwReq 12;
BA_ "VNSigInfotainment" SG_ 2156265472 HVBTBRCSR_RtChSlTbRwReq 1;
BA_ "SignalType" SG_ 2156265472 HVBTBRCSR_RtChSlTbRwReq "UNM";
BA_ "PacketOrder" SG_ 2156265472 HVBTBRCSR_RtChSlTbRwReq 7;
BA_ "SignalLongName" SG_ 2156265472 HVBTBRCSR_RtChSlTbRwReq "High Voltage Battery Time Based Rate Charging Set Request : Rate Charging Selected Table Row Set Request";
BA_ "VNSigAllNodes" SG_ 2156265472 HVBTBRCSR_RtChSlTbRwReq 1;
BA_ "GenSigSendType" SG_ 2156265472 HVBTBDCSRQ_DlChSlStReq 10;
BA_ "VNSigInfotainment" SG_ 2156265472 HVBTBDCSRQ_DlChSlStReq 1;
BA_ "SignalType" SG_ 2156265472 HVBTBDCSRQ_DlChSlStReq "ENM";
BA_ "PacketOrder" SG_ 2156265472 HVBTBDCSRQ_DlChSlStReq 3;
BA_ "SignalLongName" SG_ 2156265472 HVBTBDCSRQ_DlChSlStReq "High Voltage Battery Time Based Delayed Charging Set Request : Delayed Charging Selected Set Request";
BA_ "VNSigAllNodes" SG_ 2156265472 HVBTBDCSRQ_DlChSlStReq 1;
BA_ "GenSigSendType" SG_ 2156265472 HVBTBDCSRQ_DlChSsnStReq 10;
BA_ "VNSigInfotainment" SG_ 2156265472 HVBTBDCSRQ_DlChSsnStReq 1;
BA_ "SignalType" SG_ 2156265472 HVBTBDCSRQ_DlChSsnStReq "ENM";
BA_ "PacketOrder" SG_ 2156265472 HVBTBDCSRQ_DlChSsnStReq 4;
BA_ "SignalLongName" SG_ 2156265472 HVBTBDCSRQ_DlChSsnStReq "High Voltage Battery Time Based Delayed Charging Set Request : Delayed Charging Season Set Request";
BA_ "VNSigAllNodes" SG_ 2156265472 HVBTBDCSRQ_DlChSsnStReq 1;
BA_ "GenSigDeltaValue" SG_ 2156265472 HVBTBDCSRQ_DlChMHStReq 1;
BA_ "GenSigSendType" SG_ 2156265472 HVBTBDCSRQ_DlChMHStReq 12;
BA_ "VNSigInfotainment" SG_ 2156265472 HVBTBDCSRQ_DlChMHStReq 1;
BA_ "SignalType" SG_ 2156265472 HVBTBDCSRQ_DlChMHStReq "UNM";
BA_ "PacketOrder" SG_ 2156265472 HVBTBDCSRQ_DlChMHStReq 5;
BA_ "SignalLongName" SG_ 2156265472 HVBTBDCSRQ_DlChMHStReq "High Voltage Battery Time Based Delayed Charging Set Request : Delayed Charging Minute of Hour Set Request";
BA_ "VNSigAllNodes" SG_ 2156265472 HVBTBDCSRQ_DlChMHStReq 1;
BA_ "GenSigDeltaValue" SG_ 2156265472 HVBTBDCSRQ_DlChHStReq 1;
BA_ "GenSigSendType" SG_ 2156265472 HVBTBDCSRQ_DlChHStReq 12;
BA_ "VNSigInfotainment" SG_ 2156265472 HVBTBDCSRQ_DlChHStReq 1;
BA_ "SignalType" SG_ 2156265472 HVBTBDCSRQ_DlChHStReq "UNM";
BA_ "PacketOrder" SG_ 2156265472 HVBTBDCSRQ_DlChHStReq 1;
BA_ "SignalLongName" SG_ 2156265472 HVBTBDCSRQ_DlChHStReq "High Voltage Battery Time Based Delayed Charging Set Request : Delayed Charging Hour Set Request";
BA_ "VNSigAllNodes" SG_ 2156265472 HVBTBDCSRQ_DlChHStReq 1;
BA_ "GenSigSendType" SG_ 2156265472 HVBTBDCSRQ_DlChDStReq 10;
BA_ "VNSigInfotainment" SG_ 2156265472 HVBTBDCSRQ_DlChDStReq 1;
BA_ "SignalType" SG_ 2156265472 HVBTBDCSRQ_DlChDStReq "ENM";
BA_ "PacketOrder" SG_ 2156265472 HVBTBDCSRQ_DlChDStReq 2;
BA_ "SignalLongName" SG_ 2156265472 HVBTBDCSRQ_DlChDStReq "High Voltage Battery Time Based Delayed Charging Set Request : Delayed Charging Day Set Request";
BA_ "VNSigAllNodes" SG_ 2156265472 HVBTBDCSRQ_DlChDStReq 1;
BA_ "GenSigSendType" SG_ 2156265472 ChgPwLsAlCzStRq 10;
BA_ "VNSigInfotainment" SG_ 2156265472 ChgPwLsAlCzStRq 1;
BA_ "SignalType" SG_ 2156265472 ChgPwLsAlCzStRq "ENM";
BA_ "SignalLongName" SG_ 2156265472 ChgPwLsAlCzStRq "Charge Power Loss Alert Customization Setting Request";
BA_ "VNSigAllNodes" SG_ 2156265472 ChgPwLsAlCzStRq 1;
BA_ "GenSigSendType" SG_ 2156265472 ChgCdTfAlCzStRq 10;
BA_ "VNSigInfotainment" SG_ 2156265472 ChgCdTfAlCzStRq 1;
BA_ "SignalType" SG_ 2156265472 ChgCdTfAlCzStRq "ENM";
BA_ "SignalLongName" SG_ 2156265472 ChgCdTfAlCzStRq "Charge Cord Theft Alert Customization Setting Request";
BA_ "VNSigAllNodes" SG_ 2156265472 ChgCdTfAlCzStRq 1;
BA_ "GenSigSendType" SG_ 2156265472 ChgSysAudInCsStReq 10;
BA_ "VNSigInfotainment" SG_ 2156265472 ChgSysAudInCsStReq 1;
BA_ "SignalType" SG_ 2156265472 ChgSysAudInCsStReq "ENM";
BA_ "SignalLongName" SG_ 2156265472 ChgSysAudInCsStReq "Charger System Audible Indication Customization Setting Request";
BA_ "VNSigAllNodes" SG_ 2156265472 ChgSysAudInCsStReq 1;
BA_ "GenSigSendType" SG_ 2150113280 HVChrgInhbRsn 10;
BA_ "SignalType" SG_ 2150113280 HVChrgInhbRsn "ENM";
BA_ "SignalLongName" SG_ 2150113280 HVChrgInhbRsn "High Voltage Charging Inhibit Reason";
BA_ "VNSigAllNodes" SG_ 2150113280 HVChrgInhbRsn 1;
BA_ "GenSigDeltaValue" SG_ 2150113280 DrvCyclTrpDstTrvld 1;
BA_ "GenSigSendType" SG_ 2150113280 DrvCyclTrpDstTrvld 12;
BA_ "SignalType" SG_ 2150113280 DrvCyclTrpDstTrvld "UNM";
BA_ "SignalLongName" SG_ 2150113280 DrvCyclTrpDstTrvld "Drive Cycle Trip Distance Traveled";
BA_ "VNSigAllNodes" SG_ 2150113280 DrvCyclTrpDstTrvld 1;
BA_ "GenSigDeltaValue" SG_ 2150113280 DrvCyclElecEngyEcon 1;
BA_ "GenSigSendType" SG_ 2150113280 DrvCyclElecEngyEcon 12;
BA_ "SignalType" SG_ 2150113280 DrvCyclElecEngyEcon "UNM";
BA_ "SignalLongName" SG_ 2150113280 DrvCyclElecEngyEcon "Drive Cycle Electrical Energy Economy";
BA_ "VNSigAllNodes" SG_ 2150113280 DrvCyclElecEngyEcon 1;
BA_ "GenSigSendType" SG_ 2150113280 EngyStgSysActCoolEnb 10;
BA_ "GenSigSendOnInit" SG_ 2150113280 EngyStgSysActCoolEnb 1;
BA_ "VNSigInfotainment" SG_ 2150113280 EngyStgSysActCoolEnb 1;
BA_ "SignalType" SG_ 2150113280 EngyStgSysActCoolEnb "BLN";
BA_ "SignalLongName" SG_ 2150113280 EngyStgSysActCoolEnb "Energy Storage System Active Cooling Enabled";
BA_ "VNSigAllNodes" SG_ 2150113280 EngyStgSysActCoolEnb 1;
BA_ "GenSigDeltaValue" SG_ 2150113280 DrvCycElEnrgUsd 1;
BA_ "GenSigSendType" SG_ 2150113280 DrvCycElEnrgUsd 12;
BA_ "GenSigSendOnInit" SG_ 2150113280 DrvCycElEnrgUsd 1;
BA_ "VNSigInfotainment" SG_ 2150113280 DrvCycElEnrgUsd 1;
BA_ "SignalType" SG_ 2150113280 DrvCycElEnrgUsd "UNM";
BA_ "SignalLongName" SG_ 2150113280 DrvCycElEnrgUsd "Drive Cycle Electrical Energy Used";
BA_ "VNSigAllNodes" SG_ 2150113280 DrvCycElEnrgUsd 1;
BA_ "GenSigDeltaValue" SG_ 2150055936 ClmCntCmpPwrUsdClc 1;
BA_ "GenSigSendType" SG_ 2150055936 ClmCntCmpPwrUsdClc 12;
BA_ "SignalType" SG_ 2150055936 ClmCntCmpPwrUsdClc "UNM";
BA_ "SignalLongName" SG_ 2150055936 ClmCntCmpPwrUsdClc "Climate Control Compressor Power Used Calculated";
BA_ "VNSigAllNodes" SG_ 2150055936 ClmCntCmpPwrUsdClc 1;
BA_ "GenSigDeltaValue" SG_ 2150055936 ClimCtrlHVDvcShtdwnCmd 1;
BA_ "GenSigSendType" SG_ 2150055936 ClimCtrlHVDvcShtdwnCmd 10;
BA_ "GenSigSendOnInit" SG_ 2150055936 ClimCtrlHVDvcShtdwnCmd 1;
BA_ "SignalType" SG_ 2150055936 ClimCtrlHVDvcShtdwnCmd "BLN";
BA_ "SignalLongName" SG_ 2150055936 ClimCtrlHVDvcShtdwnCmd "Climate Control High Voltage Device Shutdown Commanded";
BA_ "VNSigAllNodes" SG_ 2150055936 ClimCtrlHVDvcShtdwnCmd 1;
BA_ "GenSigDeltaValue" SG_ 2150055936 ClmtCtrlLwrPwrLmt 1;
BA_ "GenSigSendType" SG_ 2150055936 ClmtCtrlLwrPwrLmt 12;
BA_ "GenSigSendOnInit" SG_ 2150055936 ClmtCtrlLwrPwrLmt 1;
BA_ "SignalType" SG_ 2150055936 ClmtCtrlLwrPwrLmt "UNM";
BA_ "SignalLongName" SG_ 2150055936 ClmtCtrlLwrPwrLmt "Climate Control Lower Power Limit";
BA_ "VNSigAllNodes" SG_ 2150055936 ClmtCtrlLwrPwrLmt 1;
BA_ "GenSigDeltaValue" SG_ 2150055936 ClmtCtrlUpprPwrLmt 1;
BA_ "GenSigSendType" SG_ 2150055936 ClmtCtrlUpprPwrLmt 12;
BA_ "GenSigSendOnInit" SG_ 2150055936 ClmtCtrlUpprPwrLmt 1;
BA_ "SignalType" SG_ 2150055936 ClmtCtrlUpprPwrLmt "UNM";
BA_ "SignalLongName" SG_ 2150055936 ClmtCtrlUpprPwrLmt "Climate Control Upper Power Limit";
BA_ "VNSigAllNodes" SG_ 2150055936 ClmtCtrlUpprPwrLmt 1;
BA_ "GenSigSendType" SG_ 2150039552 EvpCorOtltAirTmpCalcdV 10;
BA_ "SignalType" SG_ 2150039552 EvpCorOtltAirTmpCalcdV "ENM";
BA_ "SignalLongName" SG_ 2150039552 EvpCorOtltAirTmpCalcdV "Evaporator Core Outlet Air Temperature Calculated Validity";
BA_ "VNSigAllNodes" SG_ 2150039552 EvpCorOtltAirTmpCalcdV 1;
BA_ "GenSigSendType" SG_ 2150039552 ThrmlRefCompStat 10;
BA_ "GenSigSendOnInit" SG_ 2150039552 ThrmlRefCompStat 1;
BA_ "SignalType" SG_ 2150039552 ThrmlRefCompStat "ENM";
BA_ "SignalLongName" SG_ 2150039552 ThrmlRefCompStat "Thermal Refrigerant Compressor Status";
BA_ "VNSigAllNodes" SG_ 2150039552 ThrmlRefCompStat 1;
BA_ "GenSigSendType" SG_ 2150039552 ThrmlRefCompSpdV 10;
BA_ "GenSigSendOnInit" SG_ 2150039552 ThrmlRefCompSpdV 1;
BA_ "SignalType" SG_ 2150039552 ThrmlRefCompSpdV "ENM";
BA_ "SignalLongName" SG_ 2150039552 ThrmlRefCompSpdV "Thermal Refrigerant Compressor Speed Validity";
BA_ "VNSigAllNodes" SG_ 2150039552 ThrmlRefCompSpdV 1;
BA_ "GenSigDeltaValue" SG_ 2150039552 ThrmlRefCompSpd 1;
BA_ "GenSigSendType" SG_ 2150039552 ThrmlRefCompSpd 12;
BA_ "GenSigSendOnInit" SG_ 2150039552 ThrmlRefCompSpd 1;
BA_ "SignalType" SG_ 2150039552 ThrmlRefCompSpd "UNM";
BA_ "SignalLongName" SG_ 2150039552 ThrmlRefCompSpd "Thermal Refrigerant Compressor Speed";
BA_ "VNSigAllNodes" SG_ 2150039552 ThrmlRefCompSpd 1;
BA_ "GenSigSendType" SG_ 2150039552 ThrmlRfCmpOvTmpFltPr 10;
BA_ "GenSigSendOnInit" SG_ 2150039552 ThrmlRfCmpOvTmpFltPr 1;
BA_ "SignalType" SG_ 2150039552 ThrmlRfCmpOvTmpFltPr "BLN";
BA_ "SignalLongName" SG_ 2150039552 ThrmlRfCmpOvTmpFltPr "Thermal Refrigerant Compressor Over Temperature Fault Present";
BA_ "VNSigAllNodes" SG_ 2150039552 ThrmlRfCmpOvTmpFltPr 1;
BA_ "GenSigDeltaValue" SG_ 2150039552 EvpCorOtltAirTmpCalcd 1;
BA_ "GenSigSendType" SG_ 2150039552 EvpCorOtltAirTmpCalcd 12;
BA_ "SignalType" SG_ 2150039552 EvpCorOtltAirTmpCalcd "UNM";
BA_ "SignalLongName" SG_ 2150039552 EvpCorOtltAirTmpCalcd "Evaporator Core Outlet Air Temperature Calculated";
BA_ "VNSigAllNodes" SG_ 2150039552 EvpCorOtltAirTmpCalcd 1;
BA_ "GenSigDeltaValue" SG_ 2154856448 HmdtySnsrTemp 1;
BA_ "GenSigSendType" SG_ 2154856448 HmdtySnsrTemp 12;
BA_ "SignalType" SG_ 2154856448 HmdtySnsrTemp "UNM";
BA_ "SignalLongName" SG_ 2154856448 HmdtySnsrTemp "Humidity Sensor Temperature";
BA_ "VNSigAllNodes" SG_ 2154856448 HmdtySnsrTemp 1;
BA_ "GenSigDeltaValue" SG_ 2154856448 HmdtySnsrRltvHmdty 1;
BA_ "GenSigSendType" SG_ 2154856448 HmdtySnsrRltvHmdty 12;
BA_ "SignalType" SG_ 2154856448 HmdtySnsrRltvHmdty "UNM";
BA_ "SignalLongName" SG_ 2154856448 HmdtySnsrRltvHmdty "Humidity Sensor Relative Humidity";
BA_ "VNSigAllNodes" SG_ 2154856448 HmdtySnsrRltvHmdty 1;
BA_ "GenSigDeltaValue" SG_ 2154856448 HmdtySnsrGlssTemp 1;
BA_ "GenSigSendType" SG_ 2154856448 HmdtySnsrGlssTemp 12;
BA_ "SignalType" SG_ 2154856448 HmdtySnsrGlssTemp "UNM";
BA_ "SignalLongName" SG_ 2154856448 HmdtySnsrGlssTemp "Humidity Sensor Glass Temperature";
BA_ "VNSigAllNodes" SG_ 2154856448 HmdtySnsrGlssTemp 1;
BA_ "GenSigSendType" SG_ 2151342080 PrkAstRtSysStat 10;
BA_ "SignalType" SG_ 2151342080 PrkAstRtSysStat "ENM";
BA_ "SignalLongName" SG_ 2151342080 PrkAstRtSysStat "Parking Assistance Right System Status";
BA_ "VNSigAllNodes" SG_ 2151342080 PrkAstRtSysStat 1;
BA_ "GenSigSendType" SG_ 2151342080 PARtRgn3ObjStat 10;
BA_ "SignalType" SG_ 2151342080 PARtRgn3ObjStat "ENM";
BA_ "SignalLongName" SG_ 2151342080 PARtRgn3ObjStat "Parking Assistance Right Region 3 Object Status";
BA_ "VNSigAllNodes" SG_ 2151342080 PARtRgn3ObjStat 1;
BA_ "GenSigSendType" SG_ 2151342080 PARtRgn2ObjStat 10;
BA_ "SignalType" SG_ 2151342080 PARtRgn2ObjStat "ENM";
BA_ "SignalLongName" SG_ 2151342080 PARtRgn2ObjStat "Parking Assistance Right Region 2 Object Status";
BA_ "VNSigAllNodes" SG_ 2151342080 PARtRgn2ObjStat 1;
BA_ "GenSigSendType" SG_ 2151342080 PARtRgn1ObjStat 10;
BA_ "SignalType" SG_ 2151342080 PARtRgn1ObjStat "ENM";
BA_ "SignalLongName" SG_ 2151342080 PARtRgn1ObjStat "Parking Assistance Right Region 1 Object Status";
BA_ "VNSigAllNodes" SG_ 2151342080 PARtRgn1ObjStat 1;
BA_ "GenSigSendType" SG_ 2151325696 PrkAstLtSysStat 10;
BA_ "SignalType" SG_ 2151325696 PrkAstLtSysStat "ENM";
BA_ "SignalLongName" SG_ 2151325696 PrkAstLtSysStat "Parking Assistance Left System Status";
BA_ "VNSigAllNodes" SG_ 2151325696 PrkAstLtSysStat 1;
BA_ "GenSigSendType" SG_ 2151325696 PALtRgn3ObjStat 10;
BA_ "SignalType" SG_ 2151325696 PALtRgn3ObjStat "ENM";
BA_ "SignalLongName" SG_ 2151325696 PALtRgn3ObjStat "Parking Assistance Left Region 3 Object Status";
BA_ "VNSigAllNodes" SG_ 2151325696 PALtRgn3ObjStat 1;
BA_ "GenSigSendType" SG_ 2151325696 PALtRgn2ObjStat 10;
BA_ "SignalType" SG_ 2151325696 PALtRgn2ObjStat "ENM";
BA_ "SignalLongName" SG_ 2151325696 PALtRgn2ObjStat "Parking Assistance Left Region 2 Object Status";
BA_ "VNSigAllNodes" SG_ 2151325696 PALtRgn2ObjStat 1;
BA_ "GenSigSendType" SG_ 2151325696 PALtRgn1ObjStat 10;
BA_ "SignalType" SG_ 2151325696 PALtRgn1ObjStat "ENM";
BA_ "SignalLongName" SG_ 2151325696 PALtRgn1ObjStat "Parking Assistance Left Region 1 Object Status";
BA_ "VNSigAllNodes" SG_ 2151325696 PALtRgn1ObjStat 1;
BA_ "GenSigDeltaValue" SG_ 2151809024 ElecEngyEconAvg 1;
BA_ "GenSigSendType" SG_ 2151809024 ElecEngyEconAvg 12;
BA_ "SignalType" SG_ 2151809024 ElecEngyEconAvg "UNM";
BA_ "SignalLongName" SG_ 2151809024 ElecEngyEconAvg "Electrical Energy Economy Average";
BA_ "VNSigAllNodes" SG_ 2151809024 ElecEngyEconAvg 1;
BA_ "GenSigDeltaValue" SG_ 2151809024 DrvCycElecEngySt5 1;
BA_ "GenSigSendType" SG_ 2151809024 DrvCycElecEngySt5 12;
BA_ "GenSigSendOnInit" SG_ 2151809024 DrvCycElecEngySt5 1;
BA_ "VNSigInfotainment" SG_ 2151809024 DrvCycElecEngySt5 1;
BA_ "SignalType" SG_ 2151809024 DrvCycElecEngySt5 "UNM";
BA_ "SignalLongName" SG_ 2151809024 DrvCycElecEngySt5 "Drive Cycle Electrical Energy State 5";
BA_ "VNSigAllNodes" SG_ 2151809024 DrvCycElecEngySt5 1;
BA_ "GenSigDeltaValue" SG_ 2151809024 DCEEC_EngyPct4 1;
BA_ "GenSigSendType" SG_ 2151809024 DCEEC_EngyPct4 12;
BA_ "GenSigSendOnInit" SG_ 2151809024 DCEEC_EngyPct4 1;
BA_ "VNSigInfotainment" SG_ 2151809024 DCEEC_EngyPct4 1;
BA_ "SignalType" SG_ 2151809024 DCEEC_EngyPct4 "UNM";
BA_ "PacketOrder" SG_ 2151809024 DCEEC_EngyPct4 4;
BA_ "SignalLongName" SG_ 2151809024 DCEEC_EngyPct4 "Drive Cycle Electrical Energy Consumed : Energy Percent 4";
BA_ "VNSigAllNodes" SG_ 2151809024 DCEEC_EngyPct4 1;
BA_ "GenSigDeltaValue" SG_ 2151809024 DCEEC_EngyPct3 1;
BA_ "GenSigSendType" SG_ 2151809024 DCEEC_EngyPct3 12;
BA_ "GenSigSendOnInit" SG_ 2151809024 DCEEC_EngyPct3 1;
BA_ "VNSigInfotainment" SG_ 2151809024 DCEEC_EngyPct3 1;
BA_ "SignalType" SG_ 2151809024 DCEEC_EngyPct3 "UNM";
BA_ "PacketOrder" SG_ 2151809024 DCEEC_EngyPct3 3;
BA_ "SignalLongName" SG_ 2151809024 DCEEC_EngyPct3 "Drive Cycle Electrical Energy Consumed : Energy Percent 3";
BA_ "VNSigAllNodes" SG_ 2151809024 DCEEC_EngyPct3 1;
BA_ "GenSigDeltaValue" SG_ 2151809024 DCEEC_EngyPct2 1;
BA_ "GenSigSendType" SG_ 2151809024 DCEEC_EngyPct2 12;
BA_ "GenSigSendOnInit" SG_ 2151809024 DCEEC_EngyPct2 1;
BA_ "VNSigInfotainment" SG_ 2151809024 DCEEC_EngyPct2 1;
BA_ "SignalType" SG_ 2151809024 DCEEC_EngyPct2 "UNM";
BA_ "PacketOrder" SG_ 2151809024 DCEEC_EngyPct2 2;
BA_ "SignalLongName" SG_ 2151809024 DCEEC_EngyPct2 "Drive Cycle Electrical Energy Consumed : Energy Percent 2";
BA_ "VNSigAllNodes" SG_ 2151809024 DCEEC_EngyPct2 1;
BA_ "GenSigDeltaValue" SG_ 2151809024 DCEEC_EngyPct1 1;
BA_ "GenSigSendType" SG_ 2151809024 DCEEC_EngyPct1 12;
BA_ "GenSigSendOnInit" SG_ 2151809024 DCEEC_EngyPct1 1;
BA_ "VNSigInfotainment" SG_ 2151809024 DCEEC_EngyPct1 1;
BA_ "SignalType" SG_ 2151809024 DCEEC_EngyPct1 "UNM";
BA_ "PacketOrder" SG_ 2151809024 DCEEC_EngyPct1 1;
BA_ "SignalLongName" SG_ 2151809024 DCEEC_EngyPct1 "Drive Cycle Electrical Energy Consumed : Energy Percent 1";
BA_ "VNSigAllNodes" SG_ 2151809024 DCEEC_EngyPct1 1;
BA_ "GenSigDeltaValue" SG_ 2151858176 DrvCycElecEngySt4 1;
BA_ "GenSigSendType" SG_ 2151858176 DrvCycElecEngySt4 12;
BA_ "GenSigSendOnInit" SG_ 2151858176 DrvCycElecEngySt4 1;
BA_ "VNSigInfotainment" SG_ 2151858176 DrvCycElecEngySt4 1;
BA_ "SignalType" SG_ 2151858176 DrvCycElecEngySt4 "UNM";
BA_ "SignalLongName" SG_ 2151858176 DrvCycElecEngySt4 "Drive Cycle Electrical Energy State 4";
BA_ "VNSigAllNodes" SG_ 2151858176 DrvCycElecEngySt4 1;
BA_ "GenSigDeltaValue" SG_ 2151858176 DrvCycElecEngySt3 1;
BA_ "GenSigSendType" SG_ 2151858176 DrvCycElecEngySt3 12;
BA_ "GenSigSendOnInit" SG_ 2151858176 DrvCycElecEngySt3 1;
BA_ "VNSigInfotainment" SG_ 2151858176 DrvCycElecEngySt3 1;
BA_ "SignalType" SG_ 2151858176 DrvCycElecEngySt3 "UNM";
BA_ "SignalLongName" SG_ 2151858176 DrvCycElecEngySt3 "Drive Cycle Electrical Energy State 3";
BA_ "VNSigAllNodes" SG_ 2151858176 DrvCycElecEngySt3 1;
BA_ "GenSigDeltaValue" SG_ 2151858176 DrvCycElecEngySt2 1;
BA_ "GenSigSendType" SG_ 2151858176 DrvCycElecEngySt2 12;
BA_ "GenSigSendOnInit" SG_ 2151858176 DrvCycElecEngySt2 1;
BA_ "VNSigInfotainment" SG_ 2151858176 DrvCycElecEngySt2 1;
BA_ "SignalType" SG_ 2151858176 DrvCycElecEngySt2 "UNM";
BA_ "SignalLongName" SG_ 2151858176 DrvCycElecEngySt2 "Drive Cycle Electrical Energy State 2";
BA_ "VNSigAllNodes" SG_ 2151858176 DrvCycElecEngySt2 1;
BA_ "GenSigDeltaValue" SG_ 2151858176 DrvCycElecEngySt1 1;
BA_ "GenSigSendType" SG_ 2151858176 DrvCycElecEngySt1 12;
BA_ "GenSigSendOnInit" SG_ 2151858176 DrvCycElecEngySt1 1;
BA_ "VNSigInfotainment" SG_ 2151858176 DrvCycElecEngySt1 1;
BA_ "SignalType" SG_ 2151858176 DrvCycElecEngySt1 "UNM";
BA_ "SignalLongName" SG_ 2151858176 DrvCycElecEngySt1 "Drive Cycle Electrical Energy State 1";
BA_ "VNSigAllNodes" SG_ 2151858176 DrvCycElecEngySt1 1;
BA_ "GenSigDeltaValue" SG_ 2150547456 HVDpltnMdCnfdcTrndg 1;
BA_ "GenSigSendType" SG_ 2150547456 HVDpltnMdCnfdcTrndg 12;
BA_ "SignalType" SG_ 2150547456 HVDpltnMdCnfdcTrndg "SNM";
BA_ "SignalLongName" SG_ 2150547456 HVDpltnMdCnfdcTrndg "High Voltage Depletion Mode Confidence Trending";
BA_ "VNSigAllNodes" SG_ 2150547456 HVDpltnMdCnfdcTrndg 1;
BA_ "GenSigSendType" SG_ 2150547456 OffBrdHVCVehPwrLvl 10;
BA_ "GenSigSendOnInit" SG_ 2150547456 OffBrdHVCVehPwrLvl 1;
BA_ "VNSigInfotainment" SG_ 2150547456 OffBrdHVCVehPwrLvl 1;
BA_ "SignalType" SG_ 2150547456 OffBrdHVCVehPwrLvl "ENM";
BA_ "SignalLongName" SG_ 2150547456 OffBrdHVCVehPwrLvl "Off Board High Voltage Charging Vehicle Power Level";
BA_ "VNSigAllNodes" SG_ 2150547456 OffBrdHVCVehPwrLvl 1;
BA_ "GenSigSendType" SG_ 2150547456 OffBrdHVCVehPwrDrtd 10;
BA_ "GenSigSendOnInit" SG_ 2150547456 OffBrdHVCVehPwrDrtd 1;
BA_ "VNSigInfotainment" SG_ 2150547456 OffBrdHVCVehPwrDrtd 1;
BA_ "SignalType" SG_ 2150547456 OffBrdHVCVehPwrDrtd "BLN";
BA_ "SignalLongName" SG_ 2150547456 OffBrdHVCVehPwrDrtd "Off Board High Voltage Charging Vehicle Power Derated";
BA_ "VNSigAllNodes" SG_ 2150547456 OffBrdHVCVehPwrDrtd 1;
BA_ "GenSigSendType" SG_ 2150547456 OffBrdHVCVehCplrLkd 10;
BA_ "GenSigSendOnInit" SG_ 2150547456 OffBrdHVCVehCplrLkd 1;
BA_ "VNSigInfotainment" SG_ 2150547456 OffBrdHVCVehCplrLkd 1;
BA_ "SignalType" SG_ 2150547456 OffBrdHVCVehCplrLkd "BLN";
BA_ "SignalLongName" SG_ 2150547456 OffBrdHVCVehCplrLkd "Off Board High Voltage Charging Vehicle Coupler Locked";
BA_ "VNSigAllNodes" SG_ 2150547456 OffBrdHVCVehCplrLkd 1;
BA_ "GenSigSendType" SG_ 2150547456 OffBrdHVBlkChrgCmp 10;
BA_ "SignalType" SG_ 2150547456 OffBrdHVBlkChrgCmp "BLN";
BA_ "SignalLongName" SG_ 2150547456 OffBrdHVBlkChrgCmp "Off Board High Voltage Bulk Charging Complete";
BA_ "VNSigAllNodes" SG_ 2150547456 OffBrdHVBlkChrgCmp 1;
BA_ "GenSigDeltaValue" SG_ 2150547456 OBHVBCCT_MinofHr 1;
BA_ "GenSigSendType" SG_ 2150547456 OBHVBCCT_MinofHr 12;
BA_ "GenSigSendOnInit" SG_ 2150547456 OBHVBCCT_MinofHr 1;
BA_ "VNSigInfotainment" SG_ 2150547456 OBHVBCCT_MinofHr 1;
BA_ "SignalType" SG_ 2150547456 OBHVBCCT_MinofHr "UNM";
BA_ "PacketOrder" SG_ 2150547456 OBHVBCCT_MinofHr 3;
BA_ "SignalLongName" SG_ 2150547456 OBHVBCCT_MinofHr "Off Board High Voltage Bulk Charging Complete Time : Minute of Hour";
BA_ "VNSigAllNodes" SG_ 2150547456 OBHVBCCT_MinofHr 1;
BA_ "GenSigDeltaValue" SG_ 2150547456 OBHVBCCT_HrofDay 1;
BA_ "GenSigSendType" SG_ 2150547456 OBHVBCCT_HrofDay 12;
BA_ "GenSigSendOnInit" SG_ 2150547456 OBHVBCCT_HrofDay 1;
BA_ "VNSigInfotainment" SG_ 2150547456 OBHVBCCT_HrofDay 1;
BA_ "SignalType" SG_ 2150547456 OBHVBCCT_HrofDay "UNM";
BA_ "PacketOrder" SG_ 2150547456 OBHVBCCT_HrofDay 2;
BA_ "SignalLongName" SG_ 2150547456 OBHVBCCT_HrofDay "Off Board High Voltage Bulk Charging Complete Time : Hour of Day";
BA_ "VNSigAllNodes" SG_ 2150547456 OBHVBCCT_HrofDay 1;
BA_ "GenSigDeltaValue" SG_ 2150547456 OBHVBCCT_DayofWk 1;
BA_ "GenSigSendType" SG_ 2150547456 OBHVBCCT_DayofWk 12;
BA_ "GenSigSendOnInit" SG_ 2150547456 OBHVBCCT_DayofWk 1;
BA_ "VNSigInfotainment" SG_ 2150547456 OBHVBCCT_DayofWk 1;
BA_ "SignalType" SG_ 2150547456 OBHVBCCT_DayofWk "UNM";
BA_ "PacketOrder" SG_ 2150547456 OBHVBCCT_DayofWk 1;
BA_ "SignalLongName" SG_ 2150547456 OBHVBCCT_DayofWk "Off Board High Voltage Bulk Charging Complete Time : Day of Week";
BA_ "VNSigAllNodes" SG_ 2150547456 OBHVBCCT_DayofWk 1;
BA_ "GenSigSendType" SG_ 2150547456 ElecPrplsnMtrOvrSpdIO 10;
BA_ "SignalType" SG_ 2150547456 ElecPrplsnMtrOvrSpdIO "BLN";
BA_ "SignalLongName" SG_ 2150547456 ElecPrplsnMtrOvrSpdIO "Electric Propulsion Motor Over Speed Indication On";
BA_ "VNSigAllNodes" SG_ 2150547456 ElecPrplsnMtrOvrSpdIO 1;
BA_ "GenSigSendType" SG_ 2150547456 HVBatOutOfEnrgyInd 10;
BA_ "VNSigInfotainment" SG_ 2150547456 HVBatOutOfEnrgyInd 1;
BA_ "SignalType" SG_ 2150547456 HVBatOutOfEnrgyInd "ENM";
BA_ "SignalLongName" SG_ 2150547456 HVBatOutOfEnrgyInd "High Voltage Battery Out of Energy Indication";
BA_ "VNSigAllNodes" SG_ 2150547456 HVBatOutOfEnrgyInd 1;
BA_ "GenSigSendType" SG_ 2150547456 CntrsOpnUndrTmpIO 10;
BA_ "VNSigInfotainment" SG_ 2150547456 CntrsOpnUndrTmpIO 1;
BA_ "SignalType" SG_ 2150547456 CntrsOpnUndrTmpIO "BLN";
BA_ "SignalLongName" SG_ 2150547456 CntrsOpnUndrTmpIO "Contactors Open Under Temperature Indication On";
BA_ "VNSigAllNodes" SG_ 2150547456 CntrsOpnUndrTmpIO 1;
BA_ "GenSigSendType" SG_ 2150547456 HVBatCntctrsOpnIO 10;
BA_ "SignalType" SG_ 2150547456 HVBatCntctrsOpnIO "BLN";
BA_ "SignalLongName" SG_ 2150547456 HVBatCntctrsOpnIO "High Voltage Battery Contactors Open Indication On";
BA_ "VNSigAllNodes" SG_ 2150547456 HVBatCntctrsOpnIO 1;
BA_ "GenSigSendType" SG_ 2150547456 GrnAudQueReq 10;
BA_ "VNSigInfotainment" SG_ 2150547456 GrnAudQueReq 1;
BA_ "SignalType" SG_ 2150547456 GrnAudQueReq "BLN";
BA_ "SignalLongName" SG_ 2150547456 GrnAudQueReq "Green Audio Queue Request";
BA_ "VNSigAllNodes" SG_ 2150547456 GrnAudQueReq 1;
BA_ "GenSigSendType" SG_ 2150547456 SvcHybChrgSysIO 10;
BA_ "VNSigInfotainment" SG_ 2150547456 SvcHybChrgSysIO 1;
BA_ "SignalType" SG_ 2150547456 SvcHybChrgSysIO "BLN";
BA_ "SignalLongName" SG_ 2150547456 SvcHybChrgSysIO "Service Hybrid Charging System Indication On";
BA_ "VNSigAllNodes" SG_ 2150547456 SvcHybChrgSysIO 1;
BA_ "GenSigSendType" SG_ 2150547456 HVChrgrSysStat 10;
BA_ "GenSigSendOnInit" SG_ 2150547456 HVChrgrSysStat 1;
BA_ "VNSigInfotainment" SG_ 2150547456 HVChrgrSysStat 1;
BA_ "SignalType" SG_ 2150547456 HVChrgrSysStat "ENM";
BA_ "SignalLongName" SG_ 2150547456 HVChrgrSysStat "High Voltage Charger System Status";
BA_ "VNSigAllNodes" SG_ 2150547456 HVChrgrSysStat 1;
BA_ "GenSigSendType" SG_ 2150547456 HVChrgrCplrStat 10;
BA_ "GenSigSendOnInit" SG_ 2150547456 HVChrgrCplrStat 1;
BA_ "VNSigInfotainment" SG_ 2150547456 HVChrgrCplrStat 1;
BA_ "SignalType" SG_ 2150547456 HVChrgrCplrStat "ENM";
BA_ "SignalLongName" SG_ 2150547456 HVChrgrCplrStat "High Voltage Charger Coupler Status";
BA_ "VNSigAllNodes" SG_ 2150547456 HVChrgrCplrStat 1;
BA_ "GenSigSendType" SG_ 2150547456 HVBatLimDTmpInd 10;
BA_ "GenSigSendOnInit" SG_ 2150547456 HVBatLimDTmpInd 2;
BA_ "VNSigInfotainment" SG_ 2150547456 HVBatLimDTmpInd 1;
BA_ "SignalType" SG_ 2150547456 HVBatLimDTmpInd "ENM";
BA_ "SignalLongName" SG_ 2150547456 HVBatLimDTmpInd "High Voltage Battery Limitation Due to Temperature Indication";
BA_ "VNSigAllNodes" SG_ 2150547456 HVBatLimDTmpInd 1;
BA_ "GenSigSendType" SG_ 2150547456 HVBatChrgCrdConnIO 10;
BA_ "GenSigSendOnInit" SG_ 2150547456 HVBatChrgCrdConnIO 2;
BA_ "VNSigInfotainment" SG_ 2150547456 HVBatChrgCrdConnIO 1;
BA_ "SignalType" SG_ 2150547456 HVBatChrgCrdConnIO "BLN";
BA_ "SignalLongName" SG_ 2150547456 HVBatChrgCrdConnIO "High Voltage Battery Charge Cord Connected Indication On";
BA_ "VNSigAllNodes" SG_ 2150547456 HVBatChrgCrdConnIO 1;
BA_ "GenSigSendType" SG_ 2150547456 VehChrgMdSt 10;
BA_ "GenSigSendOnInit" SG_ 2150547456 VehChrgMdSt 2;
BA_ "VNSigInfotainment" SG_ 2150547456 VehChrgMdSt 1;
BA_ "SignalType" SG_ 2150547456 VehChrgMdSt "ENM";
BA_ "SignalLongName" SG_ 2150547456 VehChrgMdSt "Vehicle Charge Mode State";
BA_ "VNSigAllNodes" SG_ 2150547456 VehChrgMdSt 1;
BA_ "GenSigDeltaValue" SG_ 2150547456 HVDpltnMdRng 1;
BA_ "GenSigSendType" SG_ 2150547456 HVDpltnMdRng 12;
BA_ "GenSigSendOnInit" SG_ 2150547456 HVDpltnMdRng 1;
BA_ "VNSigInfotainment" SG_ 2150547456 HVDpltnMdRng 1;
BA_ "SignalType" SG_ 2150547456 HVDpltnMdRng "UNM";
BA_ "SignalLongName" SG_ 2150547456 HVDpltnMdRng "High Voltage Depletion Mode Range";
BA_ "VNSigAllNodes" SG_ 2150547456 HVDpltnMdRng 1;
BA_ "GenSigSendType" SG_ 2150547456 ChgrSysAdblIndReq 10;
BA_ "VNSigInfotainment" SG_ 2150547456 ChgrSysAdblIndReq 1;
BA_ "SignalType" SG_ 2150547456 ChgrSysAdblIndReq "ENM";
BA_ "SignalLongName" SG_ 2150547456 ChgrSysAdblIndReq "Charger System Audible Indication Request";
BA_ "VNSigAllNodes" SG_ 2150547456 ChgrSysAdblIndReq 1;
BA_ "GenSigSendType" SG_ 2151489536 ACCLwVisbltyIO 10;
BA_ "SignalType" SG_ 2151489536 ACCLwVisbltyIO "BLN";
BA_ "SignalLongName" SG_ 2151489536 ACCLwVisbltyIO "Adaptive Cruise Control Low Visibility Indication On";
BA_ "VNSigAllNodes" SG_ 2151489536 ACCLwVisbltyIO 1;
BA_ "GenSigSendType" SG_ 2151489536 NVSysStat 10;
BA_ "SignalType" SG_ 2151489536 NVSysStat "ENM";
BA_ "SignalLongName" SG_ 2151489536 NVSysStat "Night Vision System Status";
BA_ "VNSigAllNodes" SG_ 2151489536 NVSysStat 1;
BA_ "GenSigSendType" SG_ 2151489536 RVBShtToPrkBfExtngVehIO 10;
BA_ "GenSigSendOnInit" SG_ 2151489536 RVBShtToPrkBfExtngVehIO 2;
BA_ "SignalType" SG_ 2151489536 RVBShtToPrkBfExtngVehIO "BLN";
BA_ "SignalLongName" SG_ 2151489536 RVBShtToPrkBfExtngVehIO "RVB Shift to Park Before Exiting Vehicle Indication On";
BA_ "VNSigAllNodes" SG_ 2151489536 RVBShtToPrkBfExtngVehIO 1;
BA_ "GenSigSendType" SG_ 2151489536 RVBAutoBrkRlsIO 10;
BA_ "SignalType" SG_ 2151489536 RVBAutoBrkRlsIO "BLN";
BA_ "SignalLongName" SG_ 2151489536 RVBAutoBrkRlsIO "RVB Autonomous Brake Release Indication On";
BA_ "VNSigAllNodes" SG_ 2151489536 RVBAutoBrkRlsIO 1;
BA_ "SignalType" SG_ 2149761024 PsngStPerfMdCsCrStVal "ENM";
BA_ "SignalLongName" SG_ 2149761024 PsngStPerfMdCsCrStVal "Passenger Seat Performance Mode Customization Current Setting Value";
BA_ "VNSigAllNodes" SG_ 2149761024 PsngStPerfMdCsCrStVal 1;
BA_ "SignalType" SG_ 2149761024 PsngStPerfMdCsStAvl "BLN";
BA_ "SignalLongName" SG_ 2149761024 PsngStPerfMdCsStAvl "Passenger Seat Performance Mode Customization Setting Available";
BA_ "VNSigAllNodes" SG_ 2149761024 PsngStPerfMdCsStAvl 1;
BA_ "SignalType" SG_ 2149761024 ElvtdIdlCstCrStVal "ENM";
BA_ "SignalLongName" SG_ 2149761024 ElvtdIdlCstCrStVal "Elevated Idle Customization Current Setting Value";
BA_ "VNSigAllNodes" SG_ 2149761024 ElvtdIdlCstCrStVal 1;
BA_ "SignalType" SG_ 2149761024 ElvtdIdlCstStAvl "BLN";
BA_ "SignalLongName" SG_ 2149761024 ElvtdIdlCstStAvl "Elevated Idle Customization Setting Available";
BA_ "VNSigAllNodes" SG_ 2149761024 ElvtdIdlCstStAvl 1;
BA_ "SignalType" SG_ 2149761024 TCTPIR_TnsEsClCDwT "UNM";
BA_ "PacketOrder" SG_ 2149761024 TCTPIR_TnsEsClCDwT 3;
BA_ "SignalLongName" SG_ 2149761024 TCTPIR_TnsEsClCDwT "Transmission Clutch Thermal Protection Indication Request : Transmission Estimated Clutch Cool-down Temperature Target Display";
BA_ "VNSigAllNodes" SG_ 2149761024 TCTPIR_TnsEsClCDwT 1;
BA_ "SignalType" SG_ 2149761024 TCTPIR_TnsEsClTmpD "UNM";
BA_ "PacketOrder" SG_ 2149761024 TCTPIR_TnsEsClTmpD 2;
BA_ "SignalLongName" SG_ 2149761024 TCTPIR_TnsEsClTmpD "Transmission Clutch Thermal Protection Indication Request : Transmission Estimated Clutch Temperature Display";
BA_ "VNSigAllNodes" SG_ 2149761024 TCTPIR_TnsEsClTmpD 1;
BA_ "SignalType" SG_ 2149761024 TCTPIR_DrvNotfn "ENM";
BA_ "PacketOrder" SG_ 2149761024 TCTPIR_DrvNotfn 1;
BA_ "SignalLongName" SG_ 2149761024 TCTPIR_DrvNotfn "Transmission Clutch Thermal Protection Indication Request : Driver Notification";
BA_ "VNSigAllNodes" SG_ 2149761024 TCTPIR_DrvNotfn 1;
BA_ "SignalType" SG_ 2149761024 TrlrStabAstActIO "BLN";
BA_ "SignalLongName" SG_ 2149761024 TrlrStabAstActIO "Trailer Stability Assist Active Indication On";
BA_ "VNSigAllNodes" SG_ 2149761024 TrlrStabAstActIO 1;
BA_ "SignalType" SG_ 2149761024 PerfTrcCrnExStngVal "ENM";
BA_ "SignalLongName" SG_ 2149761024 PerfTrcCrnExStngVal "Performance Traction Corner Exit Setting Value";
BA_ "VNSigAllNodes" SG_ 2149761024 PerfTrcCrnExStngVal 1;
BA_ "SignalType" SG_ 2149761024 ActVehAccelV "ENM";
BA_ "SignalLongName" SG_ 2149761024 ActVehAccelV "Actual Vehicle Acceleration Validity";
BA_ "VNSigAllNodes" SG_ 2149761024 ActVehAccelV 1;
BA_ "SignalType" SG_ 2149761024 ActVehAccel "SNM";
BA_ "SignalLongName" SG_ 2149761024 ActVehAccel "Actual Vehicle Acceleration";
BA_ "VNSigAllNodes" SG_ 2149761024 ActVehAccel 1;
BA_ "GenSigSendType" SG_ 2155012096 SODTmpUnavlbleIO 10;
BA_ "SignalType" SG_ 2155012096 SODTmpUnavlbleIO "BLN";
BA_ "SignalLongName" SG_ 2155012096 SODTmpUnavlbleIO "Side Obstacle Detection Temporarily Unavailable Indication On";
BA_ "VNSigAllNodes" SG_ 2155012096 SODTmpUnavlbleIO 1;
BA_ "GenSigSendType" SG_ 2155012096 SODSnsClnRqdIO 10;
BA_ "SignalType" SG_ 2155012096 SODSnsClnRqdIO "BLN";
BA_ "SignalLongName" SG_ 2155012096 SODSnsClnRqdIO "Side Obstacle Detection Sensor Cleaning Required Indication On";
BA_ "VNSigAllNodes" SG_ 2155012096 SODSnsClnRqdIO 1;
BA_ "GenSigInactiveValue" SG_ 2155012096 SODRIC_Ind3 1;
BA_ "GenSigSendType" SG_ 2155012096 SODRIC_Ind3 11;
BA_ "SignalType" SG_ 2155012096 SODRIC_Ind3 "BLN";
BA_ "PacketOrder" SG_ 2155012096 SODRIC_Ind3 4;
BA_ "SignalLongName" SG_ 2155012096 SODRIC_Ind3 "Side Obstacle Detection Right Indication Control : Indicator 3";
BA_ "VNSigAllNodes" SG_ 2155012096 SODRIC_Ind3 1;
BA_ "GenSigSendType" SG_ 2155012096 SODRIC_Ind2 10;
BA_ "SignalType" SG_ 2155012096 SODRIC_Ind2 "BLN";
BA_ "PacketOrder" SG_ 2155012096 SODRIC_Ind2 3;
BA_ "SignalLongName" SG_ 2155012096 SODRIC_Ind2 "Side Obstacle Detection Right Indication Control : Indicator 2";
BA_ "VNSigAllNodes" SG_ 2155012096 SODRIC_Ind2 1;
BA_ "GenSigSendType" SG_ 2155012096 SODRIC_Ind1 10;
BA_ "SignalType" SG_ 2155012096 SODRIC_Ind1 "BLN";
BA_ "PacketOrder" SG_ 2155012096 SODRIC_Ind1 2;
BA_ "SignalLongName" SG_ 2155012096 SODRIC_Ind1 "Side Obstacle Detection Right Indication Control : Indicator 1";
BA_ "VNSigAllNodes" SG_ 2155012096 SODRIC_Ind1 1;
BA_ "GenSigSendType" SG_ 2155012096 SODRIC_IndReq 10;
BA_ "SignalType" SG_ 2155012096 SODRIC_IndReq "ENM";
BA_ "PacketOrder" SG_ 2155012096 SODRIC_IndReq 1;
BA_ "SignalLongName" SG_ 2155012096 SODRIC_IndReq "Side Obstacle Detection Right Indication Control : Indication Request";
BA_ "VNSigAllNodes" SG_ 2155012096 SODRIC_IndReq 1;
BA_ "GenSigSendType" SG_ 2155012096 SrvSODSysIO 10;
BA_ "GenSigSendOnInit" SG_ 2155012096 SrvSODSysIO 2;
BA_ "SignalType" SG_ 2155012096 SrvSODSysIO "BLN";
BA_ "SignalLongName" SG_ 2155012096 SrvSODSysIO "Service Side Obstacle Detection System Indication On";
BA_ "VNSigAllNodes" SG_ 2155012096 SrvSODSysIO 1;
BA_ "GenSigSendType" SG_ 2150514688 SldngDrRgtStat 10;
BA_ "GenSigSendOnInit" SG_ 2150514688 SldngDrRgtStat 1;
BA_ "SignalType" SG_ 2150514688 SldngDrRgtStat "ENM";
BA_ "SignalLongName" SG_ 2150514688 SldngDrRgtStat "Sliding Door Right Status";
BA_ "VNSigAllNodes" SG_ 2150514688 SldngDrRgtStat 1;
BA_ "GenSigSendType" SG_ 2150514688 SldngDrLftStat 10;
BA_ "GenSigSendOnInit" SG_ 2150514688 SldngDrLftStat 1;
BA_ "SignalType" SG_ 2150514688 SldngDrLftStat "ENM";
BA_ "SignalLongName" SG_ 2150514688 SldngDrLftStat "Sliding Door Left Status";
BA_ "VNSigAllNodes" SG_ 2150514688 SldngDrLftStat 1;
BA_ "GenSigSendType" SG_ 2150514688 SdClsrObstclDtctdStat 10;
BA_ "GenSigSendOnInit" SG_ 2150514688 SdClsrObstclDtctdStat 1;
BA_ "SignalType" SG_ 2150514688 SdClsrObstclDtctdStat "BLN";
BA_ "SignalLongName" SG_ 2150514688 SdClsrObstclDtctdStat "Side Closure Obstacle Detected Status";
BA_ "VNSigAllNodes" SG_ 2150514688 SdClsrObstclDtctdStat 1;
BA_ "GenSigSendType" SG_ 2150514688 PwrSldngDrUnavlblIO 10;
BA_ "SignalType" SG_ 2150514688 PwrSldngDrUnavlblIO "BLN";
BA_ "SignalLongName" SG_ 2150514688 PwrSldngDrUnavlblIO "Power Sliding Door Unavailable Indication On";
BA_ "VNSigAllNodes" SG_ 2150514688 PwrSldngDrUnavlblIO 1;
BA_ "GenSigDeltaValue" SG_ 2158067712 TSDUAE_YCoOdntRq 1;
BA_ "GenSigSendType" SG_ 2158067712 TSDUAE_YCoOdntRq 12;
BA_ "SignalType" SG_ 2158067712 TSDUAE_YCoOdntRq "UNM";
BA_ "PacketOrder" SG_ 2158067712 TSDUAE_YCoOdntRq 5;
BA_ "SignalLongName" SG_ 2158067712 TSDUAE_YCoOdntRq "Touch Screen Display User Action Extended : Y_Coordinate Request";
BA_ "VNSigAllNodes" SG_ 2158067712 TSDUAE_YCoOdntRq 1;
BA_ "GenSigDeltaValue" SG_ 2158067712 TSDUAE_XCoOdntRq 1;
BA_ "GenSigSendType" SG_ 2158067712 TSDUAE_XCoOdntRq 12;
BA_ "SignalType" SG_ 2158067712 TSDUAE_XCoOdntRq "UNM";
BA_ "PacketOrder" SG_ 2158067712 TSDUAE_XCoOdntRq 4;
BA_ "SignalLongName" SG_ 2158067712 TSDUAE_XCoOdntRq "Touch Screen Display User Action Extended : X_Coordinate Request";
BA_ "VNSigAllNodes" SG_ 2158067712 TSDUAE_XCoOdntRq 1;
BA_ "GenSigSendType" SG_ 2158067712 TSDUAE_ScrnPrsdRq 10;
BA_ "SignalType" SG_ 2158067712 TSDUAE_ScrnPrsdRq "BLN";
BA_ "PacketOrder" SG_ 2158067712 TSDUAE_ScrnPrsdRq 1;
BA_ "SignalLongName" SG_ 2158067712 TSDUAE_ScrnPrsdRq "Touch Screen Display User Action Extended : Screen Press Requested";
BA_ "VNSigAllNodes" SG_ 2158067712 TSDUAE_ScrnPrsdRq 1;
BA_ "GenSigDeltaValue" SG_ 2158067712 TSDUAE_RotEnc 1;
BA_ "GenSigSendType" SG_ 2158067712 TSDUAE_RotEnc 12;
BA_ "SignalType" SG_ 2158067712 TSDUAE_RotEnc "SNM";
BA_ "PacketOrder" SG_ 2158067712 TSDUAE_RotEnc 6;
BA_ "SignalLongName" SG_ 2158067712 TSDUAE_RotEnc "Touch Screen Display User Action Extended : Rotary Encoder";
BA_ "VNSigAllNodes" SG_ 2158067712 TSDUAE_RotEnc 1;
BA_ "GenSigSendType" SG_ 2158067712 TSDUAE_RotBtnPsh 10;
BA_ "SignalType" SG_ 2158067712 TSDUAE_RotBtnPsh "BLN";
BA_ "PacketOrder" SG_ 2158067712 TSDUAE_RotBtnPsh 2;
BA_ "SignalLongName" SG_ 2158067712 TSDUAE_RotBtnPsh "Touch Screen Display User Action Extended : Rotary Button Push";
BA_ "VNSigAllNodes" SG_ 2158067712 TSDUAE_RotBtnPsh 1;
BA_ "GenSigSendType" SG_ 2158067712 TSDUAE_GrphStrkInfRq 10;
BA_ "SignalType" SG_ 2158067712 TSDUAE_GrphStrkInfRq "ENM";
BA_ "PacketOrder" SG_ 2158067712 TSDUAE_GrphStrkInfRq 3;
BA_ "SignalLongName" SG_ 2158067712 TSDUAE_GrphStrkInfRq "Touch Screen Display User Action Extended : Graphic Stroke Information Request";
BA_ "VNSigAllNodes" SG_ 2158067712 TSDUAE_GrphStrkInfRq 1;
BA_ "GenSigSendType" SG_ 2158051328 VidSrcUICntrlStat 10;
BA_ "GenSigSendOnInit" SG_ 2158051328 VidSrcUICntrlStat 1;
BA_ "SignalType" SG_ 2158051328 VidSrcUICntrlStat "ENM";
BA_ "SignalLongName" SG_ 2158051328 VidSrcUICntrlStat "Video Source User Interface Control Status";
BA_ "VNSigAllNodes" SG_ 2158051328 VidSrcUICntrlStat 1;
BA_ "GenSigSendType" SG_ 2158051328 VidMstrDsplyMd 10;
BA_ "GenSigSendOnInit" SG_ 2158051328 VidMstrDsplyMd 1;
BA_ "SignalType" SG_ 2158051328 VidMstrDsplyMd "ENM";
BA_ "SignalLongName" SG_ 2158051328 VidMstrDsplyMd "Video Master Display Mode";
BA_ "VNSigAllNodes" SG_ 2158051328 VidMstrDsplyMd 1;
BA_ "GenSigSendType" SG_ 2158051328 VidMstrSrcType 10;
BA_ "GenSigSendOnInit" SG_ 2158051328 VidMstrSrcType 1;
BA_ "SignalType" SG_ 2158051328 VidMstrSrcType "ENM";
BA_ "SignalLongName" SG_ 2158051328 VidMstrSrcType "Video Master Source Type";
BA_ "VNSigAllNodes" SG_ 2158051328 VidMstrSrcType 1;
BA_ "GenSigSendType" SG_ 2158051328 VidMstrArbCmd 10;
BA_ "SignalType" SG_ 2158051328 VidMstrArbCmd "ENM";
BA_ "SignalLongName" SG_ 2158051328 VidMstrArbCmd "Video Master Arbitration Command";
BA_ "VNSigAllNodes" SG_ 2158051328 VidMstrArbCmd 1;
BA_ "GenSigSendType" SG_ 2158051328 TVDspCmd 10;
BA_ "SignalType" SG_ 2158051328 TVDspCmd "ENM";
BA_ "SignalLongName" SG_ 2158051328 TVDspCmd "TV Display Command";
BA_ "VNSigAllNodes" SG_ 2158051328 TVDspCmd 1;
BA_ "GenSigDeltaValue" SG_ 2158051328 RmtRcvrTunVal 1;
BA_ "GenSigSendType" SG_ 2158051328 RmtRcvrTunVal 12;
BA_ "SignalType" SG_ 2158051328 RmtRcvrTunVal "SNM";
BA_ "SignalLongName" SG_ 2158051328 RmtRcvrTunVal "Remote Receiver Tune Value";
BA_ "VNSigAllNodes" SG_ 2158051328 RmtRcvrTunVal 1;
BA_ "GenSigSendType" SG_ 2158051328 RmtRcvrTunCmnd 10;
BA_ "SignalType" SG_ 2158051328 RmtRcvrTunCmnd "ENM";
BA_ "SignalLongName" SG_ 2158051328 RmtRcvrTunCmnd "Remote Receiver Tune Command";
BA_ "VNSigAllNodes" SG_ 2158051328 RmtRcvrTunCmnd 1;
BA_ "GenSigSendType" SG_ 2158051328 RemRcvrSrcInpCmd 10;
BA_ "SignalType" SG_ 2158051328 RemRcvrSrcInpCmd "ENM";
BA_ "SignalLongName" SG_ 2158051328 RemRcvrSrcInpCmd "Remote Receiver Source Input Command";
BA_ "VNSigAllNodes" SG_ 2158051328 RemRcvrSrcInpCmd 1;
BA_REL_ "GenSigSuprvResp" BU_SG_REL_ BCM_LS SG_ 2156298240 HVBSTLPC_MntOfHr 1;
BA_REL_ "GenSigSuprvResp" BU_SG_REL_ CSM_LS SG_ 2156298240 HVBSTLPC_MntOfHr 1;
BA_REL_ "GenSigSuprvResp" BU_SG_REL_ RadioHead_LS SG_ 2156298240 HVBSTLPC_MntOfHr 1;
BA_REL_ "GenSigSuprvResp" BU_SG_REL_ RadioHead_LS SG_ 2156298240 HVBSTLPC_MntOfHr 1;
BA_REL_ "GenSigSuprvResp" BU_SG_REL_ BCM_LS SG_ 2156298240 HVBSTLPC_HrOfDy 1;
BA_REL_ "GenSigSuprvResp" BU_SG_REL_ CSM_LS SG_ 2156298240 HVBSTLPC_HrOfDy 1;
BA_REL_ "GenSigSuprvResp" BU_SG_REL_ RadioHead_LS SG_ 2156298240 HVBSTLPC_HrOfDy 1;
BA_REL_ "GenSigSuprvResp" BU_SG_REL_ RadioHead_LS SG_ 2156298240 HVBSTLPC_HrOfDy 1;
BA_REL_ "GenSigSuprvResp" BU_SG_REL_ BCM_LS SG_ 2156298240 HVBSTLPC_DyOfWk 1;
BA_REL_ "GenSigSuprvResp" BU_SG_REL_ CSM_LS SG_ 2156298240 HVBSTLPC_DyOfWk 1;
BA_REL_ "GenSigSuprvResp" BU_SG_REL_ RadioHead_LS SG_ 2156298240 HVBSTLPC_DyOfWk 1;
BA_REL_ "GenSigSuprvResp" BU_SG_REL_ RadioHead_LS SG_ 2156298240 HVBSTLPC_DyOfWk 1;
BA_REL_ "GenSigSuprvResp" BU_SG_REL_ BCM_LS SG_ 2156298240 HVBSTHPC_MntOfHr 1;
BA_REL_ "GenSigSuprvResp" BU_SG_REL_ CSM_LS SG_ 2156298240 HVBSTHPC_MntOfHr 1;
BA_REL_ "GenSigSuprvResp" BU_SG_REL_ RadioHead_LS SG_ 2156298240 HVBSTHPC_MntOfHr 1;
BA_REL_ "GenSigSuprvResp" BU_SG_REL_ RadioHead_LS SG_ 2156298240 HVBSTHPC_MntOfHr 1;
BA_REL_ "GenSigSuprvResp" BU_SG_REL_ BCM_LS SG_ 2156298240 HVBSTHPC_HrOfDy 1;
BA_REL_ "GenSigSuprvResp" BU_SG_REL_ CSM_LS SG_ 2156298240 HVBSTHPC_HrOfDy 1;
BA_REL_ "GenSigSuprvResp" BU_SG_REL_ RadioHead_LS SG_ 2156298240 HVBSTHPC_HrOfDy 1;
BA_REL_ "GenSigSuprvResp" BU_SG_REL_ RadioHead_LS SG_ 2156298240 HVBSTHPC_HrOfDy 1;
BA_REL_ "GenSigSuprvResp" BU_SG_REL_ BCM_LS SG_ 2156298240 HVBSTHPC_DyOfWk 1;
BA_REL_ "GenSigSuprvResp" BU_SG_REL_ CSM_LS SG_ 2156298240 HVBSTHPC_DyOfWk 1;
BA_REL_ "GenSigSuprvResp" BU_SG_REL_ RadioHead_LS SG_ 2156298240 HVBSTHPC_DyOfWk 1;
BA_REL_ "GenSigSuprvResp" BU_SG_REL_ RadioHead_LS SG_ 2156298240 HVBSTHPC_DyOfWk 1;
BA_REL_ "GenSigSuprvResp" BU_SG_REL_ BCM_LS SG_ 2156298240 HVBCTLPC_MntOfHr 1;
BA_REL_ "GenSigSuprvResp" BU_SG_REL_ CSM_LS SG_ 2156298240 HVBCTLPC_MntOfHr 1;
BA_REL_ "GenSigSuprvResp" BU_SG_REL_ RadioHead_LS SG_ 2156298240 HVBCTLPC_MntOfHr 1;
BA_REL_ "GenSigSuprvResp" BU_SG_REL_ RadioHead_LS SG_ 2156298240 HVBCTLPC_MntOfHr 1;
BA_REL_ "GenSigSuprvResp" BU_SG_REL_ BCM_LS SG_ 2156298240 HVBCTLPC_HrOfDy 1;
BA_REL_ "GenSigSuprvResp" BU_SG_REL_ CSM_LS SG_ 2156298240 HVBCTLPC_HrOfDy 1;
BA_REL_ "GenSigSuprvResp" BU_SG_REL_ RadioHead_LS SG_ 2156298240 HVBCTLPC_HrOfDy 1;
BA_REL_ "GenSigSuprvResp" BU_SG_REL_ RadioHead_LS SG_ 2156298240 HVBCTLPC_HrOfDy 1;
BA_REL_ "GenSigSuprvResp" BU_SG_REL_ BCM_LS SG_ 2156298240 HVBCTLPC_DyOfWk 1;
BA_REL_ "GenSigSuprvResp" BU_SG_REL_ CSM_LS SG_ 2156298240 HVBCTLPC_DyOfWk 1;
BA_REL_ "GenSigSuprvResp" BU_SG_REL_ RadioHead_LS SG_ 2156298240 HVBCTLPC_DyOfWk 1;
BA_REL_ "GenSigSuprvResp" BU_SG_REL_ RadioHead_LS SG_ 2156298240 HVBCTLPC_DyOfWk 1;
BA_REL_ "GenSigSuprvResp" BU_SG_REL_ BCM_LS SG_ 2156298240 HVBCTHPC_MntOfHr 1;
BA_REL_ "GenSigSuprvResp" BU_SG_REL_ CSM_LS SG_ 2156298240 HVBCTHPC_MntOfHr 1;
BA_REL_ "GenSigSuprvResp" BU_SG_REL_ RadioHead_LS SG_ 2156298240 HVBCTHPC_MntOfHr 1;
BA_REL_ "GenSigSuprvResp" BU_SG_REL_ RadioHead_LS SG_ 2156298240 HVBCTHPC_MntOfHr 1;
BA_REL_ "GenSigSuprvResp" BU_SG_REL_ BCM_LS SG_ 2156298240 HVBCTHPC_HrOfDy 1;
BA_REL_ "GenSigSuprvResp" BU_SG_REL_ CSM_LS SG_ 2156298240 HVBCTHPC_HrOfDy 1;
BA_REL_ "GenSigSuprvResp" BU_SG_REL_ RadioHead_LS SG_ 2156298240 HVBCTHPC_HrOfDy 1;
BA_REL_ "GenSigSuprvResp" BU_SG_REL_ RadioHead_LS SG_ 2156298240 HVBCTHPC_HrOfDy 1;
BA_REL_ "GenSigSuprvResp" BU_SG_REL_ BCM_LS SG_ 2156298240 HVBCTHPC_DyOfWk 1;
BA_REL_ "GenSigSuprvResp" BU_SG_REL_ CSM_LS SG_ 2156298240 HVBCTHPC_DyOfWk 1;
BA_REL_ "GenSigSuprvResp" BU_SG_REL_ RadioHead_LS SG_ 2156298240 HVBCTHPC_DyOfWk 1;
BA_REL_ "GenSigSuprvResp" BU_SG_REL_ RadioHead_LS SG_ 2156298240 HVBCTHPC_DyOfWk 1;
BA_REL_ "GenSigSuprvResp" BU_SG_REL_ BCM_LS SG_ 2156298240 HVCSDTES_NPDTIO 1;
BA_REL_ "GenSigSuprvResp" BU_SG_REL_ BCM_LS SG_ 2156298240 HVCSDTES_LoPwrCIO 1;
BA_REL_ "GenSigSuprvResp" BU_SG_REL_ BCM_LS SG_ 2156298240 HVCSDTES_HiPwrCIO 1;
BA_REL_ "GenSigSuprvResp" BU_SG_REL_ IPC_LS SG_ 2149924864 PTOMobModTrnsInGrIO 1;
BA_REL_ "GenSigSuprvResp" BU_SG_REL_ IPC_LS SG_ 2149924864 a_12VBatSysUnstab 1;
BA_REL_ "GenSigSuprvResp" BU_SG_REL_ FCM_LS SG_ 2149924864 FwdClnMtgnBrkReqAct 1;
BA_REL_ "GenSigSuprvResp" BU_SG_REL_ IPC_LS SG_ 2149924864 TireRRLowTracIO 1;
BA_REL_ "GenSigSuprvResp" BU_SG_REL_ IPC_LS SG_ 2149924864 TireRFLowTracIO 1;
BA_REL_ "GenSigSuprvResp" BU_SG_REL_ IPC_LS SG_ 2149924864 TireLRLowTracIO 1;
BA_REL_ "GenSigSuprvResp" BU_SG_REL_ IPC_LS SG_ 2149924864 TireLFLowTracIO 1;
BA_REL_ "GenSigSuprvResp" BU_SG_REL_ IPC_LS SG_ 2149924864 HilRlbkCtrlActIO 1;
BA_REL_ "GenSigSuprvResp" BU_SG_REL_ IPC_LS SG_ 2149924864 FstIdlMdAct 1;
BA_REL_ "GenSigSuprvResp" BU_SG_REL_ IPC_LS SG_ 2149924864 DsplyPerfMdRq 1;
BA_REL_ "GenSigSuprvResp" BU_SG_REL_ FCM_LS SG_ 2149924864 DrvSelMd8Stat 1;
BA_REL_ "GenSigSuprvResp" BU_SG_REL_ ECC_LS SG_ 2149924864 DrvSelMd8Stat 1;
BA_REL_ "GenSigSuprvResp" BU_SG_REL_ FCM_LS SG_ 2149924864 DrvSelMd7Stat 1;
BA_REL_ "GenSigSuprvResp" BU_SG_REL_ ECC_LS SG_ 2149924864 DrvSelMd7Stat 1;
BA_REL_ "GenSigSuprvResp" BU_SG_REL_ FCM_LS SG_ 2149924864 DrvSelMd6Stat 1;
BA_REL_ "GenSigSuprvResp" BU_SG_REL_ ECC_LS SG_ 2149924864 DrvSelMd6Stat 1;
BA_REL_ "GenSigSuprvResp" BU_SG_REL_ FCM_LS SG_ 2149924864 DrvSelMd5Stat 1;
BA_REL_ "GenSigSuprvResp" BU_SG_REL_ ECC_LS SG_ 2149924864 DrvSelMd5Stat 1;
BA_REL_ "GenSigSuprvResp" BU_SG_REL_ FCM_LS SG_ 2149924864 DrvSelMd4Stat 1;
BA_REL_ "GenSigSuprvResp" BU_SG_REL_ ECC_LS SG_ 2149924864 DrvSelMd4Stat 1;
BA_REL_ "GenSigSuprvResp" BU_SG_REL_ CSM_LS SG_ 2149924864 DSMSS_DrvSelMd0Pn 1;
BA_REL_ "GenSigSuprvResp" BU_SG_REL_ RadioHead_LS SG_ 2149924864 DSMSS_DrvSelMd0Pn 1;
BA_REL_ "GenSigSuprvResp" BU_SG_REL_ CSM_LS SG_ 2149924864 DSMSS_DrvSelMd8Pn 1;
BA_REL_ "GenSigSuprvResp" BU_SG_REL_ RadioHead_LS SG_ 2149924864 DSMSS_DrvSelMd8Pn 1;
BA_REL_ "GenSigSuprvResp" BU_SG_REL_ CSM_LS SG_ 2149924864 DSMSS_DrvSelMd7Pn 1;
BA_REL_ "GenSigSuprvResp" BU_SG_REL_ RadioHead_LS SG_ 2149924864 DSMSS_DrvSelMd7Pn 1;
BA_REL_ "GenSigSuprvResp" BU_SG_REL_ CSM_LS SG_ 2149924864 DSMSS_DrvSelMd6Pn 1;
BA_REL_ "GenSigSuprvResp" BU_SG_REL_ RadioHead_LS SG_ 2149924864 DSMSS_DrvSelMd6Pn 1;
BA_REL_ "GenSigSuprvResp" BU_SG_REL_ CSM_LS SG_ 2149924864 DSMSS_DrvSelMd5Pn 1;
BA_REL_ "GenSigSuprvResp" BU_SG_REL_ RadioHead_LS SG_ 2149924864 DSMSS_DrvSelMd5Pn 1;
BA_REL_ "GenSigSuprvResp" BU_SG_REL_ CSM_LS SG_ 2149924864 DSMSS_DrvSelMd4Pn 1;
BA_REL_ "GenSigSuprvResp" BU_SG_REL_ RadioHead_LS SG_ 2149924864 DSMSS_DrvSelMd4Pn 1;
BA_REL_ "GenSigSuprvResp" BU_SG_REL_ CSM_LS SG_ 2149924864 DSMSS_DrvSelMd3Pn 1;
BA_REL_ "GenSigSuprvResp" BU_SG_REL_ RadioHead_LS SG_ 2149924864 DSMSS_DrvSelMd3Pn 1;
BA_REL_ "GenSigSuprvResp" BU_SG_REL_ CSM_LS SG_ 2149924864 DSMSS_DrvSelMd2Pn 1;
BA_REL_ "GenSigSuprvResp" BU_SG_REL_ RadioHead_LS SG_ 2149924864 DSMSS_DrvSelMd2Pn 1;
BA_REL_ "GenSigSuprvResp" BU_SG_REL_ CSM_LS SG_ 2149924864 DSMSS_DrvSelMd1Pn 1;
BA_REL_ "GenSigSuprvResp" BU_SG_REL_ RadioHead_LS SG_ 2149924864 DSMSS_DrvSelMd1Pn 1;
BA_REL_ "GenSigSuprvResp" BU_SG_REL_ CSM_LS SG_ 2149924864 DSMSS_DrvSelMd8Un 1;
BA_REL_ "GenSigSuprvResp" BU_SG_REL_ RadioHead_LS SG_ 2149924864 DSMSS_DrvSelMd8Un 1;
BA_REL_ "GenSigSuprvResp" BU_SG_REL_ CSM_LS SG_ 2149924864 DSMSS_DrvSelMd7Un 1;
BA_REL_ "GenSigSuprvResp" BU_SG_REL_ RadioHead_LS SG_ 2149924864 DSMSS_DrvSelMd7Un 1;
BA_REL_ "GenSigSuprvResp" BU_SG_REL_ CSM_LS SG_ 2149924864 DSMSS_DrvSelMd6Un 1;
BA_REL_ "GenSigSuprvResp" BU_SG_REL_ RadioHead_LS SG_ 2149924864 DSMSS_DrvSelMd6Un 1;
BA_REL_ "GenSigSuprvResp" BU_SG_REL_ CSM_LS SG_ 2149924864 DSMSS_DrvSelMd5Un 1;
BA_REL_ "GenSigSuprvResp" BU_SG_REL_ RadioHead_LS SG_ 2149924864 DSMSS_DrvSelMd5Un 1;
BA_REL_ "GenSigSuprvResp" BU_SG_REL_ CSM_LS SG_ 2149924864 DSMSS_DrvSelMd4Un 1;
BA_REL_ "GenSigSuprvResp" BU_SG_REL_ RadioHead_LS SG_ 2149924864 DSMSS_DrvSelMd4Un 1;
BA_REL_ "GenSigSuprvResp" BU_SG_REL_ CSM_LS SG_ 2149924864 DSMSS_DrvSelMd3Un 1;
BA_REL_ "GenSigSuprvResp" BU_SG_REL_ RadioHead_LS SG_ 2149924864 DSMSS_DrvSelMd3Un 1;
BA_REL_ "GenSigSuprvResp" BU_SG_REL_ CSM_LS SG_ 2149924864 DSMSS_DrvSelMd2Un 1;
BA_REL_ "GenSigSuprvResp" BU_SG_REL_ RadioHead_LS SG_ 2149924864 DSMSS_DrvSelMd2Un 1;
BA_REL_ "GenSigSuprvResp" BU_SG_REL_ CSM_LS SG_ 2149924864 DSMSS_DrvSelMd1Un 1;
BA_REL_ "GenSigSuprvResp" BU_SG_REL_ RadioHead_LS SG_ 2149924864 DSMSS_DrvSelMd1Un 1;
BA_REL_ "GenSigSuprvResp" BU_SG_REL_ FCM_LS SG_ 2149924864 DrvSelMd3Stat 1;
BA_REL_ "GenSigSuprvResp" BU_SG_REL_ CSM_LS SG_ 2149924864 DrvSelMd3Stat 1;
BA_REL_ "GenSigSuprvResp" BU_SG_REL_ RadioHead_LS SG_ 2149924864 DrvSelMd3Stat 1;
BA_REL_ "GenSigSuprvResp" BU_SG_REL_ ECC_LS SG_ 2149924864 DrvSelMd3Stat 1;
BA_REL_ "GenSigSuprvResp" BU_SG_REL_ FCM_LS SG_ 2149924864 DrvSelMd2Stat 1;
BA_REL_ "GenSigSuprvResp" BU_SG_REL_ CSM_LS SG_ 2149924864 DrvSelMd2Stat 1;
BA_REL_ "GenSigSuprvResp" BU_SG_REL_ RadioHead_LS SG_ 2149924864 DrvSelMd2Stat 1;
BA_REL_ "GenSigSuprvResp" BU_SG_REL_ ECC_LS SG_ 2149924864 DrvSelMd2Stat 1;
BA_REL_ "GenSigSuprvResp" BU_SG_REL_ FCM_LS SG_ 2149924864 DrvSelMd1Stat 1;
BA_REL_ "GenSigSuprvResp" BU_SG_REL_ CSM_LS SG_ 2149924864 DrvSelMd1Stat 1;
BA_REL_ "GenSigSuprvResp" BU_SG_REL_ RadioHead_LS SG_ 2149924864 DrvSelMd1Stat 1;
BA_REL_ "GenSigSuprvResp" BU_SG_REL_ ECC_LS SG_ 2149924864 DrvSelMd1Stat 1;
BA_REL_ "GenSigRxStartValue" BU_SG_REL_ CSM_LS SG_ 2149924864 CPSCA_Resrv3Avail "0";
BA_REL_ "GenSigRxStartValue" BU_SG_REL_ RadioHead_LS SG_ 2149924864 CPSCA_Resrv3Avail "0";
BA_REL_ "GenSigRxStartValue" BU_SG_REL_ CSM_LS SG_ 2149924864 CPSCA_Resrv2Avail "0";
BA_REL_ "GenSigRxStartValue" BU_SG_REL_ RadioHead_LS SG_ 2149924864 CPSCA_Resrv2Avail "0";
BA_REL_ "GenSigRxStartValue" BU_SG_REL_ CSM_LS SG_ 2149924864 CPSCA_Resrv1Avail "0";
BA_REL_ "GenSigRxStartValue" BU_SG_REL_ RadioHead_LS SG_ 2149924864 CPSCA_Resrv1Avail "0";
BA_REL_ "GenSigRxStartValue" BU_SG_REL_ CSM_LS SG_ 2149924864 CPSCA_AlrtBrkStrAvail "0";
BA_REL_ "GenSigRxStartValue" BU_SG_REL_ RadioHead_LS SG_ 2149924864 CPSCA_AlrtBrkStrAvail "0";
BA_REL_ "GenSigRxStartValue" BU_SG_REL_ CSM_LS SG_ 2149924864 CPSCA_AlrtBrkAvail "1";
BA_REL_ "GenSigRxStartValue" BU_SG_REL_ RadioHead_LS SG_ 2149924864 CPSCA_AlrtBrkAvail "1";
BA_REL_ "GenSigRxStartValue" BU_SG_REL_ CSM_LS SG_ 2149924864 CPSCA_AlrtAvail "1";
BA_REL_ "GenSigRxStartValue" BU_SG_REL_ RadioHead_LS SG_ 2149924864 CPSCA_AlrtAvail "1";
BA_REL_ "GenSigRxStartValue" BU_SG_REL_ CSM_LS SG_ 2149924864 CPSCA_OffAvail "1";
BA_REL_ "GenSigRxStartValue" BU_SG_REL_ RadioHead_LS SG_ 2149924864 CPSCA_OffAvail "1";
BA_REL_ "GenSigSuprvResp" BU_SG_REL_ RadioHead_LS SG_ 2152054784 FuelEconMetDispUnts 1;
BA_REL_ "GenSigSuprvResp" BU_SG_REL_ RadioHead_LS SG_ 2152054784 FuelEconMetDispUnts 1;
BA_REL_ "GenSigSuprvResp" BU_SG_REL_ BSM_LS SG_ 2152054784 FuelEconMetDispUnts 1;
BA_REL_ "GenSigSuprvResp" BU_SG_REL_ VICM_LS SG_ 2152054784 FuelEconMetDispUnts 1;
BA_REL_ "GenSigSuprvResp" BU_SG_REL_ MSM_P_LS SG_ 2150563840 PsStStatDispAct 1;
BA_REL_ "GenSigSuprvResp" BU_SG_REL_ MSM_LS SG_ 2150563840 DrStStatDispAct 1;
BA_REL_ "GenSigSuprvResp" BU_SG_REL_ MSM_LR_LS SG_ 2154758144 ChldLckOtSwAct 1;
BA_REL_ "GenSigSuprvResp" BU_SG_REL_ MSM_RR_LS SG_ 2154758144 ChldLckOtSwAct 1;
BA_REL_ "GenSigSuprvResp" BU_SG_REL_ IPC_LS SG_ 2152857600 ACCGrnMdStat 1;
BA_REL_ "GenSigSuprvResp" BU_SG_REL_ IPC_LS SG_ 2152857600 ACCRteSpdAdaptStat 1;
BA_REL_ "GenSigSuprvResp" BU_SG_REL_ IPC_LS SG_ 2152857600 ACCRteSpdDrvIntvReq 1;
BA_REL_ "GenSigSuprvResp" BU_SG_REL_ IPC_LS SG_ 2152857600 ACCTrfcJamAstActStat 1;
BA_REL_ "GenSigSuprvResp" BU_SG_REL_ IPC_LS SG_ 2152857600 ACCTrfcJamAstRmnTm 1;
BA_REL_ "GenSigSuprvResp" BU_SG_REL_ CSM_LS SG_ 2158149632 ECHGCD_XAxTkMrkInterv 1;
BA_REL_ "GenSigSuprvResp" BU_SG_REL_ RadioHead_LS SG_ 2158149632 ECHGCD_XAxTkMrkInterv 1;
BA_REL_ "GenSigSuprvResp" BU_SG_REL_ CSM_LS SG_ 2158149632 ECHGCD_YAxMaxVal 1;
BA_REL_ "GenSigSuprvResp" BU_SG_REL_ RadioHead_LS SG_ 2158149632 ECHGCD_YAxMaxVal 1;
BA_REL_ "GenSigSuprvResp" BU_SG_REL_ CSM_LS SG_ 2158149632 ECHGCD_MeasUt 1;
BA_REL_ "GenSigSuprvResp" BU_SG_REL_ RadioHead_LS SG_ 2158149632 ECHGCD_MeasUt 1;
BA_REL_ "GenSigSuprvResp" BU_SG_REL_ CSM_LS SG_ 2158149632 EgyCnsHstGphInsEgyCns 1;
BA_REL_ "GenSigSuprvResp" BU_SG_REL_ RadioHead_LS SG_ 2158149632 EgyCnsHstGphInsEgyCns 1;
BA_REL_ "GenSigSuprvResp" BU_SG_REL_ CSM_LS SG_ 2158149632 HVBTBSCR_SsnDyStat 1;
BA_REL_ "GenSigSuprvResp" BU_SG_REL_ RadioHead_LS SG_ 2158149632 HVBTBSCR_SsnDyStat 1;
BA_REL_ "GenSigSuprvResp" BU_SG_REL_ RadioHead_LS SG_ 2158149632 HVBTBSCR_SsnDyStat 1;
BA_REL_ "GenSigSuprvResp" BU_SG_REL_ CSM_LS SG_ 2158149632 HVBTBSCR_SsnStat 1;
BA_REL_ "GenSigSuprvResp" BU_SG_REL_ RadioHead_LS SG_ 2158149632 HVBTBSCR_SsnStat 1;
BA_REL_ "GenSigSuprvResp" BU_SG_REL_ RadioHead_LS SG_ 2158149632 HVBTBSCR_SsnStat 1;
BA_REL_ "GenSigSuprvResp" BU_SG_REL_ CSM_LS SG_ 2158149632 HVBTBSCR_SsnSlctStat 1;
BA_REL_ "GenSigSuprvResp" BU_SG_REL_ RadioHead_LS SG_ 2158149632 HVBTBSCR_SsnSlctStat 1;
BA_REL_ "GenSigSuprvResp" BU_SG_REL_ RadioHead_LS SG_ 2158149632 HVBTBSCR_SsnSlctStat 1;
BA_REL_ "GenSigSuprvResp" BU_SG_REL_ CSM_LS SG_ 2158149632 HVBTBSCR_SsnMthStat 1;
BA_REL_ "GenSigSuprvResp" BU_SG_REL_ RadioHead_LS SG_ 2158149632 HVBTBSCR_SsnMthStat 1;
BA_REL_ "GenSigSuprvResp" BU_SG_REL_ RadioHead_LS SG_ 2158149632 HVBTBSCR_SsnMthStat 1;
BA_REL_ "GenSigSuprvResp" BU_SG_REL_ BCM_LS SG_ 2158149632 HVBatTmBsChrgStRsp 1;
BA_REL_ "GenSigSuprvResp" BU_SG_REL_ CSM_LS SG_ 2158149632 HVBatTmBsChrgStRsp 1;
BA_REL_ "GenSigSuprvResp" BU_SG_REL_ RadioHead_LS SG_ 2158149632 HVBatTmBsChrgStRsp 1;
BA_REL_ "GenSigSuprvResp" BU_SG_REL_ RadioHead_LS SG_ 2158149632 HVBatTmBsChrgStRsp 1;
BA_REL_ "GenSigSuprvResp" BU_SG_REL_ CSM_LS SG_ 2158149632 HVBTBCRS_ChRtDStat 1;
BA_REL_ "GenSigSuprvResp" BU_SG_REL_ RadioHead_LS SG_ 2158149632 HVBTBCRS_ChRtDStat 1;
BA_REL_ "GenSigSuprvResp" BU_SG_REL_ RadioHead_LS SG_ 2158149632 HVBTBCRS_ChRtDStat 1;
BA_REL_ "GenSigSuprvResp" BU_SG_REL_ CSM_LS SG_ 2158149632 HVBTBCRS_ChRtSlctStat 1;
BA_REL_ "GenSigSuprvResp" BU_SG_REL_ RadioHead_LS SG_ 2158149632 HVBTBCRS_ChRtSlctStat 1;
BA_REL_ "GenSigSuprvResp" BU_SG_REL_ RadioHead_LS SG_ 2158149632 HVBTBCRS_ChRtSlctStat 1;
BA_REL_ "GenSigSuprvResp" BU_SG_REL_ CSM_LS SG_ 2158149632 HVBTBCRS_ChRtEnblStat 1;
BA_REL_ "GenSigSuprvResp" BU_SG_REL_ RadioHead_LS SG_ 2158149632 HVBTBCRS_ChRtEnblStat 1;
BA_REL_ "GenSigSuprvResp" BU_SG_REL_ RadioHead_LS SG_ 2158149632 HVBTBCRS_ChRtEnblStat 1;
BA_REL_ "GenSigSuprvResp" BU_SG_REL_ CSM_LS SG_ 2158116864 HVBatStrtTmDspFrmt 1;
BA_REL_ "GenSigSuprvResp" BU_SG_REL_ RadioHead_LS SG_ 2158116864 HVBatStrtTmDspFrmt 1;
BA_REL_ "GenSigSuprvResp" BU_SG_REL_ RadioHead_LS SG_ 2158116864 OBHVBCMinsRmng 1;
BA_REL_ "GenSigSuprvResp" BU_SG_REL_ IPC_LS SG_ 2158116864 OBHVBCMinsRmng 1;
BA_REL_ "GenSigSuprvResp" BU_SG_REL_ RadioHead_LS SG_ 2158116864 OBHVBCCompTmDispFrmt 1;
BA_REL_ "GenSigSuprvResp" BU_SG_REL_ IPC_LS SG_ 2158116864 OBHVBCCompTmDispFrmt 1;
BA_REL_ "GenSigSuprvResp" BU_SG_REL_ CSM_LS SG_ 2158116864 HVBTBRCR_RtCHSlctTblRwStat 1;
BA_REL_ "GenSigSuprvResp" BU_SG_REL_ RadioHead_LS SG_ 2158116864 HVBTBRCR_RtCHSlctTblRwStat 1;
BA_REL_ "GenSigSuprvResp" BU_SG_REL_ RadioHead_LS SG_ 2158116864 HVBTBRCR_RtCHSlctTblRwStat 1;
BA_REL_ "GenSigSuprvResp" BU_SG_REL_ CSM_LS SG_ 2158116864 HVBTBRCR_RtChSlctStat 1;
BA_REL_ "GenSigSuprvResp" BU_SG_REL_ RadioHead_LS SG_ 2158116864 HVBTBRCR_RtChSlctStat 1;
BA_REL_ "GenSigSuprvResp" BU_SG_REL_ RadioHead_LS SG_ 2158116864 HVBTBRCR_RtChSlctStat 1;
BA_REL_ "GenSigSuprvResp" BU_SG_REL_ CSM_LS SG_ 2158116864 HVBTBRCR_RtChSlRtStat 1;
BA_REL_ "GenSigSuprvResp" BU_SG_REL_ RadioHead_LS SG_ 2158116864 HVBTBRCR_RtChSlRtStat 1;
BA_REL_ "GenSigSuprvResp" BU_SG_REL_ RadioHead_LS SG_ 2158116864 HVBTBRCR_RtChSlRtStat 1;
BA_REL_ "GenSigSuprvResp" BU_SG_REL_ CSM_LS SG_ 2158116864 HVBTBRCR_RtChSsnStat 1;
BA_REL_ "GenSigSuprvResp" BU_SG_REL_ RadioHead_LS SG_ 2158116864 HVBTBRCR_RtChSsnStat 1;
BA_REL_ "GenSigSuprvResp" BU_SG_REL_ RadioHead_LS SG_ 2158116864 HVBTBRCR_RtChSsnStat 1;
BA_REL_ "GenSigSuprvResp" BU_SG_REL_ CSM_LS SG_ 2158116864 HVBTBRCR_RtChMHRsp 1;
BA_REL_ "GenSigSuprvResp" BU_SG_REL_ RadioHead_LS SG_ 2158116864 HVBTBRCR_RtChMHRsp 1;
BA_REL_ "GenSigSuprvResp" BU_SG_REL_ RadioHead_LS SG_ 2158116864 HVBTBRCR_RtChMHRsp 1;
BA_REL_ "GenSigSuprvResp" BU_SG_REL_ CSM_LS SG_ 2158116864 HVBTBRCR_RtChHRsp 1;
BA_REL_ "GenSigSuprvResp" BU_SG_REL_ RadioHead_LS SG_ 2158116864 HVBTBRCR_RtChHRsp 1;
BA_REL_ "GenSigSuprvResp" BU_SG_REL_ RadioHead_LS SG_ 2158116864 HVBTBRCR_RtChHRsp 1;
BA_REL_ "GenSigSuprvResp" BU_SG_REL_ CSM_LS SG_ 2158116864 HVBTBRCR_RtChDStat 1;
BA_REL_ "GenSigSuprvResp" BU_SG_REL_ RadioHead_LS SG_ 2158116864 HVBTBRCR_RtChDStat 1;
BA_REL_ "GenSigSuprvResp" BU_SG_REL_ RadioHead_LS SG_ 2158116864 HVBTBRCR_RtChDStat 1;
BA_REL_ "GenSigSuprvResp" BU_SG_REL_ BCM_LS SG_ 2158116864 HVBTBDCRS_DlChSlctStat 1;
BA_REL_ "GenSigSuprvResp" BU_SG_REL_ CSM_LS SG_ 2158116864 HVBTBDCRS_DlChSlctStat 1;
BA_REL_ "GenSigSuprvResp" BU_SG_REL_ RadioHead_LS SG_ 2158116864 HVBTBDCRS_DlChSlctStat 1;
BA_REL_ "GenSigSuprvResp" BU_SG_REL_ RadioHead_LS SG_ 2158116864 HVBTBDCRS_DlChSlctStat 1;
BA_REL_ "GenSigSuprvResp" BU_SG_REL_ BCM_LS SG_ 2158116864 HVBTBDCRS_DlChSsnStat 1;
BA_REL_ "GenSigSuprvResp" BU_SG_REL_ CSM_LS SG_ 2158116864 HVBTBDCRS_DlChSsnStat 1;
BA_REL_ "GenSigSuprvResp" BU_SG_REL_ RadioHead_LS SG_ 2158116864 HVBTBDCRS_DlChSsnStat 1;
BA_REL_ "GenSigSuprvResp" BU_SG_REL_ RadioHead_LS SG_ 2158116864 HVBTBDCRS_DlChSsnStat 1;
BA_REL_ "GenSigSuprvResp" BU_SG_REL_ BCM_LS SG_ 2158116864 HVBTBDCRS_DlChMHRsp 1;
BA_REL_ "GenSigSuprvResp" BU_SG_REL_ CSM_LS SG_ 2158116864 HVBTBDCRS_DlChMHRsp 1;
BA_REL_ "GenSigSuprvResp" BU_SG_REL_ RadioHead_LS SG_ 2158116864 HVBTBDCRS_DlChMHRsp 1;
BA_REL_ "GenSigSuprvResp" BU_SG_REL_ RadioHead_LS SG_ 2158116864 HVBTBDCRS_DlChMHRsp 1;
BA_REL_ "GenSigSuprvResp" BU_SG_REL_ BCM_LS SG_ 2158116864 HVBTBDCRS_DlChHRsp 1;
BA_REL_ "GenSigSuprvResp" BU_SG_REL_ CSM_LS SG_ 2158116864 HVBTBDCRS_DlChHRsp 1;
BA_REL_ "GenSigSuprvResp" BU_SG_REL_ RadioHead_LS SG_ 2158116864 HVBTBDCRS_DlChHRsp 1;
BA_REL_ "GenSigSuprvResp" BU_SG_REL_ RadioHead_LS SG_ 2158116864 HVBTBDCRS_DlChHRsp 1;
BA_REL_ "GenSigSuprvResp" BU_SG_REL_ BCM_LS SG_ 2158116864 HVBTBDCRS_DlChDStat 1;
BA_REL_ "GenSigSuprvResp" BU_SG_REL_ CSM_LS SG_ 2158116864 HVBTBDCRS_DlChDStat 1;
BA_REL_ "GenSigSuprvResp" BU_SG_REL_ RadioHead_LS SG_ 2158116864 HVBTBDCRS_DlChDStat 1;
BA_REL_ "GenSigSuprvResp" BU_SG_REL_ RadioHead_LS SG_ 2158116864 HVBTBDCRS_DlChDStat 1;
BA_REL_ "GenSigSuprvResp" BU_SG_REL_ BSM_LS SG_ 2156281856 TONPDTR_StTmpOvrAtv 1;
BA_REL_ "GenSigSuprvResp" BU_SG_REL_ VICM_LS SG_ 2156281856 TONPDTR_StTmpOvrAtv 1;
BA_REL_ "GenSigSuprvResp" BU_SG_REL_ BSM_LS SG_ 2156281856 TONPDTR_MntOfHr 1;
BA_REL_ "GenSigSuprvResp" BU_SG_REL_ VICM_LS SG_ 2156281856 TONPDTR_MntOfHr 1;
BA_REL_ "GenSigSuprvResp" BU_SG_REL_ BSM_LS SG_ 2156281856 TONPDTR_HrOfDy 1;
BA_REL_ "GenSigSuprvResp" BU_SG_REL_ VICM_LS SG_ 2156281856 TONPDTR_HrOfDy 1;
BA_REL_ "GenSigSuprvResp" BU_SG_REL_ BSM_LS SG_ 2156281856 TONPDTR_DyOfWk 1;
BA_REL_ "GenSigSuprvResp" BU_SG_REL_ VICM_LS SG_ 2156281856 TONPDTR_DyOfWk 1;
BA_REL_ "GenSigSuprvResp" BU_SG_REL_ BSM_LS SG_ 2156265472 EngyUsgScrnMeasUtStat 1;
BA_REL_ "GenSigSuprvResp" BU_SG_REL_ VICM_LS SG_ 2156265472 EngyUsgScrnMeasUtStat 1;
BA_REL_ "GenSigSuprvResp" BU_SG_REL_ BSM_LS SG_ 2156265472 ChgPwLsAlCzStRq 1;
BA_REL_ "GenSigSuprvResp" BU_SG_REL_ VICM_LS SG_ 2156265472 ChgPwLsAlCzStRq 1;
BA_REL_ "GenSigSuprvResp" BU_SG_REL_ BSM_LS SG_ 2156265472 ChgCdTfAlCzStRq 1;
BA_REL_ "GenSigSuprvResp" BU_SG_REL_ VICM_LS SG_ 2156265472 ChgCdTfAlCzStRq 1;
BA_REL_ "GenSigSuprvResp" BU_SG_REL_ IPC_LS SG_ 2150113280 HVChrgInhbRsn 1;
BA_REL_ "GenSigSuprvResp" BU_SG_REL_ IPC_LS SG_ 2150113280 DrvCyclTrpDstTrvld 1;
BA_REL_ "GenSigSuprvResp" BU_SG_REL_ IPC_LS SG_ 2150113280 DrvCyclElecEngyEcon 1;
BA_REL_ "GenSigSuprvResp" BU_SG_REL_ CSM_LS SG_ 2150113280 DrvCycElEnrgUsd 1;
BA_REL_ "GenSigSuprvResp" BU_SG_REL_ RadioHead_LS SG_ 2150113280 DrvCycElEnrgUsd 1;
BA_REL_ "GenSigSuprvResp" BU_SG_REL_ RadioHead_LS SG_ 2150113280 DrvCycElEnrgUsd 1;
BA_REL_ "GenSigSuprvResp" BU_SG_REL_ ECC_LS SG_ 2150055936 ClmCntCmpPwrUsdClc 1;
BA_REL_ "GenSigSuprvResp" BU_SG_REL_ ECC_LS SG_ 2150039552 EvpCorOtltAirTmpCalcd 1;
BA_REL_ "GenSigSuprvResp" BU_SG_REL_ BSM_LS SG_ 2154856448 HmdtySnsrTemp 1;
BA_REL_ "GenSigSuprvResp" BU_SG_REL_ VICM_LS SG_ 2154856448 HmdtySnsrTemp 1;
BA_REL_ "GenSigSuprvResp" BU_SG_REL_ BSM_LS SG_ 2154856448 HmdtySnsrRltvHmdty 1;
BA_REL_ "GenSigSuprvResp" BU_SG_REL_ VICM_LS SG_ 2154856448 HmdtySnsrRltvHmdty 1;
BA_REL_ "GenSigSuprvResp" BU_SG_REL_ IPC_LS SG_ 2151342080 PrkAstRtSysStat 1;
BA_REL_ "GenSigSuprvResp" BU_SG_REL_ IPC_LS SG_ 2151342080 PARtRgn3ObjStat 1;
BA_REL_ "GenSigSuprvResp" BU_SG_REL_ IPC_LS SG_ 2151342080 PARtRgn2ObjStat 1;
BA_REL_ "GenSigSuprvResp" BU_SG_REL_ IPC_LS SG_ 2151342080 PARtRgn1ObjStat 1;
BA_REL_ "GenSigSuprvResp" BU_SG_REL_ IPC_LS SG_ 2151325696 PrkAstLtSysStat 1;
BA_REL_ "GenSigSuprvResp" BU_SG_REL_ IPC_LS SG_ 2151325696 PALtRgn3ObjStat 1;
BA_REL_ "GenSigSuprvResp" BU_SG_REL_ IPC_LS SG_ 2151325696 PALtRgn2ObjStat 1;
BA_REL_ "GenSigSuprvResp" BU_SG_REL_ IPC_LS SG_ 2151325696 PALtRgn1ObjStat 1;
BA_REL_ "GenSigSuprvResp" BU_SG_REL_ IPC_LS SG_ 2151809024 ElecEngyEconAvg 1;
BA_REL_ "GenSigSuprvResp" BU_SG_REL_ CSM_LS SG_ 2151809024 DrvCycElecEngySt5 1;
BA_REL_ "GenSigSuprvResp" BU_SG_REL_ RadioHead_LS SG_ 2151809024 DrvCycElecEngySt5 1;
BA_REL_ "GenSigSuprvResp" BU_SG_REL_ CSM_LS SG_ 2151809024 DCEEC_EngyPct4 1;
BA_REL_ "GenSigSuprvResp" BU_SG_REL_ RadioHead_LS SG_ 2151809024 DCEEC_EngyPct4 1;
BA_REL_ "GenSigSuprvResp" BU_SG_REL_ CSM_LS SG_ 2151809024 DCEEC_EngyPct3 1;
BA_REL_ "GenSigSuprvResp" BU_SG_REL_ RadioHead_LS SG_ 2151809024 DCEEC_EngyPct3 1;
BA_REL_ "GenSigSuprvResp" BU_SG_REL_ CSM_LS SG_ 2151809024 DCEEC_EngyPct2 1;
BA_REL_ "GenSigSuprvResp" BU_SG_REL_ RadioHead_LS SG_ 2151809024 DCEEC_EngyPct2 1;
BA_REL_ "GenSigSuprvResp" BU_SG_REL_ CSM_LS SG_ 2151809024 DCEEC_EngyPct1 1;
BA_REL_ "GenSigSuprvResp" BU_SG_REL_ RadioHead_LS SG_ 2151809024 DCEEC_EngyPct1 1;
BA_REL_ "GenSigSuprvResp" BU_SG_REL_ CSM_LS SG_ 2151858176 DrvCycElecEngySt4 1;
BA_REL_ "GenSigSuprvResp" BU_SG_REL_ RadioHead_LS SG_ 2151858176 DrvCycElecEngySt4 1;
BA_REL_ "GenSigSuprvResp" BU_SG_REL_ CSM_LS SG_ 2151858176 DrvCycElecEngySt3 1;
BA_REL_ "GenSigSuprvResp" BU_SG_REL_ RadioHead_LS SG_ 2151858176 DrvCycElecEngySt3 1;
BA_REL_ "GenSigSuprvResp" BU_SG_REL_ CSM_LS SG_ 2151858176 DrvCycElecEngySt2 1;
BA_REL_ "GenSigSuprvResp" BU_SG_REL_ RadioHead_LS SG_ 2151858176 DrvCycElecEngySt2 1;
BA_REL_ "GenSigSuprvResp" BU_SG_REL_ CSM_LS SG_ 2151858176 DrvCycElecEngySt1 1;
BA_REL_ "GenSigSuprvResp" BU_SG_REL_ RadioHead_LS SG_ 2151858176 DrvCycElecEngySt1 1;
BA_REL_ "GenSigSuprvResp" BU_SG_REL_ IPC_LS SG_ 2150547456 HVDpltnMdCnfdcTrndg 1;
BA_REL_ "GenSigSuprvResp" BU_SG_REL_ CSM_LS SG_ 2150547456 OffBrdHVCVehPwrLvl 1;
BA_REL_ "GenSigSuprvResp" BU_SG_REL_ RadioHead_LS SG_ 2150547456 OffBrdHVCVehPwrLvl 1;
BA_REL_ "GenSigSuprvResp" BU_SG_REL_ CSM_LS SG_ 2150547456 OffBrdHVCVehPwrDrtd 1;
BA_REL_ "GenSigSuprvResp" BU_SG_REL_ RadioHead_LS SG_ 2150547456 OffBrdHVCVehPwrDrtd 1;
BA_REL_ "GenSigSuprvResp" BU_SG_REL_ CSM_LS SG_ 2150547456 OffBrdHVCVehCplrLkd 1;
BA_REL_ "GenSigSuprvResp" BU_SG_REL_ RadioHead_LS SG_ 2150547456 OffBrdHVCVehCplrLkd 1;
BA_REL_ "GenSigSuprvResp" BU_SG_REL_ IPC_LS SG_ 2150547456 OffBrdHVBlkChrgCmp 1;
BA_REL_ "GenSigSuprvResp" BU_SG_REL_ IPC_LS SG_ 2150547456 OBHVBCCT_MinofHr 1;
BA_REL_ "GenSigSuprvResp" BU_SG_REL_ CSM_LS SG_ 2150547456 OBHVBCCT_MinofHr 1;
BA_REL_ "GenSigSuprvResp" BU_SG_REL_ RadioHead_LS SG_ 2150547456 OBHVBCCT_MinofHr 1;
BA_REL_ "GenSigSuprvResp" BU_SG_REL_ IPC_LS SG_ 2150547456 OBHVBCCT_HrofDay 1;
BA_REL_ "GenSigSuprvResp" BU_SG_REL_ CSM_LS SG_ 2150547456 OBHVBCCT_HrofDay 1;
BA_REL_ "GenSigSuprvResp" BU_SG_REL_ RadioHead_LS SG_ 2150547456 OBHVBCCT_HrofDay 1;
BA_REL_ "GenSigSuprvResp" BU_SG_REL_ IPC_LS SG_ 2150547456 OBHVBCCT_DayofWk 1;
BA_REL_ "GenSigSuprvResp" BU_SG_REL_ CSM_LS SG_ 2150547456 OBHVBCCT_DayofWk 1;
BA_REL_ "GenSigSuprvResp" BU_SG_REL_ RadioHead_LS SG_ 2150547456 OBHVBCCT_DayofWk 1;
BA_REL_ "GenSigSuprvResp" BU_SG_REL_ IPC_LS SG_ 2150547456 ElecPrplsnMtrOvrSpdIO 1;
BA_REL_ "GenSigSuprvResp" BU_SG_REL_ IPC_LS SG_ 2150547456 HVBatCntctrsOpnIO 1;
BA_REL_ "GenSigSuprvResp" BU_SG_REL_ BCM_LS SG_ 2150547456 HVBatChrgCrdConnIO 1;
BA_REL_ "GenSigSuprvResp" BU_SG_REL_ TCP_LS SG_ 2150547456 HVBatChrgCrdConnIO 1;
BA_REL_ "GenSigSuprvResp" BU_SG_REL_ CSM_LS SG_ 2150547456 HVDpltnMdRng 1;
BA_REL_ "GenSigSuprvResp" BU_SG_REL_ RadioHead_LS SG_ 2150547456 HVDpltnMdRng 1;
BA_REL_ "GenSigSuprvResp" BU_SG_REL_ RadioHead_LS SG_ 2150547456 HVDpltnMdRng 1;
BA_REL_ "GenSigSuprvResp" BU_SG_REL_ IPC_LS SG_ 2151489536 NVSysStat 1;
BA_REL_ "GenSigSuprvResp" BU_SG_REL_ CSM_LS SG_ 2149761024 PsngStPerfMdCsCrStVal 1;
BA_REL_ "GenSigSuprvResp" BU_SG_REL_ RadioHead_LS SG_ 2149761024 PsngStPerfMdCsCrStVal 1;
BA_REL_ "GenSigSuprvResp" BU_SG_REL_ CSM_LS SG_ 2149761024 PsngStPerfMdCsStAvl 1;
BA_REL_ "GenSigSuprvResp" BU_SG_REL_ RadioHead_LS SG_ 2149761024 PsngStPerfMdCsStAvl 1;
BA_REL_ "GenSigSuprvResp" BU_SG_REL_ IPC_LS SG_ 2149761024 ElvtdIdlCstCrStVal 1;
BA_REL_ "GenSigSuprvResp" BU_SG_REL_ IPC_LS SG_ 2149761024 TCTPIR_TnsEsClCDwT 1;
BA_REL_ "GenSigSuprvResp" BU_SG_REL_ IPC_LS SG_ 2149761024 TCTPIR_TnsEsClTmpD 1;
BA_REL_ "GenSigSuprvResp" BU_SG_REL_ IPC_LS SG_ 2149761024 TCTPIR_DrvNotfn 1;
BA_REL_ "GenSigRxStartValue" BU_SG_REL_ IPC_LS SG_ 2149761024 TrlrStabAstActIO "0";
BA_REL_ "GenSigSuprvResp" BU_SG_REL_ STC_LS SG_ 2149761024 ActVehAccel 1;
BA_REL_ "GenSigSuprvResp" BU_SG_REL_ FCM_LS SG_ 2149761024 ActVehAccel 1;
BA_REL_ "GenSigSuprvResp" BU_SG_REL_ IPC_LS SG_ 2149761024 ActVehAccel 1;
BA_REL_ "GenSigSuprvResp" BU_SG_REL_ BCM_LS SG_ 2150514688 SldngDrRgtStat 1;
BA_REL_ "GenSigSuprvResp" BU_SG_REL_ BCM_LS SG_ 2150514688 SldngDrRgtStat 1;
BA_REL_ "GenSigSuprvResp" BU_SG_REL_ BCM_LS SG_ 2150514688 SldngDrLftStat 1;
BA_REL_ "GenSigSuprvResp" BU_SG_REL_ BCM_LS SG_ 2150514688 SldngDrLftStat 1;
BA_REL_ "GenSigSuprvResp" BU_SG_REL_ BCM_LS SG_ 2150514688 SdClsrObstclDtctdStat 1;
VAL_ 2156298240 HTRActvIndOn 1 "true" 0 "false" ;
VAL_ 2156298240 HVBSTLPC_DyOfWk 0 "Unknown" 1 "Sunday" 2 "Monday" 3 "Tuesday" 4 "Wednesday" 5 "Thursday" 6 "Friday" 7 "Saturday" ;
VAL_ 2156298240 HVBSTHPC_DyOfWk 0 "Unknown" 1 "Sunday" 2 "Monday" 3 "Tuesday" 4 "Wednesday" 5 "Thursday" 6 "Friday" 7 "Saturday" ;
VAL_ 2156298240 HVBCTLPC_DyOfWk 0 "Unknown" 1 "Sunday" 2 "Monday" 3 "Tuesday" 4 "Wednesday" 5 "Thursday" 6 "Friday" 7 "Saturday" ;
VAL_ 2156298240 HVBCTHPC_DyOfWk 0 "Unknown" 1 "Sunday" 2 "Monday" 3 "Tuesday" 4 "Wednesday" 5 "Thursday" 6 "Friday" 7 "Saturday" ;
VAL_ 2156298240 InvldHMIEtrIO 1 "true" 0 "false" ;
VAL_ 2156298240 InsfcntTmTFlChrgIO 1 "true" 0 "false" ;
VAL_ 2156298240 HVBatChrgCrdAlrtReq 0 "None" 1 "Pedestrian" 2 "Theft" ;
VAL_ 2156298240 HVCSDTES_NPDTIO 1 "true" 0 "false" ;
VAL_ 2156298240 HVCSDTES_LoPwrCIO 1 "true" 0 "false" ;
VAL_ 2156298240 HVCSDTES_HiPwrCIO 1 "true" 0 "false" ;
VAL_ 2149924864 PTOMobModTrnsInGrIO 1 "true" 0 "false" ;
VAL_ 2149924864 a_12VBatSysUnstab 1 "true" 0 "false" ;
VAL_ 2149924864 FwdClnMtgnBrkReqAct 1 "true" 0 "false" ;
VAL_ 2149924864 TireRRLowTracIO 1 "true" 0 "false" ;
VAL_ 2149924864 TireRFLowTracIO 1 "true" 0 "false" ;
VAL_ 2149924864 TireLRLowTracIO 1 "true" 0 "false" ;
VAL_ 2149924864 TireLFLowTracIO 1 "true" 0 "false" ;
VAL_ 2149924864 HilRlbkCtrlActIO 1 "true" 0 "false" ;
VAL_ 2149924864 FstIdlMdAct 1 "true" 0 "false" ;
VAL_ 2149924864 DsplyPerfMdRq 7 "Performance Mode 7" 6 "Performance Mode 6" 5 "Performance Mode 5" 4 "Performance Mode 4" 3 "Performance Mode 3" 2 "Performance Mode 2" 1 "Performance Mode 1" 0 "No Action" ;
VAL_ 2149924864 DrvSelMd8Stat 1 "Active" 0 "Inactive" ;
VAL_ 2149924864 DrvSelMd8ReqDnd 1 "true" 0 "false" ;
VAL_ 2149924864 DrvSelMd7Stat 1 "Active" 0 "Inactive" ;
VAL_ 2149924864 DrvSelMd7ReqDnd 1 "true" 0 "false" ;
VAL_ 2149924864 DrvSelMd6Stat 1 "Active" 0 "Inactive" ;
VAL_ 2149924864 DrvSelMd6ReqDnd 1 "true" 0 "false" ;
VAL_ 2149924864 DrvSelMd5Stat 1 "Active" 0 "Inactive" ;
VAL_ 2149924864 DrvSelMd5ReqDnd 1 "true" 0 "false" ;
VAL_ 2149924864 DrvSelMd4Stat 1 "Active" 0 "Inactive" ;
VAL_ 2149924864 DrvSelMd4ReqDnd 1 "true" 0 "false" ;
VAL_ 2149924864 EDADS_RcmndtFwdGr 15 "Unused and Reserved 7" 14 "Unused and Reserved 6" 13 "Unused and Reserved 5" 12 "Unused and Reserved 4" 11 "Unused and Reserved 3" 10 "Tenth Gear" 9 "Ninth Gear" 8 "Eighth Gear" 7 "Seventh Gear" 6 "Sixth Gear" 5 "Fifth Gear" 4 "Fourth Gear" 3 "Third Gear" 2 "Second Gear" 1 "First Gear" 0 "None" ;
VAL_ 2149924864 EDADS_CrntFwdMsdG 15 "Unused and Reserved 7" 14 "Unused and Reserved 6" 13 "Unused and Reserved 5" 12 "Unused and Reserved 4" 11 "Unused and Reserved 3" 10 "Tenth Gear" 9 "Ninth Gear" 8 "Eighth Gear" 7 "Seventh Gear" 6 "Sixth Gear" 5 "Fifth Gear" 4 "Fourth Gear" 3 "Third Gear" 2 "Second Gear" 1 "First Gear" 0 "None" ;
VAL_ 2149924864 EDADS_ShftIndStat 2 "No Shift" 1 "Shift Up" 0 "Shift Down" ;
VAL_ 2149924864 EDADS_EcoDrvShftIO 1 "true" 0 "false" ;
VAL_ 2149924864 DSMSS_DrvSelMd0Pn 1 "true" 0 "false" ;
VAL_ 2149924864 DSMSS_DrvSelMd8Pn 1 "true" 0 "false" ;
VAL_ 2149924864 DSMSS_DrvSelMd7Pn 1 "true" 0 "false" ;
VAL_ 2149924864 DSMSS_DrvSelMd6Pn 1 "true" 0 "false" ;
VAL_ 2149924864 DSMSS_DrvSelMd5Pn 1 "true" 0 "false" ;
VAL_ 2149924864 DSMSS_DrvSelMd4Pn 1 "true" 0 "false" ;
VAL_ 2149924864 DSMSS_DrvSelMd3Pn 1 "true" 0 "false" ;
VAL_ 2149924864 DSMSS_DrvSelMd2Pn 1 "true" 0 "false" ;
VAL_ 2149924864 DSMSS_DrvSelMd1Pn 1 "true" 0 "false" ;
VAL_ 2149924864 DSMSS_DrvSelMd8Un 1 "true" 0 "false" ;
VAL_ 2149924864 DSMSS_DrvSelMd7Un 1 "true" 0 "false" ;
VAL_ 2149924864 DSMSS_DrvSelMd6Un 1 "true" 0 "false" ;
VAL_ 2149924864 DSMSS_DrvSelMd5Un 1 "true" 0 "false" ;
VAL_ 2149924864 DSMSS_DrvSelMd4Un 1 "true" 0 "false" ;
VAL_ 2149924864 DSMSS_DrvSelMd3Un 1 "true" 0 "false" ;
VAL_ 2149924864 DSMSS_DrvSelMd2Un 1 "true" 0 "false" ;
VAL_ 2149924864 DSMSS_DrvSelMd1Un 1 "true" 0 "false" ;
VAL_ 2149924864 DrvSelMd3Stat 1 "Active" 0 "Inactive" ;
VAL_ 2149924864 DrvSelMd3ReqDnd 1 "true" 0 "false" ;
VAL_ 2149924864 DrvSelMd2Stat 1 "Active" 0 "Inactive" ;
VAL_ 2149924864 DrvSelMd2ReqDnd 1 "true" 0 "false" ;
VAL_ 2149924864 DrvSelMd1Stat 1 "Active" 0 "Inactive" ;
VAL_ 2149924864 DrvSelMd1ReqDnd 1 "true" 0 "false" ;
VAL_ 2149924864 CPSCA_Resrv3Avail 1 "true" 0 "false" ;
VAL_ 2149924864 CPSCA_Resrv2Avail 1 "true" 0 "false" ;
VAL_ 2149924864 CPSCA_Resrv1Avail 1 "true" 0 "false" ;
VAL_ 2149924864 CPSCA_AlrtBrkStrAvail 1 "true" 0 "false" ;
VAL_ 2149924864 CPSCA_AlrtBrkAvail 1 "true" 0 "false" ;
VAL_ 2149924864 CPSCA_AlrtAvail 1 "true" 0 "false" ;
VAL_ 2149924864 CPSCA_OffAvail 1 "true" 0 "false" ;
VAL_ 2152054784 FuelEconMetDispUnts 0 "Kilometers per liter" 1 "Liters per 100 km" ;
VAL_ 2152054784 IntPnlClstrAnmtStat 0 "Animation Not Available" 1 "Animation Available" 2 "Welcome Active" 3 "CRANK Active" 4 "RUN Active" 5 "Good Bye Active" ;
VAL_ 2152054784 AnmStrtReq 0 "No Action" 1 "Welcome" 2 "CRANK" 3 "RUN" 4 "Good Bye" ;
VAL_ 2150301696 WlcAnmReq 1 "true" 0 "false" ;
VAL_ 2150563840 PsStStatDispAct 1 "true" 0 "false" ;
VAL_ 2150563840 DrStStatDispAct 1 "true" 0 "false" ;
VAL_ 2150563840 RadAudQueStat 0 "Audio Queue NOT Available" 1 "Audio Queue Available" 2 "Welcome Active" 3 "CRANK Active" 4 "RUN Active" 5 "Good Bye Active" 6 "Reserved" 7 "Green Queue Active" ;
VAL_ 2150563840 RadAnmtStat 0 "Animation Not Available" 1 "Animation Available" 2 "Welcome Active" 3 "CRANK Active" 4 "RUN Active" 5 "Good Bye Active" ;
VAL_ 2154758144 ChldLckOtSwAct 1 "true" 0 "false" ;
VAL_ 2154577920 ASS_DSPMd7Prsnt 1 "true" 0 "false" ;
VAL_ 2154577920 ASS_DSPMd6Prsnt 1 "true" 0 "false" ;
VAL_ 2154577920 ASS_DSPMd5Prsnt 1 "true" 0 "false" ;
VAL_ 2154577920 ASS_DSPMd4Prsnt 1 "true" 0 "false" ;
VAL_ 2154577920 ASS_DSPMd3Prsnt 1 "true" 0 "false" ;
VAL_ 2154577920 ASS_DSPMd2Prsnt 1 "true" 0 "false" ;
VAL_ 2154577920 ASS_DSPMd1Prsnt 1 "true" 0 "false" ;
VAL_ 2154577920 ASS_DSPMd0Prsnt 1 "true" 0 "false" ;
VAL_ 2154577920 ASS_SurndAvail 1 "true" 0 "false" ;
VAL_ 2154577920 ASS_DSPAvail 1 "true" 0 "false" ;
VAL_ 2154577920 ASS_VehNoisCmpnAvail 1 "true" 0 "false" ;
VAL_ 2154577920 ASS_PhLckdLpLckd 1 "true" 0 "false" ;
VAL_ 2154577920 ASS_MtxSnkMutStat 1 "true" 0 "false" ;
VAL_ 2154594304 InfotnBkltngConfigSt 2 "LOCAL" 1 "ON" 0 "OFF" ;
VAL_ 2154594304 ASTC_GblAudSnkMut 1 "true" 0 "false" ;
VAL_ 2154594304 ASTC_AmpLwPwrSt 1 "true" 0 "false" ;
VAL_ 2154594304 ASTC_MtxSnkMut 1 "true" 0 "false" ;
VAL_ 2154594304 ASTC_DSPMd 15 "Unused and Reserved 7" 14 "Unused and Reserved 6" 13 "Unused and Reserved 5" 12 "Unused and Reserved 4" 11 "Unused and Reserved 3" 10 "Unused and Reserved 2" 9 "Unused and Reserved 1" 8 "DSP Mode 7" 7 "DSP Mode 6" 6 "DSP Mode 5" 5 "DSP Mode 4" 4 "DSP Mode 3" 3 "DSP Mode 2" 2 "DSP Mode 1" 1 "DSP Mode 0" 0 "No Action" ;
VAL_ 2154594304 ASTC_VehNoisCmpnAct 1 "true" 0 "false" ;
VAL_ 2154594304 ASTC_ChimSnkSpkrPos 15 "Unused and Reserved 7" 14 "Unused and Reserved 6" 13 "Unused and Reserved 5" 12 "Unused and Reserved 4" 11 "Unused and Reserved 3" 10 "Unused and Reserved 2" 9 "Unused and Reserved 1" 8 "Left Rear" 7 "Left Front" 6 "Right Rear" 5 "Right Front" 4 "Full Right" 3 "Full Left" 2 "Full Rear" 1 "Full Front" 0 "No Action" ;
VAL_ 2154586112 ASSLC_AutoLdnsCmpnAct 1 "true" 0 "false" ;
VAL_ 2154586112 ASSLC_VcSrcActOnMtx 1 "true" 0 "false" ;
VAL_ 2152857600 ACCGrnMdStat 0 "Not Active" 1 "Ready to Assist" 2 "(Curve / Urban / Slope) Active" 3 "Temporarily not Available" ;
VAL_ 2152857600 ACCRteSpdAdaptStat 0 "Not Active" 1 "Ready to Assist" 2 "Active" 3 "Temporarily not Available" ;
VAL_ 2152857600 ACCRteSpdDrvIntvReq 0 "No Indication" 1 "Indication Level 1" 2 "Indication Level 2" 3 "Indication Level 3" ;
VAL_ 2152857600 ACCTrfcJamAstActStat 0 "Not Active" 1 "Timer Elapsed" 2 "Timer Active" 3 "Timer Retriggered" 4 "Timer Canceled" 5 "Temporarily Not Available" 6 "Traffic Jam Assist Failed" 7 "Vehicle Auto Go Notification" ;
VAL_ 2158149632 ECHGCD_XAxTkMrkInterv 7 "100" 6 "80" 5 "50" 4 "20" 3 "10" 2 "5" 1 "1" 0 "0.5" ;
VAL_ 2158149632 ECHGCD_MeasUt 15 "Unused and Reserved 7" 14 "Unused and Reserved 6" 13 "Unused and Reserved 5" 12 "Unused and Reserved 4" 11 "Unused and Reserved 3" 10 "Unused and Reserved 2" 9 "Unused and  Reserved 1" 8 "km per L e Combined" 7 "L per 100km e Combined" 6 "MPGe Combined" 5 "L per 100km" 4 "mi per gal" 3 "km per L" 2 "kWh per 100km" 1 "mi per kWh" 0 "km per kWh" ;
VAL_ 2158149632 HVBTBSCR_SsnStat 3 "Yearly" 0 "No Action" 1 "Summer" 2 "Winter" ;
VAL_ 2158149632 HVBTBSCR_SsnSlctStat 0 "No Action" 1 "Selected Season" 2 "Start Season" 3 "End Season" ;
VAL_ 2158149632 HVBTBSCR_SsnMthStat 0 "No Action" 1 "January" 2 "February" 3 "Mars" 4 "April" 5 "May" 6 "June" 7 "July" 8 "August" 9 "September" 10 "October" 11 "November" 12 "December" ;
VAL_ 2158149632 HVBatTmBsChrgStRsp 0 "No Action" 1 "Charge Now" 2 "Delayed Charge" 3 "Rate Based Charge" ;
VAL_ 2158149632 HVBTBCRS_ChRtDStat 0 "No Action" 1 "Sunday" 2 "Monday" 3 "Tuesday" 4 "Wednsday" 5 "Thursday" 6 "Friday" 7 "Saturday" 8 "All Days Same" 9 "Mon - Fri Same" 10 "Sat & Sun Same" ;
VAL_ 2158149632 HVBTBCRS_ChRtSlctStat 0 "No Action" 1 "Low Rate" 2 "Medium Rate" 3 "High Rate" ;
VAL_ 2158149632 HVBTBCRS_ChRtEnblStat 0 "No Action" 1 "Enabled" 2 "Disabled" ;
VAL_ 2158149632 HVBatCrgDspStat 0 "Inactive" 1 "Pending" 2 "Active Charging" 3 "Complete" 4 "Faulted" ;
VAL_ 2158116864 SrvcHghVltBatIndReq 3 "Unused and Reserved 1" 2 "No Restart" 1 "Shut Down Soon" 0 "No Indication" ;
VAL_ 2158116864 ChrgStPkInScnActIO 1 "true" 0 "false" ;
VAL_ 2158116864 HVBatStrtTmDspFrmt 4 "Display Start Time On Cord And Station" 3 "Display Now On Cord And Station" 2 "Display Now On Station Only" 1 "Display Now On Cord Only" 0 "No Action" ;
VAL_ 2158116864 OBHVBCCompTmDispFrmt 2 "Display Remaining Minutes To Complete" 1 "Display Completion Time" 0 "No Action" ;
VAL_ 2158116864 HVBTBRCR_RtChSlctStat 0 "No Action" 1 "Charge Start" 2 "Charge End" 3 "Charge Start Invalid" 4 "Charge End Invalid" ;
VAL_ 2158116864 HVBTBRCR_RtChSlRtStat 0 "No Action" 1 "Low Rate" 2 "Medium Rate" 3 "High Rate" 4 "Reserved 1" 5 "Invalid Rate" ;
VAL_ 2158116864 HVBTBRCR_RtChSsnStat 3 "Yearly" 0 "No Action" 1 "Summer" 2 "Winter" ;
VAL_ 2158116864 HVBTBRCR_RtChDStat 0 "No Action" 1 "Sunday" 2 "Monday" 3 "Tuesday" 4 "Wednsday" 5 "Thursday" 6 "Friday" 7 "Saturday" 8 "All Days Same" 9 "Mon - Fri Same" 10 "Sat & Sun Same" ;
VAL_ 2158116864 HVBTBDCRS_DlChSlctStat 0 "No Action" 1 "Departure Time 1" 2 "Reserved" 3 "Departure Time 1 Invalid" 4 "Reserved" 5 "Departure Time 2" 6 "Reserved" 7 "Departure Time 2 Invalid" 8 "Reserved" ;
VAL_ 2158116864 HVBTBDCRS_DlChSsnStat 3 "Yearly" 0 "No Action" 1 "Summer" 2 "Winter" ;
VAL_ 2158116864 HVBTBDCRS_DlChDStat 0 "No Action" 1 "Sunday" 2 "Monday" 3 "Tuesday" 4 "Wednsday" 5 "Thursday" 6 "Friday" 7 "Saturday" 8 "All Days Same" 9 "Mon - Fri Same" 10 "Sat & Sun Same" ;
VAL_ 2156281856 LftmEffDtRstRqd 1 "true" 0 "false" ;
VAL_ 2156281856 HTRCsStReq 4 "On Away" 3 "On Home" 2 "On" 1 "Off" 0 "No Action" ;
VAL_ 2156281856 TODCTmpImdtOvrdReq 2 "Active" 1 "Inactive" 0 "No Action" ;
VAL_ 2156281856 RtBsChrgCmplnTmPrfReq 2 "Latest Possible" 1 "Earliest Possible" 0 "No Action" ;
VAL_ 2156281856 TONPDTR_StTmpOvrAtv 0 "No Action" 1 "False (Inactive)" 2 "True (Active)" 3 "Unused and Reserved" ;
VAL_ 2156281856 TONPDTR_DyOfWk 0 "No Action" 1 "Unknown" 2 "Sunday" 3 "Monday" 4 "Tuesday" 5 "Wednesday" 6 "Thursday" 7 "Friday" 8 "Saturday" ;
VAL_ 2156281856 StTODChrgTmpOvrd 1 "true" 0 "false" ;
VAL_ 2156281856 HVBTBSCSR_SsnStReq 3 "Yearly" 0 "No Action" 1 "Summer" 2 "Winter" ;
VAL_ 2156281856 HVBTBSCSR_SsnSlStReq 0 "No Action" 1 "Selected Season" 2 "Start Season" 3 "End Season" ;
VAL_ 2156281856 HVBTBSCSR_SsnMthStReq 0 "No Action" 1 "January" 2 "February" 3 "Mars" 4 "April" 5 "May" 6 "June" 7 "July" 8 "August" 9 "September" 10 "October" 11 "November" 12 "December" ;
VAL_ 2156281856 HVBTBCRSR_ChRtSlStReq 0 "No Action" 1 "Low Rate" 2 "Medium Rate" 3 "High Rate" ;
VAL_ 2156281856 HVBTBCRSR_ChRtEnblStReq 0 "No Action" 1 "Enabled" 2 "Disabled" ;
VAL_ 2156281856 HVBTBCRSR_ChRtDStReq 0 "No Action" 1 "Sunday" 2 "Monday" 3 "Tuesday" 4 "Wednsday" 5 "Thursday" 6 "Friday" 7 "Saturday" 8 "All Days Same" 9 "Mon - Fri Same" 10 "Sat & Sun Same" ;
VAL_ 2156281856 HVBatTmBsChrgMdReq 0 "No Action" 1 "Charge Now" 2 "Delayed Charge" 3 "Rate Based Charge" ;
VAL_ 2156281856 HVChgSyChgLvlPrfSt 0 "No Action" 1 "No Reduction" 2 "Reduced Current Level 1" 3 "Reduced Current Level 2" 4 "Reduced Current Level 3" ;
VAL_ 2156265472 EngyUsgScrnMeasUtStat 15 "Unused and Reserved 9" 14 "Unused and Reserved 8" 13 "Unused and Reserved 7" 12 "Unused and Reserved 6" 11 "Unused and Reserved 5" 10 "Unused and Reserved 4" 9 "Unused and Reserved 3" 8 "Unused and Reserved 2" 7 "Unused and Reserved 1" 6 "km/L e Combined" 5 "km/L" 4 "L/100km e Combined" 3 "L/100km" 2 "MPGe Combined" 1 "MPG" 0 "No Action" ;
VAL_ 2156265472 OffBrdHVCVehCsChRq 1 "true" 0 "false" ;
VAL_ 2156265472 PrtyChrgRq 0 "No Action" 1 "False" 2 "True" ;
VAL_ 2156265472 HVBTBRCSR_RtChSlStReq 0 "No Action" 1 "Charge Start" 2 "Charge End" 3 "Charge Start Invalid" 4 "Charge End Invalid" ;
VAL_ 2156265472 HVBTBRCSR_RtChSlRtStReq 0 "No Action" 1 "Low Rate" 2 "Medium Rate" 3 "High Rate" 4 "Reserved 1" 5 "Invalid Rate" ;
VAL_ 2156265472 HVBTBRCSR_RtChSsnStReq 3 "Yearly" 0 "No Action" 1 "Summer" 2 "Winter" ;
VAL_ 2156265472 HVBTBRCSR_RtChDStReq 0 "No Action" 1 "Sunday" 2 "Monday" 3 "Tuesday" 4 "Wednsday" 5 "Thursday" 6 "Friday" 7 "Saturday" 8 "All Days Same" 9 "Mon - Fri Same" 10 "Sat & Sun Same" ;
VAL_ 2156265472 HVBTBDCSRQ_DlChSlStReq 0 "No Action" 1 "Departure Time 1" 2 "Reserved" 3 "Departure Time 1 Invalid" 4 "Reserved" 5 "Departure Time 2" 6 "Reserved" 7 "Departure Time 2 Invalid" 8 "Reserved" ;
VAL_ 2156265472 HVBTBDCSRQ_DlChSsnStReq 3 "Yearly" 0 "No Action" 1 "Summer" 2 "Winter" ;
VAL_ 2156265472 HVBTBDCSRQ_DlChDStReq 0 "No Action" 1 "Sunday" 2 "Monday" 3 "Tuesday" 4 "Wednsday" 5 "Thursday" 6 "Friday" 7 "Saturday" 8 "All Days Same" 9 "Mon - Fri Same" 10 "Sat & Sun Same" ;
VAL_ 2156265472 ChgPwLsAlCzStRq 0 "No Action" 1 "Off" 2 "On" 3 "Reserved 1" 4 "Reserved 2" 5 "Reserved 3" 6 "Reserved 4" 7 "Reserved 5" ;
VAL_ 2156265472 ChgCdTfAlCzStRq 0 "No Action" 1 "Off" 2 "On" 3 "Reserved 1" 4 "Reserved 2" 5 "Reserved 3" 6 "Reserved 4" 7 "Reserved 5" ;
VAL_ 2156265472 ChgSysAudInCsStReq 0 "No Action" 1 "Off" 2 "On" ;
VAL_ 2150113280 HVChrgInhbRsn 3 "See Charging Station" 2 "Charge Cord Lock Not Engaged" 1 "Charge Cord Not Fully Inserted" 0 "No Action" ;
VAL_ 2150113280 EngyStgSysActCoolEnb 1 "true" 0 "false" ;
VAL_ 2150055936 ClimCtrlHVDvcShtdwnCmd 1 "true" 0 "false" ;
VAL_ 2150039552 EvpCorOtltAirTmpCalcdV 1 "Invalid" 0 "Valid" ;
VAL_ 2150039552 ThrmlRefCompStat 0 "Normal Operation" 1 "Degraded Operation" 2 "Inoperative" 3 "Invalid" ;
VAL_ 2150039552 ThrmlRefCompSpdV 1 "Invalid" 0 "Valid" ;
VAL_ 2150039552 ThrmlRfCmpOvTmpFltPr 1 "true" 0 "false" ;
VAL_ 2151342080 PrkAstRtSysStat 0 "Disabled" 1 "Enabled" 2 "Inhibited" 3 "Failed" ;
VAL_ 2151342080 PARtRgn3ObjStat 0 "No Object" 1 "Zone 1" 2 "Zone 2" 3 "Zone 3" 4 "Zone 4" 5 "Zone 5" 6 "Zone 6" 7 "Zone 7" 8 "Zone 8" 9 "Zone 9" 10 "Zone 10" 11 "Zone 11" 12 "Zone 12" 13 "Zone 13" 14 "Zone 14" 15 "Zone 15" ;
VAL_ 2151342080 PARtRgn2ObjStat 0 "No Object" 1 "Zone 1" 2 "Zone 2" 3 "Zone 3" 4 "Zone 4" 5 "Zone 5" 6 "Zone 6" 7 "Zone 7" 8 "Zone 8" 9 "Zone 9" 10 "Zone 10" 11 "Zone 11" 12 "Zone 12" 13 "Zone 13" 14 "Zone 14" 15 "Zone 15" ;
VAL_ 2151342080 PARtRgn1ObjStat 0 "No Object" 1 "Zone 1" 2 "Zone 2" 3 "Zone 3" 4 "Zone 4" 5 "Zone 5" 6 "Zone 6" 7 "Zone 7" 8 "Zone 8" 9 "Zone 9" 10 "Zone 10" 11 "Zone 11" 12 "Zone 12" 13 "Zone 13" 14 "Zone 14" 15 "Zone 15" ;
VAL_ 2151325696 PrkAstLtSysStat 0 "Disabled" 1 "Enabled" 2 "Inhibited" 3 "Failed" ;
VAL_ 2151325696 PALtRgn3ObjStat 0 "No Object" 1 "Zone 1" 2 "Zone 2" 3 "Zone 3" 4 "Zone 4" 5 "Zone 5" 6 "Zone 6" 7 "Zone 7" 8 "Zone 8" 9 "Zone 9" 10 "Zone 10" 11 "Zone 11" 12 "Zone 12" 13 "Zone 13" 14 "Zone 14" 15 "Zone 15" ;
VAL_ 2151325696 PALtRgn2ObjStat 0 "No Object" 1 "Zone 1" 2 "Zone 2" 3 "Zone 3" 4 "Zone 4" 5 "Zone 5" 6 "Zone 6" 7 "Zone 7" 8 "Zone 8" 9 "Zone 9" 10 "Zone 10" 11 "Zone 11" 12 "Zone 12" 13 "Zone 13" 14 "Zone 14" 15 "Zone 15" ;
VAL_ 2151325696 PALtRgn1ObjStat 0 "No Object" 1 "Zone 1" 2 "Zone 2" 3 "Zone 3" 4 "Zone 4" 5 "Zone 5" 6 "Zone 6" 7 "Zone 7" 8 "Zone 8" 9 "Zone 9" 10 "Zone 10" 11 "Zone 11" 12 "Zone 12" 13 "Zone 13" 14 "Zone 14" 15 "Zone 15" ;
VAL_ 2150547456 OffBrdHVCVehPwrLvl 0 "None" 1 "Low" 2 "Medium" 3 "High" ;
VAL_ 2150547456 OffBrdHVCVehPwrDrtd 1 "true" 0 "false" ;
VAL_ 2150547456 OffBrdHVCVehCplrLkd 1 "true" 0 "false" ;
VAL_ 2150547456 OffBrdHVBlkChrgCmp 1 "true" 0 "false" ;
VAL_ 2150547456 ElecPrplsnMtrOvrSpdIO 1 "true" 0 "false" ;
VAL_ 2150547456 HVBatOutOfEnrgyInd 0 "No Action" 1 "Charge Vehicle Soon" 2 "Charge Vehicle Now" 3 "Out of Energy" ;
VAL_ 2150547456 CntrsOpnUndrTmpIO 1 "true" 0 "false" ;
VAL_ 2150547456 HVBatCntctrsOpnIO 1 "true" 0 "false" ;
VAL_ 2150547456 GrnAudQueReq 1 "true" 0 "false" ;
VAL_ 2150547456 SvcHybChrgSysIO 1 "true" 0 "false" ;
VAL_ 2150547456 HVChrgrSysStat 0 "Default" 1 "Idle" 2 "Initializing" 3 "Active" 4 "Complete" 5 "Aborted" ;
VAL_ 2150547456 HVChrgrCplrStat 0 "No Action" 1 "Disconnected" 2 "Connected" ;
VAL_ 2150547456 HVBatLimDTmpInd 0 "Normal" 1 "Cold" 2 "Hot" ;
VAL_ 2150547456 HVBatChrgCrdConnIO 1 "true" 0 "false" ;
VAL_ 2150547456 VehChrgMdSt 0 "Charge Depletion" 1 "Hold Charge Sustaining" 2 "Low SOC Charge Sustaining" ;
VAL_ 2150547456 ChgrSysAdblIndReq 0 "Inactive" 1 "Sequence 1" 2 "Sequence 2" 3 "Sequence 3" ;
VAL_ 2151489536 ACCLwVisbltyIO 1 "true" 0 "false" ;
VAL_ 2151489536 NVSysStat 7 "Needs Headlights" 6 "Temporarily Unavailable" 5 "Not Dark" 4 "Needs Service" 3 "Active" 2 "Inactive" 1 "Initializing" 0 "Unknown" ;
VAL_ 2151489536 RVBShtToPrkBfExtngVehIO 1 "true" 0 "false" ;
VAL_ 2151489536 RVBAutoBrkRlsIO 1 "true" 0 "false" ;
VAL_ 2149761024 PsngStPerfMdCsCrStVal 7 "Auto" 6 "Performance Mode 6" 5 "Performance Mode 5" 4 "Performance Mode 4" 3 "Performance Mode 3" 2 "Performance Mode 2" 1 "Performance Mode 1" 0 "No Action" ;
VAL_ 2149761024 PsngStPerfMdCsStAvl 1 "true" 0 "false" ;
VAL_ 2149761024 ElvtdIdlCstCrStVal 0 "No Action" 1 "Off" 2 "On" ;
VAL_ 2149761024 ElvtdIdlCstStAvl 1 "true" 0 "false" ;
VAL_ 2149761024 TCTPIR_DrvNotfn 15 "Indication 15" 14 "Indication 14" 13 "Indication 13" 12 "Indication 12" 11 "Indication 11" 10 "Indication 10" 9 "Indication 9" 8 "Indication 8" 7 "Indication 7" 6 "Indication 6" 5 "Indication 5" 4 "Indication 4" 3 "Indication 3" 2 "Indication 2" 1 "Indication 1" 0 "No Indication" ;
VAL_ 2149761024 TrlrStabAstActIO 1 "true" 0 "false" ;
VAL_ 2149761024 PerfTrcCrnExStngVal 0 "No Action" 1 "Off" 2 "Setting 1" 3 "Setting 2" 4 "Setting 3" 5 "Setting 4" 6 "Setting 5" 7 "Setting 6" 8 "Setting 7" 9 "Setting 8" 10 "Setting 9" 11 "Setting 10" 12 "Setting 11" 13 "Setting 12" 14 "Setting 13" 15 "Setting 14" 16 "Setting 15" ;
VAL_ 2149761024 ActVehAccelV 1 "Invalid" 0 "Valid" ;
VAL_ 2155012096 SODTmpUnavlbleIO 1 "true" 0 "false" ;
VAL_ 2155012096 SODSnsClnRqdIO 1 "true" 0 "false" ;
VAL_ 2155012096 SODRIC_Ind3 1 "true" 0 "false" ;
VAL_ 2155012096 SODRIC_Ind2 1 "true" 0 "false" ;
VAL_ 2155012096 SODRIC_Ind1 1 "true" 0 "false" ;
VAL_ 2155012096 SODRIC_IndReq 2 "Flashing Indication" 1 "Continuous Indication" 0 "Off" ;
VAL_ 2155012096 SrvSODSysIO 1 "true" 0 "false" ;
VAL_ 2150514688 SldngDrRgtStat 5 "Stopped" 4 "Closing" 3 "Opening" 2 "Closed" 1 "Full Open" 0 "Unknown" ;
VAL_ 2150514688 SldngDrLftStat 5 "Stopped" 4 "Closing" 3 "Opening" 2 "Closed" 1 "Full Open" 0 "Unknown" ;
VAL_ 2150514688 SdClsrObstclDtctdStat 1 "true" 0 "false" ;
VAL_ 2150514688 PwrSldngDrUnavlblIO 1 "true" 0 "false" ;
VAL_ 2158067712 TSDUAE_ScrnPrsdRq 1 "true" 0 "false" ;
VAL_ 2158067712 TSDUAE_RotBtnPsh 1 "true" 0 "false" ;
VAL_ 2158067712 TSDUAE_GrphStrkInfRq 70 "Left" 71 "Right" 72 "Next" 73 "Previous" 74 "V-mode" 3 "Enter" 4 "Escape" 5 "Number 0" 6 "Number 1" 7 "Number 2" 8 "Number 3" 9 "Number 4" 10 "Number 5" 11 "Number 6" 12 "Number 7" 13 "Number 8" 14 "Number 9" 15 "Character A" 16 "Character B" 17 "Character C" 18 "Character D" 19 "Character E" 20 "Character F" 21 "Character G" 22 "Character H" 23 "Character I" 24 "Character J" 25 "Character K" 26 "Character L" 27 "Character M" 28 "Character N" 29 "Character O" 30 "Character P" 31 "Character Q" 32 "Character R" 33 "Character S" 34 "Character T" 35 "Character U" 36 "Character V" 37 "Character W" 38 "Character X" 39 "Character Y" 40 "Character Z" 41 "Character a" 42 "Character b" 43 "Character c" 44 "Character d" 45 "Character e" 46 "Character f" 47 "Character g" 48 "Character h" 49 "Character i" 50 "Character j" 51 "Character k" 52 "Character l" 53 "Character m" 54 "Character n" 55 "Character o" 56 "Character p" 57 "Character q" 58 "Character r" 59 "Character s" 60 "Character t" 61 "Character u" 62 "Character v" 63 "Character w" 64 "Character x" 65 "Character y" 66 "Character z" 67 "Undo" 68 "Up" 69 "Down" ;
VAL_ 2158051328 VidSrcUICntrlStat 1 "Active" 0 "Inactive" ;
VAL_ 2158051328 VidMstrDsplyMd 2 "Split Screen" 1 "Full Screen" 0 "No Action" ;
VAL_ 2158051328 VidMstrSrcType 4 "Enhanced Driver Interface" 3 "Auxiliary Device" 2 "Rear Camera" 1 "Television" 0 "Video Supervisor" ;
VAL_ 2158051328 VidMstrArbCmd 3 "Connection Complete" 2 "Disconnect" 1 "Connect" 0 "No Action" ;
VAL_ 2158051328 TVDspCmd 0 "No Action" 1 "TV Image Screen" 2 "TV OSD Screen" ;
VAL_ 2158051328 RmtRcvrTunCmnd 22 "List Request" 21 "Audio Program Service Identifier" 20 "Auto Store" 19 "Station Delta within Program Type" 18 "Scan Program Type Down" 17 "Scan Program Type Up" 16 "Scan Preset Down" 15 "Scan Preset Up" 14 "Scan Down" 13 "Scan Up" 12 "Seek Preset Down" 11 "Seek Preset Up" 10 "Seek Program Type Down" 9 "Seek Program Type Up" 8 "Seek Down" 7 "Seek Up" 6 "Set Preset" 5 "Recall Preset Number" 4 "Program Type Delta" 3 "Program Type" 2 "Station Delta" 1 "Station" 0 "No Action" ;
VAL_ 2158051328 RemRcvrSrcInpCmd 3 "Auxiliary Jack 2" 2 "Auxiliary Jack 1" 1 "Television" 0 "No Action" ;
SIG_GROUP_ 2156298240 HVBatStrTmLwPwrChrg 1 : HVBSTLPC_MntOfHr HVBSTLPC_HrOfDy HVBSTLPC_DyOfWk;
SIG_GROUP_ 2156298240 HVBatStrTmHghPwrChrg 1 : HVBSTHPC_MntOfHr HVBSTHPC_HrOfDy HVBSTHPC_DyOfWk;
SIG_GROUP_ 2156298240 HVBatCmpltTmLwPwrChrg 1 : HVBCTLPC_MntOfHr HVBCTLPC_HrOfDy HVBCTLPC_DyOfWk;
SIG_GROUP_ 2156298240 HVBatCmpltTmHghPwrChrg 1 : HVBCTHPC_MntOfHr HVBCTHPC_HrOfDy HVBCTHPC_DyOfWk;
SIG_GROUP_ 2156298240 HVChrgSysDpTmExdSt 1 : HVCSDTES_NPDTIO HVCSDTES_LoPwrCIO HVCSDTES_HiPwrCIO;
SIG_GROUP_ 2149924864 ECODrvAsstDsplyStat 1 : EDADS_RcmndtFwdGr EDADS_CrntFwdMsdG EDADS_ShftIndStat EDADS_EcoDrvShftIO;
SIG_GROUP_ 2149924864 DrvSelMdSelnStat 1 : DSMSS_DrvSelMd0Pn DSMSS_DrvSelMd8Pn DSMSS_DrvSelMd7Pn DSMSS_DrvSelMd6Pn DSMSS_DrvSelMd5Pn DSMSS_DrvSelMd4Pn DSMSS_DrvSelMd3Pn DSMSS_DrvSelMd2Pn DSMSS_DrvSelMd1Pn DSMSS_DrvSelMd8Un DSMSS_DrvSelMd7Un DSMSS_DrvSelMd6Un DSMSS_DrvSelMd5Un DSMSS_DrvSelMd4Un DSMSS_DrvSelMd3Un DSMSS_DrvSelMd2Un DSMSS_DrvSelMd1Un;
SIG_GROUP_ 2149924864 ColPrepSysCustAvail 1 : CPSCA_Resrv3Avail CPSCA_Resrv2Avail CPSCA_Resrv1Avail CPSCA_AlrtBrkStrAvail CPSCA_AlrtBrkAvail CPSCA_AlrtAvail CPSCA_OffAvail;
SIG_GROUP_ 2154577920 AmpSnkStat 1 : ASS_DSPMd7Prsnt ASS_DSPMd6Prsnt ASS_DSPMd5Prsnt ASS_DSPMd4Prsnt ASS_DSPMd3Prsnt ASS_DSPMd2Prsnt ASS_DSPMd1Prsnt ASS_DSPMd0Prsnt ASS_SurndAvail ASS_DSPAvail ASS_VehNoisCmpnAvail ASS_PhLckdLpLckd ASS_MtxSnkMutStat;
SIG_GROUP_ 2154594304 AmpSetTonCtrl 1 : ASTC_GblAudSnkMut ASTC_AmpLwPwrSt ASTC_MtxSnkMutRmpTm ASTC_MtxSnkMut ASTC_DSPMd ASTC_VehNoisCmpnAct ASTC_SurndLvl ASTC_ChimSnkSpkrPos ASTC_ChimSnkLvl;
SIG_GROUP_ 2154586112 AmpSetSnkLvlCtrl 1 : ASSLC_AutoLdnsCmpnAct ASSLC_VcSrcActOnMtx ASSLC_MtxSnkTrbl ASSLC_MtxSnkMdrng ASSLC_MtxSnkBass ASSLC_MtxSnkFd ASSLC_MtxSnkBal ASSLC_FvSnkLvl ASSLC_AudFdbkSnkLvl ASSLC_MxPrmtSnkLvl ASSLC_MtxSnkLvl;
SIG_GROUP_ 2158149632 EngyCnsHsGrphCnfgDt 1 : ECHGCD_XAxTkMrkInterv ECHGCD_YAxMaxVal ECHGCD_MeasUt;
SIG_GROUP_ 2158149632 HVBatTmBsSsnChRsp 1 : HVBTBSCR_SsnDyStat HVBTBSCR_SsnStat HVBTBSCR_SsnSlctStat HVBTBSCR_SsnMthStat;
SIG_GROUP_ 2158149632 HVBatTmBsChrgRtRsp 1 : HVBTBCRS_ChRtDStat HVBTBCRS_ChRtSlctStat HVBTBCRS_ChRtEnblStat;
SIG_GROUP_ 2158116864 HVBatTmBsRtChrgRsp 1 : HVBTBRCR_RtCHSlctTblRwStat HVBTBRCR_RtChSlctStat HVBTBRCR_RtChSlRtStat HVBTBRCR_RtChSsnStat HVBTBRCR_RtChMHRsp HVBTBRCR_RtChHRsp HVBTBRCR_RtChDStat;
SIG_GROUP_ 2158116864 HVBatTmBsDelChrgRsp 1 : HVBTBDCRS_DlChSlctStat HVBTBDCRS_DlChSsnStat HVBTBDCRS_DlChMHRsp HVBTBDCRS_DlChHRsp HVBTBDCRS_DlChDStat;
SIG_GROUP_ 2156281856 TmpOvdNxtPlnDptTmRq 1 : TONPDTR_StTmpOvrAtv TONPDTR_MntOfHr TONPDTR_HrOfDy TONPDTR_DyOfWk;
SIG_GROUP_ 2156281856 HVBatTmBsSsnChStReq 1 : HVBTBSCSR_SsnStReq HVBTBSCSR_SsnSlStReq HVBTBSCSR_SsnMthStReq HVBTBSCSR_SsnDayStReq;
SIG_GROUP_ 2156281856 HVBatTmBsChrgRtStReq 1 : HVBTBCRSR_ChRtSlStReq HVBTBCRSR_ChRtEnblStReq HVBTBCRSR_ChRtDStReq;
SIG_GROUP_ 2156265472 HVBatTmBsRtChrgStReq 1 : HVBTBRCSR_RtChSlStReq HVBTBRCSR_RtChSlRtStReq HVBTBRCSR_RtChSsnStReq HVBTBRCSR_RtChMHStReq HVBTBRCSR_RtChHStReq HVBTBRCSR_RtChDStReq HVBTBRCSR_RtChSlTbRwReq;
SIG_GROUP_ 2156265472 HVBatTmBsDlChStReq 1 : HVBTBDCSRQ_DlChSlStReq HVBTBDCSRQ_DlChSsnStReq HVBTBDCSRQ_DlChMHStReq HVBTBDCSRQ_DlChHStReq HVBTBDCSRQ_DlChDStReq;
SIG_GROUP_ 2151809024 DrvCycElecEngyCnsmd 1 : DCEEC_EngyPct4 DCEEC_EngyPct3 DCEEC_EngyPct2 DCEEC_EngyPct1;
SIG_GROUP_ 2150547456 OffBrdHVBlkChgCpltTm 1 : OBHVBCCT_MinofHr OBHVBCCT_HrofDay OBHVBCCT_DayofWk;
SIG_GROUP_ 2149761024 TrnsCltchThrmlProtIndR 1 : TCTPIR_TnsEsClCDwT TCTPIR_TnsEsClTmpD TCTPIR_DrvNotfn;
SIG_GROUP_ 2155012096 SODRtIndCntl 1 : SODRIC_Ind3 SODRIC_Ind2 SODRIC_Ind1 SODRIC_IndReq;
SIG_GROUP_ 2158067712 TchScnDsplUsrActnExt 1 : TSDUAE_YCoOdntRq TSDUAE_XCoOdntRq TSDUAE_ScrnPrsdRq TSDUAE_RotEnc TSDUAE_RotBtnPsh TSDUAE_GrphStrkInfRq;
